[part 2 of 3: package /Svc_Dem]
AUTOSAR XML (schema 00047)
package /Svc_Dem  (continued)
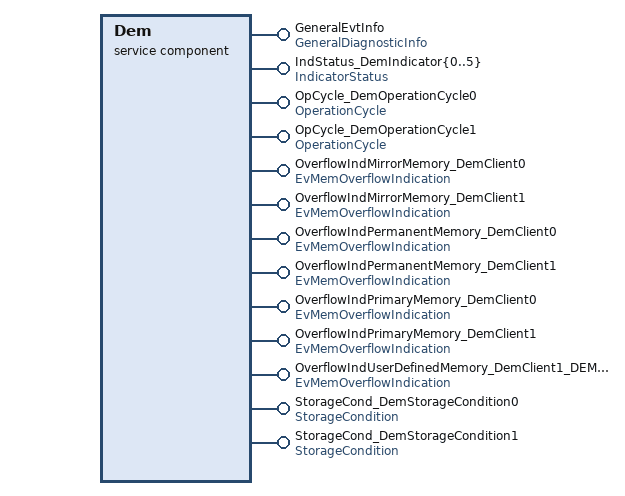
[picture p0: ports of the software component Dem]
  service sw component type Dem  (continued)
    18 x provide port:
      GeneralEvtInfo: provided-interface=GeneralDiagnosticInfo
        provided-com-specs:
          operation=GeneralDiagnosticInfo/GetDTCOfEvent, queue-length=1
          operation=GeneralDiagnosticInfo/GetDebouncingOfEvent, queue-length=1
          operation=GeneralDiagnosticInfo/GetEventUdsStatus, queue-length=1
          operation=GeneralDiagnosticInfo/GetFaultDetectionCounter, queue-length=1
          operation=GeneralDiagnosticInfo/GetMonitorStatus, queue-length=1
      IndStatus_DemIndicator{0..5}: server-com-spec{operation=GetIndicatorStatus, queue-length=1}, provided-interface=IndicatorStatus  # This port provides the Supervision interface of DemIndicator{0..5} to a SWC.
      OpCycle_DemOperationCycle0: provided-interface=OperationCycle  # This port provides the Supervision interface of DemOperationCycle0 to a SWC.
        provided-com-specs:
          operation=GetCycleQualified, queue-length=1
          operation=RestartOperationCycle, queue-length=1
          operation=SetCycleQualified, queue-length=1
      OpCycle_DemOperationCycle1: provided-interface=OperationCycle  # This port provides the Supervision interface of DemOperationCycle1 to a SWC.
        provided-com-specs:
          operation=GetCycleQualified, queue-length=1
          operation=RestartOperationCycle, queue-length=1
          operation=SetCycleQualified, queue-length=1
      OverflowIndMirrorMemory_DemClient0: provided-interface=EvMemOverflowIndication  # This port provides the Supervision interface of DemClient0 to a SWC.
        provided-com-specs:
          operation=GetEventMemoryOverflow, queue-length=1
          operation=GetNumberOfEventMemoryEntries, queue-length=1
      OverflowIndMirrorMemory_DemClient1: provided-interface=EvMemOverflowIndication  # This port provides the Supervision interface of DemClient1 to a SWC.
        provided-com-specs:
          operation=GetEventMemoryOverflow, queue-length=1
          operation=GetNumberOfEventMemoryEntries, queue-length=1
      OverflowIndPermanentMemory_DemClient0: provided-interface=EvMemOverflowIndication  # This port provides the Supervision interface of DemClient0 to a SWC.
        provided-com-specs:
          operation=GetEventMemoryOverflow, queue-length=1
          operation=GetNumberOfEventMemoryEntries, queue-length=1
      OverflowIndPermanentMemory_DemClient1: provided-interface=EvMemOverflowIndication  # This port provides the Supervision interface of DemClient1 to a SWC.
        provided-com-specs:
          operation=GetEventMemoryOverflow, queue-length=1
          operation=GetNumberOfEventMemoryEntries, queue-length=1
      OverflowIndPrimaryMemory_DemClient0: provided-interface=EvMemOverflowIndication  # This port provides the Supervision interface of DemClient0 to a SWC.
        provided-com-specs:
          operation=GetEventMemoryOverflow, queue-length=1
          operation=GetNumberOfEventMemoryEntries, queue-length=1
      OverflowIndPrimaryMemory_DemClient1: provided-interface=EvMemOverflowIndication  # This port provides the Supervision interface of DemClient1 to a SWC.
        provided-com-specs:
          operation=GetEventMemoryOverflow, queue-length=1
          operation=GetNumberOfEventMemoryEntries, queue-length=1
      OverflowIndUserDefinedMemory_DemClient1_DEMUSERDEFINEDMEMORY0: provided-interface=EvMemOverflowIndication
        provided-com-specs:
          operation=GetEventMemoryOverflow, queue-length=1
          operation=GetNumberOfEventMemoryEntries, queue-length=1
      StorageCond_DemStorageCondition0: server-com-spec{operation=SetStorageCondition, queue-length=1}, provided-interface=StorageCondition  # This port provides the Supervision interface of DemStorageCondition0 to a SWC.
      StorageCond_DemStorageCondition1: server-com-spec{operation=SetStorageCondition, queue-length=1}, provided-interface=StorageCondition  # This port provides the Supervision interface of DemStorageCondition1 to a SWC.
    behavior InternalBehavior: handle-termination-and-restart=NO-SUPPORT, included-data-type-set=data-type=[Dem_ComponentIdType, Dem_ConfigType, Dem_DTCFormatType, Dem_DTCKindType, Dem_DTCOriginType, Dem_DTCRequestType, Dem_DTCSeverityType, Dem_DTCTranslationFormatType, Dem_DTRControlType, Dem_DebounceResetStatusType, Dem_DebouncingStateType, Dem_EventIdType, Dem_EventStatusExtendedType, Dem_EventStatusType, Dem_IndicatorStatusType, Dem_InitMonitorReasonType, Dem_IumprDenomCondIdType, Dem_IumprDenomCondStatusType, Dem_MaxDataValueType, Dem_MonitorDataType, Dem_MonitorStatusType, Dem_PID21valueType, Dem_PID31valueType, Dem_RatioIdType, Dem_UdsStatusByteType]
      1431 x operation invoked event:
        OIE_ClearDTC_DemClient0_ClearDTC: start-on-event=ClearDTC, operation=ClearDTC_DemClient0.ClearDTC
        OIE_ClearDTC_DemClient0_SelectDTC: start-on-event=SelectDTC, operation=ClearDTC_DemClient0.SelectDTC
        OIE_ClearDTC_DemClient1_ClearDTC: start-on-event=ClearDTC, operation=ClearDTC_DemClient1.ClearDTC
        OIE_ClearDTC_DemClient1_SelectDTC: start-on-event=SelectDTC, operation=ClearDTC_DemClient1.SelectDTC
        OIE_ControlDTCSuppression_GetDTCSuppression: start-on-event=GetDTCSuppression, operation=ControlDTCSuppression.GetDTCSuppression
        OIE_ControlDTCSuppression_SetDTCSuppression: start-on-event=SetDTCSuppression, operation=ControlDTCSuppression.SetDTCSuppression
        OIE_ControlEventAvailable_CANCM_E_BAT_FAIL_SetEventAvailable: start-on-event=SetEventAvailable, operation=ControlEventAvailable_CANCM_E_BAT_FAIL.SetEventAvailable
        OIE_ControlEventAvailable_CANSM_E_BUS_OFF_FD_CAN1_SetEventAvailable: start-on-event=SetEventAvailable, operation=ControlEventAvailable_CANSM_E_BUS_OFF_FD_CAN1.SetEventAvailable
        OIE_ControlEventAvailable_CANSM_E_BUS_OFF_FD_CAN2_SetEventAvailable: start-on-event=SetEventAvailable, operation=ControlEventAvailable_CANSM_E_BUS_OFF_FD_CAN2.SetEventAvailable
        OIE_ControlEventAvailable_CANSM_E_BUS_OFF_HS_CAN1_SetEventAvailable: start-on-event=SetEventAvailable, operation=ControlEventAvailable_CANSM_E_BUS_OFF_HS_CAN1.SetEventAvailable
        OIE_ControlEventAvailable_CANSM_E_BUS_OFF_LS_CAN1_SetEventAvailable: start-on-event=SetEventAvailable, operation=ControlEventAvailable_CANSM_E_BUS_OFF_LS_CAN1.SetEventAvailable
        OIE_ControlEventAvailable_CANSM_E_BUS_OFF_Project_SetEventAvailable: start-on-event=SetEventAvailable, operation=ControlEventAvailable_CANSM_E_BUS_OFF_Project.SetEventAvailable
        OIE_ControlEventAvailable_CANSM_E_MODE_CHANGE_FD_CAN1_SetEventAvailable: start-on-event=SetEventAvailable, operation=ControlEventAvailable_CANSM_E_MODE_CHANGE_FD_CAN1.SetEventAvailable
        OIE_ControlEventAvailable_CANSM_E_MODE_CHANGE_FD_CAN2_SetEventAvailable: start-on-event=SetEventAvailable, operation=ControlEventAvailable_CANSM_E_MODE_CHANGE_FD_CAN2.SetEventAvailable
        OIE_ControlEventAvailable_CANSM_E_MODE_CHANGE_HS_CAN1_SetEventAvailable: start-on-event=SetEventAvailable, operation=ControlEventAvailable_CANSM_E_MODE_CHANGE_HS_CAN1.SetEventAvailable
        OIE_ControlEventAvailable_CANSM_E_MODE_CHANGE_LS_CAN1_SetEventAvailable: start-on-event=SetEventAvailable, operation=ControlEventAvailable_CANSM_E_MODE_CHANGE_LS_CAN1.SetEventAvailable
        OIE_ControlEventAvailable_CANSM_E_MODE_CHANGE_Project_SetEventAvailable: start-on-event=SetEventAvailable, operation=ControlEventAvailable_CANSM_E_MODE_CHANGE_Project.SetEventAvailable
        OIE_ControlEventAvailable_CANSM_E_MODE_REQUEST_TIMEOUT_FD_CAN1_SetEventAvailable: start-on-event=SetEventAvailable, operation=ControlEventAvailable_CANSM_E_MODE_REQUEST_TIMEOUT_FD_CAN1.SetEventAvailable
        OIE_ControlEventAvailable_CANSM_E_MODE_REQUEST_TIMEOUT_HS_CAN1_SetEventAvailable: start-on-event=SetEventAvailable, operation=ControlEventAvailable_CANSM_E_MODE_REQUEST_TIMEOUT_HS_CAN1.SetEventAvailable
        OIE_ControlEventAvailable_DEM_E_TEST_EVENT{10..19}_SetEventAvailable: start-on-event=SetEventAvailable, operation=ControlEventAvailable_DEM_E_TEST_EVENT{10..19}.SetEventAvailable
        OIE_ControlEventAvailable_DEM_E_TEST_EVENT1_SetEventAvailable: start-on-event=SetEventAvailable, operation=ControlEventAvailable_DEM_E_TEST_EVENT1.SetEventAvailable
        OIE_ControlEventAvailable_DEM_E_TEST_EVENT{20..22}_SetEventAvailable: start-on-event=SetEventAvailable, operation=ControlEventAvailable_DEM_E_TEST_EVENT{20..22}.SetEventAvailable
        OIE_ControlEventAvailable_DEM_E_TEST_EVENT{2..9}_SetEventAvailable: start-on-event=SetEventAvailable, operation=ControlEventAvailable_DEM_E_TEST_EVENT{2..9}.SetEventAvailable
        OIE_ControlEventAvailable_DEM_E_TEST_EVENT_E2EXF_MALFORMED_MESSAGE_SetEventAvailable: start-on-event=SetEventAvailable, operation=ControlEventAvailable_DEM_E_TEST_EVENT_E2EXF_MALFORMED_MESSAGE.SetEventAvailable
        OIE_ControlEventAvailable_DEM_E_TEST_EVENT_SOMEIPXF_MALFORMED_MESSAGE_SetEventAvailable: start-on-event=SetEventAvailable, operation=ControlEventAvailable_DEM_E_TEST_EVENT_SOMEIPXF_MALFORMED_MESSAGE.SetEventAvailable
        OIE_ControlEventAvailable_ECUM_E_CONFIGURATION_DATA_INCONSISTENT_SetEventAvailable: start-on-event=SetEventAvailable, operation=ControlEventAvailable_ECUM_E_CONFIGURATION_DATA_INCONSISTENT.SetEventAvailable
        OIE_ControlEventAvailable_ECUM_E_IMPROPER_CALLER_SetEventAvailable: start-on-event=SetEventAvailable, operation=ControlEventAvailable_ECUM_E_IMPROPER_CALLER.SetEventAvailable
        OIE_ControlEventAvailable_ECUM_E_RAM_CHECK_FAILED_SetEventAvailable: start-on-event=SetEventAvailable, operation=ControlEventAvailable_ECUM_E_RAM_CHECK_FAILED.SetEventAvailable
        OIE_ControlEventAvailable_EEP_E_COMPARE_FAILED_SetEventAvailable: start-on-event=SetEventAvailable, operation=ControlEventAvailable_EEP_E_COMPARE_FAILED.SetEventAvailable
        OIE_ControlEventAvailable_EEP_E_ERASE_FAILED_SetEventAvailable: start-on-event=SetEventAvailable, operation=ControlEventAvailable_EEP_E_ERASE_FAILED.SetEventAvailable
        OIE_ControlEventAvailable_EEP_E_READ_FAILED_SetEventAvailable: start-on-event=SetEventAvailable, operation=ControlEventAvailable_EEP_E_READ_FAILED.SetEventAvailable
        OIE_ControlEventAvailable_EEP_E_WRITE_FAILED_SetEventAvailable: start-on-event=SetEventAvailable, operation=ControlEventAvailable_EEP_E_WRITE_FAILED.SetEventAvailable
        OIE_ControlEventAvailable_ETHSM_E_LINK_DOWN_SetEventAvailable: start-on-event=SetEventAvailable, operation=ControlEventAvailable_ETHSM_E_LINK_DOWN.SetEventAvailable
        OIE_ControlEventAvailable_ETHTRCV_E_ACCESS_SetEventAvailable: start-on-event=SetEventAvailable, operation=ControlEventAvailable_ETHTRCV_E_ACCESS.SetEventAvailable
        OIE_ControlEventAvailable_ETH_E_ACCESS_SetEventAvailable: start-on-event=SetEventAvailable, operation=ControlEventAvailable_ETH_E_ACCESS.SetEventAvailable
        OIE_ControlEventAvailable_ETH_E_ALIGNMENT_SetEventAvailable: start-on-event=SetEventAvailable, operation=ControlEventAvailable_ETH_E_ALIGNMENT.SetEventAvailable
        OIE_ControlEventAvailable_ETH_E_CRC_SetEventAvailable: start-on-event=SetEventAvailable, operation=ControlEventAvailable_ETH_E_CRC.SetEventAvailable
        OIE_ControlEventAvailable_ETH_E_LATECOLLISON_SetEventAvailable: start-on-event=SetEventAvailable, operation=ControlEventAvailable_ETH_E_LATECOLLISON.SetEventAvailable
        OIE_ControlEventAvailable_ETH_E_MULTIPLECOLLISION_SetEventAvailable: start-on-event=SetEventAvailable, operation=ControlEventAvailable_ETH_E_MULTIPLECOLLISION.SetEventAvailable
        OIE_ControlEventAvailable_ETH_E_OVERSIZEFRAME_SetEventAvailable: start-on-event=SetEventAvailable, operation=ControlEventAvailable_ETH_E_OVERSIZEFRAME.SetEventAvailable
        OIE_ControlEventAvailable_ETH_E_RX_FRAMES_LOST_SetEventAvailable: start-on-event=SetEventAvailable, operation=ControlEventAvailable_ETH_E_RX_FRAMES_LOST.SetEventAvailable
        OIE_ControlEventAvailable_ETH_E_SINGLECOLLISION_SetEventAvailable: start-on-event=SetEventAvailable, operation=ControlEventAvailable_ETH_E_SINGLECOLLISION.SetEventAvailable
        OIE_ControlEventAvailable_ETH_E_UNDERSIZRFRAME_SetEventAvailable: start-on-event=SetEventAvailable, operation=ControlEventAvailable_ETH_E_UNDERSIZRFRAME.SetEventAvailable
        OIE_ControlEventAvailable_FEE_E_GC_ERASE_SetEventAvailable: start-on-event=SetEventAvailable, operation=ControlEventAvailable_FEE_E_GC_ERASE.SetEventAvailable
        OIE_ControlEventAvailable_FEE_E_GC_INIT_SetEventAvailable: start-on-event=SetEventAvailable, operation=ControlEventAvailable_FEE_E_GC_INIT.SetEventAvailable
        OIE_ControlEventAvailable_FEE_E_GC_READ_SetEventAvailable: start-on-event=SetEventAvailable, operation=ControlEventAvailable_FEE_E_GC_READ.SetEventAvailable
        OIE_ControlEventAvailable_FEE_E_GC_TRIG_SetEventAvailable: start-on-event=SetEventAvailable, operation=ControlEventAvailable_FEE_E_GC_TRIG.SetEventAvailable
        OIE_ControlEventAvailable_FEE_E_GC_WRITE_SetEventAvailable: start-on-event=SetEventAvailable, operation=ControlEventAvailable_FEE_E_GC_WRITE.SetEventAvailable
        OIE_ControlEventAvailable_FEE_E_INVALIDATE_SetEventAvailable: start-on-event=SetEventAvailable, operation=ControlEventAvailable_FEE_E_INVALIDATE.SetEventAvailable
        OIE_ControlEventAvailable_FEE_E_READ_SetEventAvailable: start-on-event=SetEventAvailable, operation=ControlEventAvailable_FEE_E_READ.SetEventAvailable
        OIE_ControlEventAvailable_FEE_E_UNCONFIG_BLK_EXCEEDED_SetEventAvailable: start-on-event=SetEventAvailable, operation=ControlEventAvailable_FEE_E_UNCONFIG_BLK_EXCEEDED.SetEventAvailable
        OIE_ControlEventAvailable_FEE_E_WRITE_CYCLES_EXHAUSTED_SetEventAvailable: start-on-event=SetEventAvailable, operation=ControlEventAvailable_FEE_E_WRITE_CYCLES_EXHAUSTED.SetEventAvailable
        OIE_ControlEventAvailable_FEE_E_WRITE_SetEventAvailable: start-on-event=SetEventAvailable, operation=ControlEventAvailable_FEE_E_WRITE.SetEventAvailable
        OIE_ControlEventAvailable_FLS_E_COMPARE_FAILED_SetEventAvailable: start-on-event=SetEventAvailable, operation=ControlEventAvailable_FLS_E_COMPARE_FAILED.SetEventAvailable
        OIE_ControlEventAvailable_FLS_E_ERASE_FAILED_SetEventAvailable: start-on-event=SetEventAvailable, operation=ControlEventAvailable_FLS_E_ERASE_FAILED.SetEventAvailable
        OIE_ControlEventAvailable_FLS_E_READ_FAILED_SetEventAvailable: start-on-event=SetEventAvailable, operation=ControlEventAvailable_FLS_E_READ_FAILED.SetEventAvailable
        OIE_ControlEventAvailable_FLS_E_UNEXPECTED_FLASH_ID_SetEventAvailable: start-on-event=SetEventAvailable, operation=ControlEventAvailable_FLS_E_UNEXPECTED_FLASH_ID.SetEventAvailable
        OIE_ControlEventAvailable_FLS_E_WRITE_FAILED_SetEventAvailable: start-on-event=SetEventAvailable, operation=ControlEventAvailable_FLS_E_WRITE_FAILED.SetEventAvailable
        OIE_ControlEventAvailable_IOHWAB_E_BUSY_SetEventAvailable: start-on-event=SetEventAvailable, operation=ControlEventAvailable_IOHWAB_E_BUSY.SetEventAvailable
        OIE_ControlEventAvailable_IOHWAB_E_PROC_FAIL_SetEventAvailable: start-on-event=SetEventAvailable, operation=ControlEventAvailable_IOHWAB_E_PROC_FAIL.SetEventAvailable
        OIE_ControlEventAvailable_IOHWAB_E_SETUP_FAIL_SetEventAvailable: start-on-event=SetEventAvailable, operation=ControlEventAvailable_IOHWAB_E_SETUP_FAIL.SetEventAvailable
        OIE_ControlEventAvailable_IOHWAB_E_WRONG_PARAM_SetEventAvailable: start-on-event=SetEventAvailable, operation=ControlEventAvailable_IOHWAB_E_WRONG_PARAM.SetEventAvailable
        OIE_ControlEventAvailable_IOHWAB_E_WRONG_SETTING_SetEventAvailable: start-on-event=SetEventAvailable, operation=ControlEventAvailable_IOHWAB_E_WRONG_SETTING.SetEventAvailable
        OIE_ControlEventAvailable_IOHWAB_E_WRONG_STATE_SetEventAvailable: start-on-event=SetEventAvailable, operation=ControlEventAvailable_IOHWAB_E_WRONG_STATE.SetEventAvailable
        OIE_ControlEventAvailable_MCU_E_CCU6_CLC_DISABLE_ERR_SetEventAvailable: start-on-event=SetEventAvailable, operation=ControlEventAvailable_MCU_E_CCU6_CLC_DISABLE_ERR.SetEventAvailable
        OIE_ControlEventAvailable_MCU_E_CCU6_CLC_ENABLE_ERR_SetEventAvailable: start-on-event=SetEventAvailable, operation=ControlEventAvailable_MCU_E_CCU6_CLC_ENABLE_ERR.SetEventAvailable
        OIE_ControlEventAvailable_MCU_E_CCUCON_UPDATE_ERR_SetEventAvailable: start-on-event=SetEventAvailable, operation=ControlEventAvailable_MCU_E_CCUCON_UPDATE_ERR.SetEventAvailable
        OIE_ControlEventAvailable_MCU_E_CLOCK_FAILURE_SetEventAvailable: start-on-event=SetEventAvailable, operation=ControlEventAvailable_MCU_E_CLOCK_FAILURE.SetEventAvailable
        OIE_ControlEventAvailable_MCU_E_CONVCTRL_CLC_DISABLE_ERR_SetEventAvailable: start-on-event=SetEventAvailable, operation=ControlEventAvailable_MCU_E_CONVCTRL_CLC_DISABLE_ERR.SetEventAvailable
        OIE_ControlEventAvailable_MCU_E_CONVCTRL_CLC_ENABLE_ERR_SetEventAvailable: start-on-event=SetEventAvailable, operation=ControlEventAvailable_MCU_E_CONVCTRL_CLC_ENABLE_ERR.SetEventAvailable
        OIE_ControlEventAvailable_MCU_E_GPT12_CLC_DISABLE_ERR_SetEventAvailable: start-on-event=SetEventAvailable, operation=ControlEventAvailable_MCU_E_GPT12_CLC_DISABLE_ERR.SetEventAvailable
        OIE_ControlEventAvailable_MCU_E_GPT12_CLC_ENABLE_ERR_SetEventAvailable: start-on-event=SetEventAvailable, operation=ControlEventAvailable_MCU_E_GPT12_CLC_ENABLE_ERR.SetEventAvailable
        OIE_ControlEventAvailable_MCU_E_GTM_CLC_DISABLE_ERR_SetEventAvailable: start-on-event=SetEventAvailable, operation=ControlEventAvailable_MCU_E_GTM_CLC_DISABLE_ERR.SetEventAvailable
        OIE_ControlEventAvailable_MCU_E_GTM_CLC_ENABLE_ERR_SetEventAvailable: start-on-event=SetEventAvailable, operation=ControlEventAvailable_MCU_E_GTM_CLC_ENABLE_ERR.SetEventAvailable
        OIE_ControlEventAvailable_MCU_E_OSC_FAILURE_SetEventAvailable: start-on-event=SetEventAvailable, operation=ControlEventAvailable_MCU_E_OSC_FAILURE.SetEventAvailable
        OIE_ControlEventAvailable_MCU_E_PERIPHERAL_PLL_LOCK_LOSS_SetEventAvailable: start-on-event=SetEventAvailable, operation=ControlEventAvailable_MCU_E_PERIPHERAL_PLL_LOCK_LOSS.SetEventAvailable
        OIE_ControlEventAvailable_MCU_E_PERIPHERAL_PLL_TIMEOUT_ERR_SetEventAvailable: start-on-event=SetEventAvailable, operation=ControlEventAvailable_MCU_E_PERIPHERAL_PLL_TIMEOUT_ERR.SetEventAvailable
        OIE_ControlEventAvailable_MCU_E_PMSWCR_UPDATE_ERR_SetEventAvailable: start-on-event=SetEventAvailable, operation=ControlEventAvailable_MCU_E_PMSWCR_UPDATE_ERR.SetEventAvailable
        OIE_ControlEventAvailable_MCU_E_SYSTEM_PLL_LOCK_LOSS_SetEventAvailable: start-on-event=SetEventAvailable, operation=ControlEventAvailable_MCU_E_SYSTEM_PLL_LOCK_LOSS.SetEventAvailable
        OIE_ControlEventAvailable_MCU_E_SYSTEM_PLL_TIMEOUT_ERR_SetEventAvailable: start-on-event=SetEventAvailable, operation=ControlEventAvailable_MCU_E_SYSTEM_PLL_TIMEOUT_ERR.SetEventAvailable
        OIE_ControlEventAvailable_NVM_E_INTEGRITY_FAILED_SetEventAvailable: start-on-event=SetEventAvailable, operation=ControlEventAvailable_NVM_E_INTEGRITY_FAILED.SetEventAvailable
        OIE_ControlEventAvailable_NVM_E_LOSS_OF_REDUNDANCY_SetEventAvailable: start-on-event=SetEventAvailable, operation=ControlEventAvailable_NVM_E_LOSS_OF_REDUNDANCY.SetEventAvailable
        OIE_ControlEventAvailable_NVM_E_QUEUE_OVERFLOW_SetEventAvailable: start-on-event=SetEventAvailable, operation=ControlEventAvailable_NVM_E_QUEUE_OVERFLOW.SetEventAvailable
        OIE_ControlEventAvailable_NVM_E_REQ_FAILED_SetEventAvailable: start-on-event=SetEventAvailable, operation=ControlEventAvailable_NVM_E_REQ_FAILED.SetEventAvailable
        OIE_ControlEventAvailable_NVM_E_VERIFY_FAILED_SetEventAvailable: start-on-event=SetEventAvailable, operation=ControlEventAvailable_NVM_E_VERIFY_FAILED.SetEventAvailable
        OIE_ControlEventAvailable_NVM_E_WRITE_PROTECTED_SetEventAvailable: start-on-event=SetEventAvailable, operation=ControlEventAvailable_NVM_E_WRITE_PROTECTED.SetEventAvailable
        OIE_ControlEventAvailable_NVM_E_WRONG_BLOCK_ID_SetEventAvailable: start-on-event=SetEventAvailable, operation=ControlEventAvailable_NVM_E_WRONG_BLOCK_ID.SetEventAvailable
        OIE_ControlEventAvailable_SPI_E_HARDWARE_ERROR_SetEventAvailable: start-on-event=SetEventAvailable, operation=ControlEventAvailable_SPI_E_HARDWARE_ERROR.SetEventAvailable
        OIE_ControlEventAvailable_WDGM_E_IMPROPER_CALLER_SetEventAvailable: start-on-event=SetEventAvailable, operation=ControlEventAvailable_WDGM_E_IMPROPER_CALLER.SetEventAvailable
        OIE_ControlEventAvailable_WDGM_E_MONITORING_SetEventAvailable: start-on-event=SetEventAvailable, operation=ControlEventAvailable_WDGM_E_MONITORING.SetEventAvailable
        OIE_ControlEventAvailable_WDGM_E_SET_MODE_SetEventAvailable: start-on-event=SetEventAvailable, operation=ControlEventAvailable_WDGM_E_SET_MODE.SetEventAvailable
        OIE_ControlEventAvailable_WDG_76_ACW_E_DISABLE_REJECTED_SetEventAvailable: start-on-event=SetEventAvailable, operation=ControlEventAvailable_WDG_76_ACW_E_DISABLE_REJECTED.SetEventAvailable
        OIE_ControlEventAvailable_WDG_76_ACW_E_MODE_FAILED_SetEventAvailable: start-on-event=SetEventAvailable, operation=ControlEventAvailable_WDG_76_ACW_E_MODE_FAILED.SetEventAvailable
        OIE_ControlEventAvailable_WDG_E_DISABLE_REJECTED_SetEventAvailable: start-on-event=SetEventAvailable, operation=ControlEventAvailable_WDG_E_DISABLE_REJECTED.SetEventAvailable
        OIE_ControlEventAvailable_WDG_E_MODE_FAILED_SetEventAvailable: start-on-event=SetEventAvailable, operation=ControlEventAvailable_WDG_E_MODE_FAILED.SetEventAvailable
        OIE_DiagnosticMonitor_MonitorData_CANCM_E_BAT_FAIL_SetEventStatusWithMonitorData: start-on-event=SetEventStatusWithMonitorData, operation=DiagnosticMonitor_MonitorData_CANCM_E_BAT_FAIL.SetEventStatusWithMonitorData
        OIE_DiagnosticMonitor_MonitorData_CANSM_E_BUS_OFF_FD_CAN1_SetEventStatusWithMonitorData: start-on-event=SetEventStatusWithMonitorData, operation=DiagnosticMonitor_MonitorData_CANSM_E_BUS_OFF_FD_CAN1.SetEventStatusWithMonitorData
        OIE_DiagnosticMonitor_MonitorData_CANSM_E_BUS_OFF_FD_CAN2_SetEventStatusWithMonitorData: start-on-event=SetEventStatusWithMonitorData, operation=DiagnosticMonitor_MonitorData_CANSM_E_BUS_OFF_FD_CAN2.SetEventStatusWithMonitorData
        OIE_DiagnosticMonitor_MonitorData_CANSM_E_BUS_OFF_HS_CAN1_SetEventStatusWithMonitorData: start-on-event=SetEventStatusWithMonitorData, operation=DiagnosticMonitor_MonitorData_CANSM_E_BUS_OFF_HS_CAN1.SetEventStatusWithMonitorData
        OIE_DiagnosticMonitor_MonitorData_CANSM_E_BUS_OFF_LS_CAN1_SetEventStatusWithMonitorData: start-on-event=SetEventStatusWithMonitorData, operation=DiagnosticMonitor_MonitorData_CANSM_E_BUS_OFF_LS_CAN1.SetEventStatusWithMonitorData
        OIE_DiagnosticMonitor_MonitorData_CANSM_E_BUS_OFF_Project_SetEventStatusWithMonitorData: start-on-event=SetEventStatusWithMonitorData, operation=DiagnosticMonitor_MonitorData_CANSM_E_BUS_OFF_Project.SetEventStatusWithMonitorData
        OIE_DiagnosticMonitor_MonitorData_CANSM_E_MODE_CHANGE_FD_CAN1_SetEventStatusWithMonitorData: start-on-event=SetEventStatusWithMonitorData, operation=DiagnosticMonitor_MonitorData_CANSM_E_MODE_CHANGE_FD_CAN1.SetEventStatusWithMonitorData
        OIE_DiagnosticMonitor_MonitorData_CANSM_E_MODE_CHANGE_FD_CAN2_SetEventStatusWithMonitorData: start-on-event=SetEventStatusWithMonitorData, operation=DiagnosticMonitor_MonitorData_CANSM_E_MODE_CHANGE_FD_CAN2.SetEventStatusWithMonitorData
        OIE_DiagnosticMonitor_MonitorData_CANSM_E_MODE_CHANGE_HS_CAN1_SetEventStatusWithMonitorData: start-on-event=SetEventStatusWithMonitorData, operation=DiagnosticMonitor_MonitorData_CANSM_E_MODE_CHANGE_HS_CAN1.SetEventStatusWithMonitorData
        OIE_DiagnosticMonitor_MonitorData_CANSM_E_MODE_CHANGE_LS_CAN1_SetEventStatusWithMonitorData: start-on-event=SetEventStatusWithMonitorData, operation=DiagnosticMonitor_MonitorData_CANSM_E_MODE_CHANGE_LS_CAN1.SetEventStatusWithMonitorData
        OIE_DiagnosticMonitor_MonitorData_CANSM_E_MODE_CHANGE_Project_SetEventStatusWithMonitorData: start-on-event=SetEventStatusWithMonitorData, operation=DiagnosticMonitor_MonitorData_CANSM_E_MODE_CHANGE_Project.SetEventStatusWithMonitorData
        OIE_DiagnosticMonitor_MonitorData_CANSM_E_MODE_REQUEST_TIMEOUT_FD_CAN1_SetEventStatusWithMonitorData: start-on-event=SetEventStatusWithMonitorData, operation=DiagnosticMonitor_MonitorData_CANSM_E_MODE_REQUEST_TIMEOUT_FD_CAN1.SetEventStatusWithMonitorData
        OIE_DiagnosticMonitor_MonitorData_CANSM_E_MODE_REQUEST_TIMEOUT_HS_CAN1_SetEventStatusWithMonitorData: start-on-event=SetEventStatusWithMonitorData, operation=DiagnosticMonitor_MonitorData_CANSM_E_MODE_REQUEST_TIMEOUT_HS_CAN1.SetEventStatusWithMonitorData
        OIE_DiagnosticMonitor_MonitorData_DEM_E_TEST_EVENT{10..19}_SetEventStatusWithMonitorData: start-on-event=SetEventStatusWithMonitorData, operation=DiagnosticMonitor_MonitorData_DEM_E_TEST_EVENT{10..19}.SetEventStatusWithMonitorData
        OIE_DiagnosticMonitor_MonitorData_DEM_E_TEST_EVENT1_SetEventStatusWithMonitorData: start-on-event=SetEventStatusWithMonitorData, operation=DiagnosticMonitor_MonitorData_DEM_E_TEST_EVENT1.SetEventStatusWithMonitorData
        OIE_DiagnosticMonitor_MonitorData_DEM_E_TEST_EVENT{20..22}_SetEventStatusWithMonitorData: start-on-event=SetEventStatusWithMonitorData, operation=DiagnosticMonitor_MonitorData_DEM_E_TEST_EVENT{20..22}.SetEventStatusWithMonitorData
        OIE_DiagnosticMonitor_MonitorData_DEM_E_TEST_EVENT{2..9}_SetEventStatusWithMonitorData: start-on-event=SetEventStatusWithMonitorData, operation=DiagnosticMonitor_MonitorData_DEM_E_TEST_EVENT{2..9}.SetEventStatusWithMonitorData
        OIE_DiagnosticMonitor_MonitorData_DEM_E_TEST_EVENT_E2EXF_MALFORMED_MESSAGE_SetEventStatusWithMonitorData: start-on-event=SetEventStatusWithMonitorData, operation=DiagnosticMonitor_MonitorData_DEM_E_TEST_EVENT_E2EXF_MALFORMED_MESSAGE.SetEventStatusWithMonitorData
        OIE_DiagnosticMonitor_MonitorData_DEM_E_TEST_EVENT_SOMEIPXF_MALFORMED_MESSAGE_SetEventStatusWithMonitorData: start-on-event=SetEventStatusWithMonitorData, operation=DiagnosticMonitor_MonitorData_DEM_E_TEST_EVENT_SOMEIPXF_MALFORMED_MESSAGE.SetEventStatusWithMonitorData
        OIE_DiagnosticMonitor_MonitorData_ECUM_E_CONFIGURATION_DATA_INCONSISTENT_SetEventStatusWithMonitorData: start-on-event=SetEventStatusWithMonitorData, operation=DiagnosticMonitor_MonitorData_ECUM_E_CONFIGURATION_DATA_INCONSISTENT.SetEventStatusWithMonitorData
        OIE_DiagnosticMonitor_MonitorData_ECUM_E_IMPROPER_CALLER_SetEventStatusWithMonitorData: start-on-event=SetEventStatusWithMonitorData, operation=DiagnosticMonitor_MonitorData_ECUM_E_IMPROPER_CALLER.SetEventStatusWithMonitorData
        OIE_DiagnosticMonitor_MonitorData_ECUM_E_RAM_CHECK_FAILED_SetEventStatusWithMonitorData: start-on-event=SetEventStatusWithMonitorData, operation=DiagnosticMonitor_MonitorData_ECUM_E_RAM_CHECK_FAILED.SetEventStatusWithMonitorData
        OIE_DiagnosticMonitor_MonitorData_EEP_E_COMPARE_FAILED_SetEventStatusWithMonitorData: start-on-event=SetEventStatusWithMonitorData, operation=DiagnosticMonitor_MonitorData_EEP_E_COMPARE_FAILED.SetEventStatusWithMonitorData
        OIE_DiagnosticMonitor_MonitorData_EEP_E_ERASE_FAILED_SetEventStatusWithMonitorData: start-on-event=SetEventStatusWithMonitorData, operation=DiagnosticMonitor_MonitorData_EEP_E_ERASE_FAILED.SetEventStatusWithMonitorData
        OIE_DiagnosticMonitor_MonitorData_EEP_E_READ_FAILED_SetEventStatusWithMonitorData: start-on-event=SetEventStatusWithMonitorData, operation=DiagnosticMonitor_MonitorData_EEP_E_READ_FAILED.SetEventStatusWithMonitorData
        OIE_DiagnosticMonitor_MonitorData_EEP_E_WRITE_FAILED_SetEventStatusWithMonitorData: start-on-event=SetEventStatusWithMonitorData, operation=DiagnosticMonitor_MonitorData_EEP_E_WRITE_FAILED.SetEventStatusWithMonitorData
        OIE_DiagnosticMonitor_MonitorData_ETHSM_E_LINK_DOWN_SetEventStatusWithMonitorData: start-on-event=SetEventStatusWithMonitorData, operation=DiagnosticMonitor_MonitorData_ETHSM_E_LINK_DOWN.SetEventStatusWithMonitorData
        OIE_DiagnosticMonitor_MonitorData_ETHTRCV_E_ACCESS_SetEventStatusWithMonitorData: start-on-event=SetEventStatusWithMonitorData, operation=DiagnosticMonitor_MonitorData_ETHTRCV_E_ACCESS.SetEventStatusWithMonitorData
        OIE_DiagnosticMonitor_MonitorData_ETH_E_ACCESS_SetEventStatusWithMonitorData: start-on-event=SetEventStatusWithMonitorData, operation=DiagnosticMonitor_MonitorData_ETH_E_ACCESS.SetEventStatusWithMonitorData
        OIE_DiagnosticMonitor_MonitorData_ETH_E_ALIGNMENT_SetEventStatusWithMonitorData: start-on-event=SetEventStatusWithMonitorData, operation=DiagnosticMonitor_MonitorData_ETH_E_ALIGNMENT.SetEventStatusWithMonitorData
        OIE_DiagnosticMonitor_MonitorData_ETH_E_CRC_SetEventStatusWithMonitorData: start-on-event=SetEventStatusWithMonitorData, operation=DiagnosticMonitor_MonitorData_ETH_E_CRC.SetEventStatusWithMonitorData
        OIE_DiagnosticMonitor_MonitorData_ETH_E_LATECOLLISON_SetEventStatusWithMonitorData: start-on-event=SetEventStatusWithMonitorData, operation=DiagnosticMonitor_MonitorData_ETH_E_LATECOLLISON.SetEventStatusWithMonitorData
        OIE_DiagnosticMonitor_MonitorData_ETH_E_MULTIPLECOLLISION_SetEventStatusWithMonitorData: start-on-event=SetEventStatusWithMonitorData, operation=DiagnosticMonitor_MonitorData_ETH_E_MULTIPLECOLLISION.SetEventStatusWithMonitorData
        OIE_DiagnosticMonitor_MonitorData_ETH_E_OVERSIZEFRAME_SetEventStatusWithMonitorData: start-on-event=SetEventStatusWithMonitorData, operation=DiagnosticMonitor_MonitorData_ETH_E_OVERSIZEFRAME.SetEventStatusWithMonitorData
        OIE_DiagnosticMonitor_MonitorData_ETH_E_RX_FRAMES_LOST_SetEventStatusWithMonitorData: start-on-event=SetEventStatusWithMonitorData, operation=DiagnosticMonitor_MonitorData_ETH_E_RX_FRAMES_LOST.SetEventStatusWithMonitorData
        OIE_DiagnosticMonitor_MonitorData_ETH_E_SINGLECOLLISION_SetEventStatusWithMonitorData: start-on-event=SetEventStatusWithMonitorData, operation=DiagnosticMonitor_MonitorData_ETH_E_SINGLECOLLISION.SetEventStatusWithMonitorData
        OIE_DiagnosticMonitor_MonitorData_ETH_E_UNDERSIZRFRAME_SetEventStatusWithMonitorData: start-on-event=SetEventStatusWithMonitorData, operation=DiagnosticMonitor_MonitorData_ETH_E_UNDERSIZRFRAME.SetEventStatusWithMonitorData
        OIE_DiagnosticMonitor_MonitorData_FEE_E_GC_ERASE_SetEventStatusWithMonitorData: start-on-event=SetEventStatusWithMonitorData, operation=DiagnosticMonitor_MonitorData_FEE_E_GC_ERASE.SetEventStatusWithMonitorData
        OIE_DiagnosticMonitor_MonitorData_FEE_E_GC_INIT_SetEventStatusWithMonitorData: start-on-event=SetEventStatusWithMonitorData, operation=DiagnosticMonitor_MonitorData_FEE_E_GC_INIT.SetEventStatusWithMonitorData
        OIE_DiagnosticMonitor_MonitorData_FEE_E_GC_READ_SetEventStatusWithMonitorData: start-on-event=SetEventStatusWithMonitorData, operation=DiagnosticMonitor_MonitorData_FEE_E_GC_READ.SetEventStatusWithMonitorData
        OIE_DiagnosticMonitor_MonitorData_FEE_E_GC_TRIG_SetEventStatusWithMonitorData: start-on-event=SetEventStatusWithMonitorData, operation=DiagnosticMonitor_MonitorData_FEE_E_GC_TRIG.SetEventStatusWithMonitorData
        OIE_DiagnosticMonitor_MonitorData_FEE_E_GC_WRITE_SetEventStatusWithMonitorData: start-on-event=SetEventStatusWithMonitorData, operation=DiagnosticMonitor_MonitorData_FEE_E_GC_WRITE.SetEventStatusWithMonitorData
        OIE_DiagnosticMonitor_MonitorData_FEE_E_INVALIDATE_SetEventStatusWithMonitorData: start-on-event=SetEventStatusWithMonitorData, operation=DiagnosticMonitor_MonitorData_FEE_E_INVALIDATE.SetEventStatusWithMonitorData
        OIE_DiagnosticMonitor_MonitorData_FEE_E_READ_SetEventStatusWithMonitorData: start-on-event=SetEventStatusWithMonitorData, operation=DiagnosticMonitor_MonitorData_FEE_E_READ.SetEventStatusWithMonitorData
        OIE_DiagnosticMonitor_MonitorData_FEE_E_UNCONFIG_BLK_EXCEEDED_SetEventStatusWithMonitorData: start-on-event=SetEventStatusWithMonitorData, operation=DiagnosticMonitor_MonitorData_FEE_E_UNCONFIG_BLK_EXCEEDED.SetEventStatusWithMonitorData
        OIE_DiagnosticMonitor_MonitorData_FEE_E_WRITE_CYCLES_EXHAUSTED_SetEventStatusWithMonitorData: start-on-event=SetEventStatusWithMonitorData, operation=DiagnosticMonitor_MonitorData_FEE_E_WRITE_CYCLES_EXHAUSTED.SetEventStatusWithMonitorData
        OIE_DiagnosticMonitor_MonitorData_FEE_E_WRITE_SetEventStatusWithMonitorData: start-on-event=SetEventStatusWithMonitorData, operation=DiagnosticMonitor_MonitorData_FEE_E_WRITE.SetEventStatusWithMonitorData
        OIE_DiagnosticMonitor_MonitorData_FLS_E_COMPARE_FAILED_SetEventStatusWithMonitorData: start-on-event=SetEventStatusWithMonitorData, operation=DiagnosticMonitor_MonitorData_FLS_E_COMPARE_FAILED.SetEventStatusWithMonitorData
        OIE_DiagnosticMonitor_MonitorData_FLS_E_ERASE_FAILED_SetEventStatusWithMonitorData: start-on-event=SetEventStatusWithMonitorData, operation=DiagnosticMonitor_MonitorData_FLS_E_ERASE_FAILED.SetEventStatusWithMonitorData
        OIE_DiagnosticMonitor_MonitorData_FLS_E_READ_FAILED_SetEventStatusWithMonitorData: start-on-event=SetEventStatusWithMonitorData, operation=DiagnosticMonitor_MonitorData_FLS_E_READ_FAILED.SetEventStatusWithMonitorData
        OIE_DiagnosticMonitor_MonitorData_FLS_E_UNEXPECTED_FLASH_ID_SetEventStatusWithMonitorData: start-on-event=SetEventStatusWithMonitorData, operation=DiagnosticMonitor_MonitorData_FLS_E_UNEXPECTED_FLASH_ID.SetEventStatusWithMonitorData
        OIE_DiagnosticMonitor_MonitorData_FLS_E_WRITE_FAILED_SetEventStatusWithMonitorData: start-on-event=SetEventStatusWithMonitorData, operation=DiagnosticMonitor_MonitorData_FLS_E_WRITE_FAILED.SetEventStatusWithMonitorData
        OIE_DiagnosticMonitor_MonitorData_IOHWAB_E_BUSY_SetEventStatusWithMonitorData: start-on-event=SetEventStatusWithMonitorData, operation=DiagnosticMonitor_MonitorData_IOHWAB_E_BUSY.SetEventStatusWithMonitorData
        OIE_DiagnosticMonitor_MonitorData_IOHWAB_E_PROC_FAIL_SetEventStatusWithMonitorData: start-on-event=SetEventStatusWithMonitorData, operation=DiagnosticMonitor_MonitorData_IOHWAB_E_PROC_FAIL.SetEventStatusWithMonitorData
        OIE_DiagnosticMonitor_MonitorData_IOHWAB_E_SETUP_FAIL_SetEventStatusWithMonitorData: start-on-event=SetEventStatusWithMonitorData, operation=DiagnosticMonitor_MonitorData_IOHWAB_E_SETUP_FAIL.SetEventStatusWithMonitorData
        OIE_DiagnosticMonitor_MonitorData_IOHWAB_E_WRONG_PARAM_SetEventStatusWithMonitorData: start-on-event=SetEventStatusWithMonitorData, operation=DiagnosticMonitor_MonitorData_IOHWAB_E_WRONG_PARAM.SetEventStatusWithMonitorData
        OIE_DiagnosticMonitor_MonitorData_IOHWAB_E_WRONG_SETTING_SetEventStatusWithMonitorData: start-on-event=SetEventStatusWithMonitorData, operation=DiagnosticMonitor_MonitorData_IOHWAB_E_WRONG_SETTING.SetEventStatusWithMonitorData
        OIE_DiagnosticMonitor_MonitorData_IOHWAB_E_WRONG_STATE_SetEventStatusWithMonitorData: start-on-event=SetEventStatusWithMonitorData, operation=DiagnosticMonitor_MonitorData_IOHWAB_E_WRONG_STATE.SetEventStatusWithMonitorData
        OIE_DiagnosticMonitor_MonitorData_MCU_E_CCU6_CLC_DISABLE_ERR_SetEventStatusWithMonitorData: start-on-event=SetEventStatusWithMonitorData, operation=DiagnosticMonitor_MonitorData_MCU_E_CCU6_CLC_DISABLE_ERR.SetEventStatusWithMonitorData
        OIE_DiagnosticMonitor_MonitorData_MCU_E_CCU6_CLC_ENABLE_ERR_SetEventStatusWithMonitorData: start-on-event=SetEventStatusWithMonitorData, operation=DiagnosticMonitor_MonitorData_MCU_E_CCU6_CLC_ENABLE_ERR.SetEventStatusWithMonitorData
        OIE_DiagnosticMonitor_MonitorData_MCU_E_CCUCON_UPDATE_ERR_SetEventStatusWithMonitorData: start-on-event=SetEventStatusWithMonitorData, operation=DiagnosticMonitor_MonitorData_MCU_E_CCUCON_UPDATE_ERR.SetEventStatusWithMonitorData
        OIE_DiagnosticMonitor_MonitorData_MCU_E_CLOCK_FAILURE_SetEventStatusWithMonitorData: start-on-event=SetEventStatusWithMonitorData, operation=DiagnosticMonitor_MonitorData_MCU_E_CLOCK_FAILURE.SetEventStatusWithMonitorData
        OIE_DiagnosticMonitor_MonitorData_MCU_E_CONVCTRL_CLC_DISABLE_ERR_SetEventStatusWithMonitorData: start-on-event=SetEventStatusWithMonitorData, operation=DiagnosticMonitor_MonitorData_MCU_E_CONVCTRL_CLC_DISABLE_ERR.SetEventStatusWithMonitorData
        OIE_DiagnosticMonitor_MonitorData_MCU_E_CONVCTRL_CLC_ENABLE_ERR_SetEventStatusWithMonitorData: start-on-event=SetEventStatusWithMonitorData, operation=DiagnosticMonitor_MonitorData_MCU_E_CONVCTRL_CLC_ENABLE_ERR.SetEventStatusWithMonitorData
        OIE_DiagnosticMonitor_MonitorData_MCU_E_GPT12_CLC_DISABLE_ERR_SetEventStatusWithMonitorData: start-on-event=SetEventStatusWithMonitorData, operation=DiagnosticMonitor_MonitorData_MCU_E_GPT12_CLC_DISABLE_ERR.SetEventStatusWithMonitorData
        OIE_DiagnosticMonitor_MonitorData_MCU_E_GPT12_CLC_ENABLE_ERR_SetEventStatusWithMonitorData: start-on-event=SetEventStatusWithMonitorData, operation=DiagnosticMonitor_MonitorData_MCU_E_GPT12_CLC_ENABLE_ERR.SetEventStatusWithMonitorData
        OIE_DiagnosticMonitor_MonitorData_MCU_E_GTM_CLC_DISABLE_ERR_SetEventStatusWithMonitorData: start-on-event=SetEventStatusWithMonitorData, operation=DiagnosticMonitor_MonitorData_MCU_E_GTM_CLC_DISABLE_ERR.SetEventStatusWithMonitorData
        OIE_DiagnosticMonitor_MonitorData_MCU_E_GTM_CLC_ENABLE_ERR_SetEventStatusWithMonitorData: start-on-event=SetEventStatusWithMonitorData, operation=DiagnosticMonitor_MonitorData_MCU_E_GTM_CLC_ENABLE_ERR.SetEventStatusWithMonitorData
        OIE_DiagnosticMonitor_MonitorData_MCU_E_OSC_FAILURE_SetEventStatusWithMonitorData: start-on-event=SetEventStatusWithMonitorData, operation=DiagnosticMonitor_MonitorData_MCU_E_OSC_FAILURE.SetEventStatusWithMonitorData
        OIE_DiagnosticMonitor_MonitorData_MCU_E_PERIPHERAL_PLL_LOCK_LOSS_SetEventStatusWithMonitorData: start-on-event=SetEventStatusWithMonitorData, operation=DiagnosticMonitor_MonitorData_MCU_E_PERIPHERAL_PLL_LOCK_LOSS.SetEventStatusWithMonitorData
        OIE_DiagnosticMonitor_MonitorData_MCU_E_PERIPHERAL_PLL_TIMEOUT_ERR_SetEventStatusWithMonitorData: start-on-event=SetEventStatusWithMonitorData, operation=DiagnosticMonitor_MonitorData_MCU_E_PERIPHERAL_PLL_TIMEOUT_ERR.SetEventStatusWithMonitorData
        OIE_DiagnosticMonitor_MonitorData_MCU_E_PMSWCR_UPDATE_ERR_SetEventStatusWithMonitorData: start-on-event=SetEventStatusWithMonitorData, operation=DiagnosticMonitor_MonitorData_MCU_E_PMSWCR_UPDATE_ERR.SetEventStatusWithMonitorData
        OIE_DiagnosticMonitor_MonitorData_MCU_E_SYSTEM_PLL_LOCK_LOSS_SetEventStatusWithMonitorData: start-on-event=SetEventStatusWithMonitorData, operation=DiagnosticMonitor_MonitorData_MCU_E_SYSTEM_PLL_LOCK_LOSS.SetEventStatusWithMonitorData
        OIE_DiagnosticMonitor_MonitorData_MCU_E_SYSTEM_PLL_TIMEOUT_ERR_SetEventStatusWithMonitorData: start-on-event=SetEventStatusWithMonitorData, operation=DiagnosticMonitor_MonitorData_MCU_E_SYSTEM_PLL_TIMEOUT_ERR.SetEventStatusWithMonitorData
        OIE_DiagnosticMonitor_MonitorData_NVM_E_INTEGRITY_FAILED_SetEventStatusWithMonitorData: start-on-event=SetEventStatusWithMonitorData, operation=DiagnosticMonitor_MonitorData_NVM_E_INTEGRITY_FAILED.SetEventStatusWithMonitorData
        OIE_DiagnosticMonitor_MonitorData_NVM_E_LOSS_OF_REDUNDANCY_SetEventStatusWithMonitorData: start-on-event=SetEventStatusWithMonitorData, operation=DiagnosticMonitor_MonitorData_NVM_E_LOSS_OF_REDUNDANCY.SetEventStatusWithMonitorData
        OIE_DiagnosticMonitor_MonitorData_NVM_E_QUEUE_OVERFLOW_SetEventStatusWithMonitorData: start-on-event=SetEventStatusWithMonitorData, operation=DiagnosticMonitor_MonitorData_NVM_E_QUEUE_OVERFLOW.SetEventStatusWithMonitorData
        OIE_DiagnosticMonitor_MonitorData_NVM_E_REQ_FAILED_SetEventStatusWithMonitorData: start-on-event=SetEventStatusWithMonitorData, operation=DiagnosticMonitor_MonitorData_NVM_E_REQ_FAILED.SetEventStatusWithMonitorData
        OIE_DiagnosticMonitor_MonitorData_NVM_E_VERIFY_FAILED_SetEventStatusWithMonitorData: start-on-event=SetEventStatusWithMonitorData, operation=DiagnosticMonitor_MonitorData_NVM_E_VERIFY_FAILED.SetEventStatusWithMonitorData
        OIE_DiagnosticMonitor_MonitorData_NVM_E_WRITE_PROTECTED_SetEventStatusWithMonitorData: start-on-event=SetEventStatusWithMonitorData, operation=DiagnosticMonitor_MonitorData_NVM_E_WRITE_PROTECTED.SetEventStatusWithMonitorData
        OIE_DiagnosticMonitor_MonitorData_NVM_E_WRONG_BLOCK_ID_SetEventStatusWithMonitorData: start-on-event=SetEventStatusWithMonitorData, operation=DiagnosticMonitor_MonitorData_NVM_E_WRONG_BLOCK_ID.SetEventStatusWithMonitorData
        OIE_DiagnosticMonitor_MonitorData_SPI_E_HARDWARE_ERROR_SetEventStatusWithMonitorData: start-on-event=SetEventStatusWithMonitorData, operation=DiagnosticMonitor_MonitorData_SPI_E_HARDWARE_ERROR.SetEventStatusWithMonitorData
        OIE_DiagnosticMonitor_MonitorData_WDGM_E_IMPROPER_CALLER_SetEventStatusWithMonitorData: start-on-event=SetEventStatusWithMonitorData, operation=DiagnosticMonitor_MonitorData_WDGM_E_IMPROPER_CALLER.SetEventStatusWithMonitorData
        OIE_DiagnosticMonitor_MonitorData_WDGM_E_MONITORING_SetEventStatusWithMonitorData: start-on-event=SetEventStatusWithMonitorData, operation=DiagnosticMonitor_MonitorData_WDGM_E_MONITORING.SetEventStatusWithMonitorData
        OIE_DiagnosticMonitor_MonitorData_WDGM_E_SET_MODE_SetEventStatusWithMonitorData: start-on-event=SetEventStatusWithMonitorData, operation=DiagnosticMonitor_MonitorData_WDGM_E_SET_MODE.SetEventStatusWithMonitorData
        OIE_DiagnosticMonitor_MonitorData_WDG_76_ACW_E_DISABLE_REJECTED_SetEventStatusWithMonitorData: start-on-event=SetEventStatusWithMonitorData, operation=DiagnosticMonitor_MonitorData_WDG_76_ACW_E_DISABLE_REJECTED.SetEventStatusWithMonitorData
        OIE_DiagnosticMonitor_MonitorData_WDG_76_ACW_E_MODE_FAILED_SetEventStatusWithMonitorData: start-on-event=SetEventStatusWithMonitorData, operation=DiagnosticMonitor_MonitorData_WDG_76_ACW_E_MODE_FAILED.SetEventStatusWithMonitorData
        OIE_DiagnosticMonitor_MonitorData_WDG_E_DISABLE_REJECTED_SetEventStatusWithMonitorData: start-on-event=SetEventStatusWithMonitorData, operation=DiagnosticMonitor_MonitorData_WDG_E_DISABLE_REJECTED.SetEventStatusWithMonitorData
        OIE_DiagnosticMonitor_MonitorData_WDG_E_MODE_FAILED_SetEventStatusWithMonitorData: start-on-event=SetEventStatusWithMonitorData, operation=DiagnosticMonitor_MonitorData_WDG_E_MODE_FAILED.SetEventStatusWithMonitorData
        OIE_EnableCond_DemEnableCondition0_SetEnableCondition: start-on-event=SetEnableCondition, operation=EnableCond_DemEnableCondition0.SetEnableCondition
        OIE_EventInfo_CANCM_E_BAT_FAIL_GetDTCOfEvent: start-on-event=GetDTCOfEvent, operation=EventInfo_CANCM_E_BAT_FAIL.GetDTCOfEvent
        OIE_EventInfo_CANCM_E_BAT_FAIL_GetDebouncingOfEvent: start-on-event=GetDebouncingOfEvent, operation=EventInfo_CANCM_E_BAT_FAIL.GetDebouncingOfEvent
        OIE_EventInfo_CANCM_E_BAT_FAIL_GetEventExtendedDataRecordEx: start-on-event=GetEventExtendedDataRecordEx, operation=EventInfo_CANCM_E_BAT_FAIL.GetEventExtendedDataRecordEx
        OIE_EventInfo_CANCM_E_BAT_FAIL_GetEventFreezeFrameDataEx: start-on-event=GetEventFreezeFrameDataEx, operation=EventInfo_CANCM_E_BAT_FAIL.GetEventFreezeFrameDataEx
        OIE_EventInfo_CANCM_E_BAT_FAIL_GetEventUdsStatus: start-on-event=GetEventUdsStatus, operation=EventInfo_CANCM_E_BAT_FAIL.GetEventUdsStatus
        OIE_EventInfo_CANCM_E_BAT_FAIL_GetFaultDetectionCounter: start-on-event=GetFaultDetectionCounter, operation=EventInfo_CANCM_E_BAT_FAIL.GetFaultDetectionCounter
        OIE_EventInfo_CANCM_E_BAT_FAIL_GetMonitorStatus: start-on-event=GetMonitorStatus, operation=EventInfo_CANCM_E_BAT_FAIL.GetMonitorStatus
        OIE_EventInfo_CANSM_E_BUS_OFF_FD_CAN1_GetDTCOfEvent: start-on-event=GetDTCOfEvent, operation=EventInfo_CANSM_E_BUS_OFF_FD_CAN1.GetDTCOfEvent
        OIE_EventInfo_CANSM_E_BUS_OFF_FD_CAN1_GetDebouncingOfEvent: start-on-event=GetDebouncingOfEvent, operation=EventInfo_CANSM_E_BUS_OFF_FD_CAN1.GetDebouncingOfEvent
        OIE_EventInfo_CANSM_E_BUS_OFF_FD_CAN1_GetEventExtendedDataRecordEx: start-on-event=GetEventExtendedDataRecordEx, operation=EventInfo_CANSM_E_BUS_OFF_FD_CAN1.GetEventExtendedDataRecordEx
        OIE_EventInfo_CANSM_E_BUS_OFF_FD_CAN1_GetEventFreezeFrameDataEx: start-on-event=GetEventFreezeFrameDataEx, operation=EventInfo_CANSM_E_BUS_OFF_FD_CAN1.GetEventFreezeFrameDataEx
        OIE_EventInfo_CANSM_E_BUS_OFF_FD_CAN1_GetEventUdsStatus: start-on-event=GetEventUdsStatus, operation=EventInfo_CANSM_E_BUS_OFF_FD_CAN1.GetEventUdsStatus
        OIE_EventInfo_CANSM_E_BUS_OFF_FD_CAN1_GetFaultDetectionCounter: start-on-event=GetFaultDetectionCounter, operation=EventInfo_CANSM_E_BUS_OFF_FD_CAN1.GetFaultDetectionCounter
        OIE_EventInfo_CANSM_E_BUS_OFF_FD_CAN1_GetMonitorStatus: start-on-event=GetMonitorStatus, operation=EventInfo_CANSM_E_BUS_OFF_FD_CAN1.GetMonitorStatus
        OIE_EventInfo_CANSM_E_BUS_OFF_FD_CAN2_GetDTCOfEvent: start-on-event=GetDTCOfEvent, operation=EventInfo_CANSM_E_BUS_OFF_FD_CAN2.GetDTCOfEvent
        OIE_EventInfo_CANSM_E_BUS_OFF_FD_CAN2_GetDebouncingOfEvent: start-on-event=GetDebouncingOfEvent, operation=EventInfo_CANSM_E_BUS_OFF_FD_CAN2.GetDebouncingOfEvent
        OIE_EventInfo_CANSM_E_BUS_OFF_FD_CAN2_GetEventExtendedDataRecordEx: start-on-event=GetEventExtendedDataRecordEx, operation=EventInfo_CANSM_E_BUS_OFF_FD_CAN2.GetEventExtendedDataRecordEx
        OIE_EventInfo_CANSM_E_BUS_OFF_FD_CAN2_GetEventFreezeFrameDataEx: start-on-event=GetEventFreezeFrameDataEx, operation=EventInfo_CANSM_E_BUS_OFF_FD_CAN2.GetEventFreezeFrameDataEx
        OIE_EventInfo_CANSM_E_BUS_OFF_FD_CAN2_GetEventUdsStatus: start-on-event=GetEventUdsStatus, operation=EventInfo_CANSM_E_BUS_OFF_FD_CAN2.GetEventUdsStatus
        OIE_EventInfo_CANSM_E_BUS_OFF_FD_CAN2_GetFaultDetectionCounter: start-on-event=GetFaultDetectionCounter, operation=EventInfo_CANSM_E_BUS_OFF_FD_CAN2.GetFaultDetectionCounter
        OIE_EventInfo_CANSM_E_BUS_OFF_FD_CAN2_GetMonitorStatus: start-on-event=GetMonitorStatus, operation=EventInfo_CANSM_E_BUS_OFF_FD_CAN2.GetMonitorStatus
        OIE_EventInfo_CANSM_E_BUS_OFF_HS_CAN1_GetDTCOfEvent: start-on-event=GetDTCOfEvent, operation=EventInfo_CANSM_E_BUS_OFF_HS_CAN1.GetDTCOfEvent
        OIE_EventInfo_CANSM_E_BUS_OFF_HS_CAN1_GetDebouncingOfEvent: start-on-event=GetDebouncingOfEvent, operation=EventInfo_CANSM_E_BUS_OFF_HS_CAN1.GetDebouncingOfEvent
        OIE_EventInfo_CANSM_E_BUS_OFF_HS_CAN1_GetEventExtendedDataRecordEx: start-on-event=GetEventExtendedDataRecordEx, operation=EventInfo_CANSM_E_BUS_OFF_HS_CAN1.GetEventExtendedDataRecordEx
        OIE_EventInfo_CANSM_E_BUS_OFF_HS_CAN1_GetEventFreezeFrameDataEx: start-on-event=GetEventFreezeFrameDataEx, operation=EventInfo_CANSM_E_BUS_OFF_HS_CAN1.GetEventFreezeFrameDataEx
        OIE_EventInfo_CANSM_E_BUS_OFF_HS_CAN1_GetEventUdsStatus: start-on-event=GetEventUdsStatus, operation=EventInfo_CANSM_E_BUS_OFF_HS_CAN1.GetEventUdsStatus
        OIE_EventInfo_CANSM_E_BUS_OFF_HS_CAN1_GetFaultDetectionCounter: start-on-event=GetFaultDetectionCounter, operation=EventInfo_CANSM_E_BUS_OFF_HS_CAN1.GetFaultDetectionCounter
        OIE_EventInfo_CANSM_E_BUS_OFF_HS_CAN1_GetMonitorStatus: start-on-event=GetMonitorStatus, operation=EventInfo_CANSM_E_BUS_OFF_HS_CAN1.GetMonitorStatus
        OIE_EventInfo_CANSM_E_BUS_OFF_LS_CAN1_GetDTCOfEvent: start-on-event=GetDTCOfEvent, operation=EventInfo_CANSM_E_BUS_OFF_LS_CAN1.GetDTCOfEvent
        OIE_EventInfo_CANSM_E_BUS_OFF_LS_CAN1_GetDebouncingOfEvent: start-on-event=GetDebouncingOfEvent, operation=EventInfo_CANSM_E_BUS_OFF_LS_CAN1.GetDebouncingOfEvent
        OIE_EventInfo_CANSM_E_BUS_OFF_LS_CAN1_GetEventExtendedDataRecordEx: start-on-event=GetEventExtendedDataRecordEx, operation=EventInfo_CANSM_E_BUS_OFF_LS_CAN1.GetEventExtendedDataRecordEx
        OIE_EventInfo_CANSM_E_BUS_OFF_LS_CAN1_GetEventFreezeFrameDataEx: start-on-event=GetEventFreezeFrameDataEx, operation=EventInfo_CANSM_E_BUS_OFF_LS_CAN1.GetEventFreezeFrameDataEx
        OIE_EventInfo_CANSM_E_BUS_OFF_LS_CAN1_GetEventUdsStatus: start-on-event=GetEventUdsStatus, operation=EventInfo_CANSM_E_BUS_OFF_LS_CAN1.GetEventUdsStatus
        OIE_EventInfo_CANSM_E_BUS_OFF_LS_CAN1_GetFaultDetectionCounter: start-on-event=GetFaultDetectionCounter, operation=EventInfo_CANSM_E_BUS_OFF_LS_CAN1.GetFaultDetectionCounter
        OIE_EventInfo_CANSM_E_BUS_OFF_LS_CAN1_GetMonitorStatus: start-on-event=GetMonitorStatus, operation=EventInfo_CANSM_E_BUS_OFF_LS_CAN1.GetMonitorStatus
        OIE_EventInfo_CANSM_E_BUS_OFF_Project_GetDTCOfEvent: start-on-event=GetDTCOfEvent, operation=EventInfo_CANSM_E_BUS_OFF_Project.GetDTCOfEvent
        OIE_EventInfo_CANSM_E_BUS_OFF_Project_GetDebouncingOfEvent: start-on-event=GetDebouncingOfEvent, operation=EventInfo_CANSM_E_BUS_OFF_Project.GetDebouncingOfEvent
        OIE_EventInfo_CANSM_E_BUS_OFF_Project_GetEventExtendedDataRecordEx: start-on-event=GetEventExtendedDataRecordEx, operation=EventInfo_CANSM_E_BUS_OFF_Project.GetEventExtendedDataRecordEx
        OIE_EventInfo_CANSM_E_BUS_OFF_Project_GetEventFreezeFrameDataEx: start-on-event=GetEventFreezeFrameDataEx, operation=EventInfo_CANSM_E_BUS_OFF_Project.GetEventFreezeFrameDataEx
        OIE_EventInfo_CANSM_E_BUS_OFF_Project_GetEventUdsStatus: start-on-event=GetEventUdsStatus, operation=EventInfo_CANSM_E_BUS_OFF_Project.GetEventUdsStatus
        OIE_EventInfo_CANSM_E_BUS_OFF_Project_GetFaultDetectionCounter: start-on-event=GetFaultDetectionCounter, operation=EventInfo_CANSM_E_BUS_OFF_Project.GetFaultDetectionCounter
        OIE_EventInfo_CANSM_E_BUS_OFF_Project_GetMonitorStatus: start-on-event=GetMonitorStatus, operation=EventInfo_CANSM_E_BUS_OFF_Project.GetMonitorStatus
        OIE_EventInfo_CANSM_E_MODE_CHANGE_FD_CAN1_GetDTCOfEvent: start-on-event=GetDTCOfEvent, operation=EventInfo_CANSM_E_MODE_CHANGE_FD_CAN1.GetDTCOfEvent
        OIE_EventInfo_CANSM_E_MODE_CHANGE_FD_CAN1_GetDebouncingOfEvent: start-on-event=GetDebouncingOfEvent, operation=EventInfo_CANSM_E_MODE_CHANGE_FD_CAN1.GetDebouncingOfEvent
        OIE_EventInfo_CANSM_E_MODE_CHANGE_FD_CAN1_GetEventExtendedDataRecordEx: start-on-event=GetEventExtendedDataRecordEx, operation=EventInfo_CANSM_E_MODE_CHANGE_FD_CAN1.GetEventExtendedDataRecordEx
        OIE_EventInfo_CANSM_E_MODE_CHANGE_FD_CAN1_GetEventFreezeFrameDataEx: start-on-event=GetEventFreezeFrameDataEx, operation=EventInfo_CANSM_E_MODE_CHANGE_FD_CAN1.GetEventFreezeFrameDataEx
        OIE_EventInfo_CANSM_E_MODE_CHANGE_FD_CAN1_GetEventUdsStatus: start-on-event=GetEventUdsStatus, operation=EventInfo_CANSM_E_MODE_CHANGE_FD_CAN1.GetEventUdsStatus
        OIE_EventInfo_CANSM_E_MODE_CHANGE_FD_CAN1_GetFaultDetectionCounter: start-on-event=GetFaultDetectionCounter, operation=EventInfo_CANSM_E_MODE_CHANGE_FD_CAN1.GetFaultDetectionCounter
        OIE_EventInfo_CANSM_E_MODE_CHANGE_FD_CAN1_GetMonitorStatus: start-on-event=GetMonitorStatus, operation=EventInfo_CANSM_E_MODE_CHANGE_FD_CAN1.GetMonitorStatus
        OIE_EventInfo_CANSM_E_MODE_CHANGE_FD_CAN2_GetDTCOfEvent: start-on-event=GetDTCOfEvent, operation=EventInfo_CANSM_E_MODE_CHANGE_FD_CAN2.GetDTCOfEvent
        OIE_EventInfo_CANSM_E_MODE_CHANGE_FD_CAN2_GetDebouncingOfEvent: start-on-event=GetDebouncingOfEvent, operation=EventInfo_CANSM_E_MODE_CHANGE_FD_CAN2.GetDebouncingOfEvent
        OIE_EventInfo_CANSM_E_MODE_CHANGE_FD_CAN2_GetEventExtendedDataRecordEx: start-on-event=GetEventExtendedDataRecordEx, operation=EventInfo_CANSM_E_MODE_CHANGE_FD_CAN2.GetEventExtendedDataRecordEx
        OIE_EventInfo_CANSM_E_MODE_CHANGE_FD_CAN2_GetEventFreezeFrameDataEx: start-on-event=GetEventFreezeFrameDataEx, operation=EventInfo_CANSM_E_MODE_CHANGE_FD_CAN2.GetEventFreezeFrameDataEx
        OIE_EventInfo_CANSM_E_MODE_CHANGE_FD_CAN2_GetEventUdsStatus: start-on-event=GetEventUdsStatus, operation=EventInfo_CANSM_E_MODE_CHANGE_FD_CAN2.GetEventUdsStatus
        OIE_EventInfo_CANSM_E_MODE_CHANGE_FD_CAN2_GetFaultDetectionCounter: start-on-event=GetFaultDetectionCounter, operation=EventInfo_CANSM_E_MODE_CHANGE_FD_CAN2.GetFaultDetectionCounter
        OIE_EventInfo_CANSM_E_MODE_CHANGE_FD_CAN2_GetMonitorStatus: start-on-event=GetMonitorStatus, operation=EventInfo_CANSM_E_MODE_CHANGE_FD_CAN2.GetMonitorStatus
        OIE_EventInfo_CANSM_E_MODE_CHANGE_HS_CAN1_GetDTCOfEvent: start-on-event=GetDTCOfEvent, operation=EventInfo_CANSM_E_MODE_CHANGE_HS_CAN1.GetDTCOfEvent
        OIE_EventInfo_CANSM_E_MODE_CHANGE_HS_CAN1_GetDebouncingOfEvent: start-on-event=GetDebouncingOfEvent, operation=EventInfo_CANSM_E_MODE_CHANGE_HS_CAN1.GetDebouncingOfEvent
        OIE_EventInfo_CANSM_E_MODE_CHANGE_HS_CAN1_GetEventExtendedDataRecordEx: start-on-event=GetEventExtendedDataRecordEx, operation=EventInfo_CANSM_E_MODE_CHANGE_HS_CAN1.GetEventExtendedDataRecordEx
        OIE_EventInfo_CANSM_E_MODE_CHANGE_HS_CAN1_GetEventFreezeFrameDataEx: start-on-event=GetEventFreezeFrameDataEx, operation=EventInfo_CANSM_E_MODE_CHANGE_HS_CAN1.GetEventFreezeFrameDataEx
        OIE_EventInfo_CANSM_E_MODE_CHANGE_HS_CAN1_GetEventUdsStatus: start-on-event=GetEventUdsStatus, operation=EventInfo_CANSM_E_MODE_CHANGE_HS_CAN1.GetEventUdsStatus
        OIE_EventInfo_CANSM_E_MODE_CHANGE_HS_CAN1_GetFaultDetectionCounter: start-on-event=GetFaultDetectionCounter, operation=EventInfo_CANSM_E_MODE_CHANGE_HS_CAN1.GetFaultDetectionCounter
        OIE_EventInfo_CANSM_E_MODE_CHANGE_HS_CAN1_GetMonitorStatus: start-on-event=GetMonitorStatus, operation=EventInfo_CANSM_E_MODE_CHANGE_HS_CAN1.GetMonitorStatus
        OIE_EventInfo_CANSM_E_MODE_CHANGE_LS_CAN1_GetDTCOfEvent: start-on-event=GetDTCOfEvent, operation=EventInfo_CANSM_E_MODE_CHANGE_LS_CAN1.GetDTCOfEvent
        OIE_EventInfo_CANSM_E_MODE_CHANGE_LS_CAN1_GetDebouncingOfEvent: start-on-event=GetDebouncingOfEvent, operation=EventInfo_CANSM_E_MODE_CHANGE_LS_CAN1.GetDebouncingOfEvent
        OIE_EventInfo_CANSM_E_MODE_CHANGE_LS_CAN1_GetEventExtendedDataRecordEx: start-on-event=GetEventExtendedDataRecordEx, operation=EventInfo_CANSM_E_MODE_CHANGE_LS_CAN1.GetEventExtendedDataRecordEx
        OIE_EventInfo_CANSM_E_MODE_CHANGE_LS_CAN1_GetEventFreezeFrameDataEx: start-on-event=GetEventFreezeFrameDataEx, operation=EventInfo_CANSM_E_MODE_CHANGE_LS_CAN1.GetEventFreezeFrameDataEx
        OIE_EventInfo_CANSM_E_MODE_CHANGE_LS_CAN1_GetEventUdsStatus: start-on-event=GetEventUdsStatus, operation=EventInfo_CANSM_E_MODE_CHANGE_LS_CAN1.GetEventUdsStatus
        OIE_EventInfo_CANSM_E_MODE_CHANGE_LS_CAN1_GetFaultDetectionCounter: start-on-event=GetFaultDetectionCounter, operation=EventInfo_CANSM_E_MODE_CHANGE_LS_CAN1.GetFaultDetectionCounter
        OIE_EventInfo_CANSM_E_MODE_CHANGE_LS_CAN1_GetMonitorStatus: start-on-event=GetMonitorStatus, operation=EventInfo_CANSM_E_MODE_CHANGE_LS_CAN1.GetMonitorStatus
        OIE_EventInfo_CANSM_E_MODE_CHANGE_Project_GetDTCOfEvent: start-on-event=GetDTCOfEvent, operation=EventInfo_CANSM_E_MODE_CHANGE_Project.GetDTCOfEvent
        OIE_EventInfo_CANSM_E_MODE_CHANGE_Project_GetDebouncingOfEvent: start-on-event=GetDebouncingOfEvent, operation=EventInfo_CANSM_E_MODE_CHANGE_Project.GetDebouncingOfEvent
        OIE_EventInfo_CANSM_E_MODE_CHANGE_Project_GetEventExtendedDataRecordEx: start-on-event=GetEventExtendedDataRecordEx, operation=EventInfo_CANSM_E_MODE_CHANGE_Project.GetEventExtendedDataRecordEx
        OIE_EventInfo_CANSM_E_MODE_CHANGE_Project_GetEventFreezeFrameDataEx: start-on-event=GetEventFreezeFrameDataEx, operation=EventInfo_CANSM_E_MODE_CHANGE_Project.GetEventFreezeFrameDataEx
        OIE_EventInfo_CANSM_E_MODE_CHANGE_Project_GetEventUdsStatus: start-on-event=GetEventUdsStatus, operation=EventInfo_CANSM_E_MODE_CHANGE_Project.GetEventUdsStatus
        OIE_EventInfo_CANSM_E_MODE_CHANGE_Project_GetFaultDetectionCounter: start-on-event=GetFaultDetectionCounter, operation=EventInfo_CANSM_E_MODE_CHANGE_Project.GetFaultDetectionCounter
        OIE_EventInfo_CANSM_E_MODE_CHANGE_Project_GetMonitorStatus: start-on-event=GetMonitorStatus, operation=EventInfo_CANSM_E_MODE_CHANGE_Project.GetMonitorStatus
        OIE_EventInfo_CANSM_E_MODE_REQUEST_TIMEOUT_FD_CAN1_GetDTCOfEvent: start-on-event=GetDTCOfEvent, operation=EventInfo_CANSM_E_MODE_REQUEST_TIMEOUT_FD_CAN1.GetDTCOfEvent
        OIE_EventInfo_CANSM_E_MODE_REQUEST_TIMEOUT_FD_CAN1_GetDebouncingOfEvent: start-on-event=GetDebouncingOfEvent, operation=EventInfo_CANSM_E_MODE_REQUEST_TIMEOUT_FD_CAN1.GetDebouncingOfEvent
        OIE_EventInfo_CANSM_E_MODE_REQUEST_TIMEOUT_FD_CAN1_GetEventExtendedDataRecordEx: start-on-event=GetEventExtendedDataRecordEx, operation=EventInfo_CANSM_E_MODE_REQUEST_TIMEOUT_FD_CAN1.GetEventExtendedDataRecordEx
        OIE_EventInfo_CANSM_E_MODE_REQUEST_TIMEOUT_FD_CAN1_GetEventFreezeFrameDataEx: start-on-event=GetEventFreezeFrameDataEx, operation=EventInfo_CANSM_E_MODE_REQUEST_TIMEOUT_FD_CAN1.GetEventFreezeFrameDataEx
        OIE_EventInfo_CANSM_E_MODE_REQUEST_TIMEOUT_FD_CAN1_GetEventUdsStatus: start-on-event=GetEventUdsStatus, operation=EventInfo_CANSM_E_MODE_REQUEST_TIMEOUT_FD_CAN1.GetEventUdsStatus
        OIE_EventInfo_CANSM_E_MODE_REQUEST_TIMEOUT_FD_CAN1_GetFaultDetectionCounter: start-on-event=GetFaultDetectionCounter, operation=EventInfo_CANSM_E_MODE_REQUEST_TIMEOUT_FD_CAN1.GetFaultDetectionCounter
        OIE_EventInfo_CANSM_E_MODE_REQUEST_TIMEOUT_FD_CAN1_GetMonitorStatus: start-on-event=GetMonitorStatus, operation=EventInfo_CANSM_E_MODE_REQUEST_TIMEOUT_FD_CAN1.GetMonitorStatus
        OIE_EventInfo_CANSM_E_MODE_REQUEST_TIMEOUT_HS_CAN1_GetDTCOfEvent: start-on-event=GetDTCOfEvent, operation=EventInfo_CANSM_E_MODE_REQUEST_TIMEOUT_HS_CAN1.GetDTCOfEvent
        OIE_EventInfo_CANSM_E_MODE_REQUEST_TIMEOUT_HS_CAN1_GetDebouncingOfEvent: start-on-event=GetDebouncingOfEvent, operation=EventInfo_CANSM_E_MODE_REQUEST_TIMEOUT_HS_CAN1.GetDebouncingOfEvent
        OIE_EventInfo_CANSM_E_MODE_REQUEST_TIMEOUT_HS_CAN1_GetEventExtendedDataRecordEx: start-on-event=GetEventExtendedDataRecordEx, operation=EventInfo_CANSM_E_MODE_REQUEST_TIMEOUT_HS_CAN1.GetEventExtendedDataRecordEx
        OIE_EventInfo_CANSM_E_MODE_REQUEST_TIMEOUT_HS_CAN1_GetEventFreezeFrameDataEx: start-on-event=GetEventFreezeFrameDataEx, operation=EventInfo_CANSM_E_MODE_REQUEST_TIMEOUT_HS_CAN1.GetEventFreezeFrameDataEx
        OIE_EventInfo_CANSM_E_MODE_REQUEST_TIMEOUT_HS_CAN1_GetEventUdsStatus: start-on-event=GetEventUdsStatus, operation=EventInfo_CANSM_E_MODE_REQUEST_TIMEOUT_HS_CAN1.GetEventUdsStatus
        OIE_EventInfo_CANSM_E_MODE_REQUEST_TIMEOUT_HS_CAN1_GetFaultDetectionCounter: start-on-event=GetFaultDetectionCounter, operation=EventInfo_CANSM_E_MODE_REQUEST_TIMEOUT_HS_CAN1.GetFaultDetectionCounter
        OIE_EventInfo_CANSM_E_MODE_REQUEST_TIMEOUT_HS_CAN1_GetMonitorStatus: start-on-event=GetMonitorStatus, operation=EventInfo_CANSM_E_MODE_REQUEST_TIMEOUT_HS_CAN1.GetMonitorStatus
        OIE_EventInfo_DEM_E_TEST_EVENT10_GetDTCOfEvent: start-on-event=GetDTCOfEvent, operation=EventInfo_DEM_E_TEST_EVENT10.GetDTCOfEvent
        OIE_EventInfo_DEM_E_TEST_EVENT10_GetDebouncingOfEvent: start-on-event=GetDebouncingOfEvent, operation=EventInfo_DEM_E_TEST_EVENT10.GetDebouncingOfEvent
        OIE_EventInfo_DEM_E_TEST_EVENT10_GetEventExtendedDataRecordEx: start-on-event=GetEventExtendedDataRecordEx, operation=EventInfo_DEM_E_TEST_EVENT10.GetEventExtendedDataRecordEx
        OIE_EventInfo_DEM_E_TEST_EVENT10_GetEventFreezeFrameDataEx: start-on-event=GetEventFreezeFrameDataEx, operation=EventInfo_DEM_E_TEST_EVENT10.GetEventFreezeFrameDataEx
        OIE_EventInfo_DEM_E_TEST_EVENT10_GetEventUdsStatus: start-on-event=GetEventUdsStatus, operation=EventInfo_DEM_E_TEST_EVENT10.GetEventUdsStatus
        OIE_EventInfo_DEM_E_TEST_EVENT10_GetFaultDetectionCounter: start-on-event=GetFaultDetectionCounter, operation=EventInfo_DEM_E_TEST_EVENT10.GetFaultDetectionCounter
        OIE_EventInfo_DEM_E_TEST_EVENT10_GetMonitorStatus: start-on-event=GetMonitorStatus, operation=EventInfo_DEM_E_TEST_EVENT10.GetMonitorStatus
        OIE_EventInfo_DEM_E_TEST_EVENT11_GetDTCOfEvent: start-on-event=GetDTCOfEvent, operation=EventInfo_DEM_E_TEST_EVENT11.GetDTCOfEvent
        OIE_EventInfo_DEM_E_TEST_EVENT11_GetDebouncingOfEvent: start-on-event=GetDebouncingOfEvent, operation=EventInfo_DEM_E_TEST_EVENT11.GetDebouncingOfEvent
        OIE_EventInfo_DEM_E_TEST_EVENT11_GetEventExtendedDataRecordEx: start-on-event=GetEventExtendedDataRecordEx, operation=EventInfo_DEM_E_TEST_EVENT11.GetEventExtendedDataRecordEx
        OIE_EventInfo_DEM_E_TEST_EVENT11_GetEventFreezeFrameDataEx: start-on-event=GetEventFreezeFrameDataEx, operation=EventInfo_DEM_E_TEST_EVENT11.GetEventFreezeFrameDataEx
        OIE_EventInfo_DEM_E_TEST_EVENT11_GetEventUdsStatus: start-on-event=GetEventUdsStatus, operation=EventInfo_DEM_E_TEST_EVENT11.GetEventUdsStatus
        OIE_EventInfo_DEM_E_TEST_EVENT11_GetFaultDetectionCounter: start-on-event=GetFaultDetectionCounter, operation=EventInfo_DEM_E_TEST_EVENT11.GetFaultDetectionCounter
        OIE_EventInfo_DEM_E_TEST_EVENT11_GetMonitorStatus: start-on-event=GetMonitorStatus, operation=EventInfo_DEM_E_TEST_EVENT11.GetMonitorStatus
        OIE_EventInfo_DEM_E_TEST_EVENT12_GetDTCOfEvent: start-on-event=GetDTCOfEvent, operation=EventInfo_DEM_E_TEST_EVENT12.GetDTCOfEvent
        OIE_EventInfo_DEM_E_TEST_EVENT12_GetDebouncingOfEvent: start-on-event=GetDebouncingOfEvent, operation=EventInfo_DEM_E_TEST_EVENT12.GetDebouncingOfEvent
        OIE_EventInfo_DEM_E_TEST_EVENT12_GetEventExtendedDataRecordEx: start-on-event=GetEventExtendedDataRecordEx, operation=EventInfo_DEM_E_TEST_EVENT12.GetEventExtendedDataRecordEx
        OIE_EventInfo_DEM_E_TEST_EVENT12_GetEventFreezeFrameDataEx: start-on-event=GetEventFreezeFrameDataEx, operation=EventInfo_DEM_E_TEST_EVENT12.GetEventFreezeFrameDataEx
        OIE_EventInfo_DEM_E_TEST_EVENT12_GetEventUdsStatus: start-on-event=GetEventUdsStatus, operation=EventInfo_DEM_E_TEST_EVENT12.GetEventUdsStatus
        OIE_EventInfo_DEM_E_TEST_EVENT12_GetFaultDetectionCounter: start-on-event=GetFaultDetectionCounter, operation=EventInfo_DEM_E_TEST_EVENT12.GetFaultDetectionCounter
        OIE_EventInfo_DEM_E_TEST_EVENT12_GetMonitorStatus: start-on-event=GetMonitorStatus, operation=EventInfo_DEM_E_TEST_EVENT12.GetMonitorStatus
        OIE_EventInfo_DEM_E_TEST_EVENT13_GetDTCOfEvent: start-on-event=GetDTCOfEvent, operation=EventInfo_DEM_E_TEST_EVENT13.GetDTCOfEvent
        OIE_EventInfo_DEM_E_TEST_EVENT13_GetDebouncingOfEvent: start-on-event=GetDebouncingOfEvent, operation=EventInfo_DEM_E_TEST_EVENT13.GetDebouncingOfEvent
        OIE_EventInfo_DEM_E_TEST_EVENT13_GetEventExtendedDataRecordEx: start-on-event=GetEventExtendedDataRecordEx, operation=EventInfo_DEM_E_TEST_EVENT13.GetEventExtendedDataRecordEx
        OIE_EventInfo_DEM_E_TEST_EVENT13_GetEventFreezeFrameDataEx: start-on-event=GetEventFreezeFrameDataEx, operation=EventInfo_DEM_E_TEST_EVENT13.GetEventFreezeFrameDataEx
        OIE_EventInfo_DEM_E_TEST_EVENT13_GetEventUdsStatus: start-on-event=GetEventUdsStatus, operation=EventInfo_DEM_E_TEST_EVENT13.GetEventUdsStatus
        OIE_EventInfo_DEM_E_TEST_EVENT13_GetFaultDetectionCounter: start-on-event=GetFaultDetectionCounter, operation=EventInfo_DEM_E_TEST_EVENT13.GetFaultDetectionCounter
        OIE_EventInfo_DEM_E_TEST_EVENT13_GetMonitorStatus: start-on-event=GetMonitorStatus, operation=EventInfo_DEM_E_TEST_EVENT13.GetMonitorStatus
        OIE_EventInfo_DEM_E_TEST_EVENT14_GetDTCOfEvent: start-on-event=GetDTCOfEvent, operation=EventInfo_DEM_E_TEST_EVENT14.GetDTCOfEvent
        OIE_EventInfo_DEM_E_TEST_EVENT14_GetDebouncingOfEvent: start-on-event=GetDebouncingOfEvent, operation=EventInfo_DEM_E_TEST_EVENT14.GetDebouncingOfEvent
        OIE_EventInfo_DEM_E_TEST_EVENT14_GetEventExtendedDataRecordEx: start-on-event=GetEventExtendedDataRecordEx, operation=EventInfo_DEM_E_TEST_EVENT14.GetEventExtendedDataRecordEx
        OIE_EventInfo_DEM_E_TEST_EVENT14_GetEventFreezeFrameDataEx: start-on-event=GetEventFreezeFrameDataEx, operation=EventInfo_DEM_E_TEST_EVENT14.GetEventFreezeFrameDataEx
        OIE_EventInfo_DEM_E_TEST_EVENT14_GetEventUdsStatus: start-on-event=GetEventUdsStatus, operation=EventInfo_DEM_E_TEST_EVENT14.GetEventUdsStatus
        OIE_EventInfo_DEM_E_TEST_EVENT14_GetFaultDetectionCounter: start-on-event=GetFaultDetectionCounter, operation=EventInfo_DEM_E_TEST_EVENT14.GetFaultDetectionCounter
        OIE_EventInfo_DEM_E_TEST_EVENT14_GetMonitorStatus: start-on-event=GetMonitorStatus, operation=EventInfo_DEM_E_TEST_EVENT14.GetMonitorStatus
        OIE_EventInfo_DEM_E_TEST_EVENT15_GetDTCOfEvent: start-on-event=GetDTCOfEvent, operation=EventInfo_DEM_E_TEST_EVENT15.GetDTCOfEvent
        OIE_EventInfo_DEM_E_TEST_EVENT15_GetDebouncingOfEvent: start-on-event=GetDebouncingOfEvent, operation=EventInfo_DEM_E_TEST_EVENT15.GetDebouncingOfEvent
        OIE_EventInfo_DEM_E_TEST_EVENT15_GetEventExtendedDataRecordEx: start-on-event=GetEventExtendedDataRecordEx, operation=EventInfo_DEM_E_TEST_EVENT15.GetEventExtendedDataRecordEx
        OIE_EventInfo_DEM_E_TEST_EVENT15_GetEventFreezeFrameDataEx: start-on-event=GetEventFreezeFrameDataEx, operation=EventInfo_DEM_E_TEST_EVENT15.GetEventFreezeFrameDataEx
        OIE_EventInfo_DEM_E_TEST_EVENT15_GetEventUdsStatus: start-on-event=GetEventUdsStatus, operation=EventInfo_DEM_E_TEST_EVENT15.GetEventUdsStatus
        OIE_EventInfo_DEM_E_TEST_EVENT15_GetFaultDetectionCounter: start-on-event=GetFaultDetectionCounter, operation=EventInfo_DEM_E_TEST_EVENT15.GetFaultDetectionCounter
        OIE_EventInfo_DEM_E_TEST_EVENT15_GetMonitorStatus: start-on-event=GetMonitorStatus, operation=EventInfo_DEM_E_TEST_EVENT15.GetMonitorStatus
        OIE_EventInfo_DEM_E_TEST_EVENT16_GetDTCOfEvent: start-on-event=GetDTCOfEvent, operation=EventInfo_DEM_E_TEST_EVENT16.GetDTCOfEvent
        OIE_EventInfo_DEM_E_TEST_EVENT16_GetDebouncingOfEvent: start-on-event=GetDebouncingOfEvent, operation=EventInfo_DEM_E_TEST_EVENT16.GetDebouncingOfEvent
        OIE_EventInfo_DEM_E_TEST_EVENT16_GetEventExtendedDataRecordEx: start-on-event=GetEventExtendedDataRecordEx, operation=EventInfo_DEM_E_TEST_EVENT16.GetEventExtendedDataRecordEx
        OIE_EventInfo_DEM_E_TEST_EVENT16_GetEventFreezeFrameDataEx: start-on-event=GetEventFreezeFrameDataEx, operation=EventInfo_DEM_E_TEST_EVENT16.GetEventFreezeFrameDataEx
        OIE_EventInfo_DEM_E_TEST_EVENT16_GetEventUdsStatus: start-on-event=GetEventUdsStatus, operation=EventInfo_DEM_E_TEST_EVENT16.GetEventUdsStatus
        OIE_EventInfo_DEM_E_TEST_EVENT16_GetFaultDetectionCounter: start-on-event=GetFaultDetectionCounter, operation=EventInfo_DEM_E_TEST_EVENT16.GetFaultDetectionCounter
        OIE_EventInfo_DEM_E_TEST_EVENT16_GetMonitorStatus: start-on-event=GetMonitorStatus, operation=EventInfo_DEM_E_TEST_EVENT16.GetMonitorStatus
        OIE_EventInfo_DEM_E_TEST_EVENT17_GetDTCOfEvent: start-on-event=GetDTCOfEvent, operation=EventInfo_DEM_E_TEST_EVENT17.GetDTCOfEvent
        OIE_EventInfo_DEM_E_TEST_EVENT17_GetDebouncingOfEvent: start-on-event=GetDebouncingOfEvent, operation=EventInfo_DEM_E_TEST_EVENT17.GetDebouncingOfEvent
        OIE_EventInfo_DEM_E_TEST_EVENT17_GetEventExtendedDataRecordEx: start-on-event=GetEventExtendedDataRecordEx, operation=EventInfo_DEM_E_TEST_EVENT17.GetEventExtendedDataRecordEx
        OIE_EventInfo_DEM_E_TEST_EVENT17_GetEventFreezeFrameDataEx: start-on-event=GetEventFreezeFrameDataEx, operation=EventInfo_DEM_E_TEST_EVENT17.GetEventFreezeFrameDataEx
        OIE_EventInfo_DEM_E_TEST_EVENT17_GetEventUdsStatus: start-on-event=GetEventUdsStatus, operation=EventInfo_DEM_E_TEST_EVENT17.GetEventUdsStatus
        OIE_EventInfo_DEM_E_TEST_EVENT17_GetFaultDetectionCounter: start-on-event=GetFaultDetectionCounter, operation=EventInfo_DEM_E_TEST_EVENT17.GetFaultDetectionCounter
        OIE_EventInfo_DEM_E_TEST_EVENT17_GetMonitorStatus: start-on-event=GetMonitorStatus, operation=EventInfo_DEM_E_TEST_EVENT17.GetMonitorStatus
        OIE_EventInfo_DEM_E_TEST_EVENT18_GetDTCOfEvent: start-on-event=GetDTCOfEvent, operation=EventInfo_DEM_E_TEST_EVENT18.GetDTCOfEvent
        OIE_EventInfo_DEM_E_TEST_EVENT18_GetDebouncingOfEvent: start-on-event=GetDebouncingOfEvent, operation=EventInfo_DEM_E_TEST_EVENT18.GetDebouncingOfEvent
        OIE_EventInfo_DEM_E_TEST_EVENT18_GetEventExtendedDataRecordEx: start-on-event=GetEventExtendedDataRecordEx, operation=EventInfo_DEM_E_TEST_EVENT18.GetEventExtendedDataRecordEx
        OIE_EventInfo_DEM_E_TEST_EVENT18_GetEventFreezeFrameDataEx: start-on-event=GetEventFreezeFrameDataEx, operation=EventInfo_DEM_E_TEST_EVENT18.GetEventFreezeFrameDataEx
        OIE_EventInfo_DEM_E_TEST_EVENT18_GetEventUdsStatus: start-on-event=GetEventUdsStatus, operation=EventInfo_DEM_E_TEST_EVENT18.GetEventUdsStatus
        OIE_EventInfo_DEM_E_TEST_EVENT18_GetFaultDetectionCounter: start-on-event=GetFaultDetectionCounter, operation=EventInfo_DEM_E_TEST_EVENT18.GetFaultDetectionCounter
        OIE_EventInfo_DEM_E_TEST_EVENT18_GetMonitorStatus: start-on-event=GetMonitorStatus, operation=EventInfo_DEM_E_TEST_EVENT18.GetMonitorStatus
        OIE_EventInfo_DEM_E_TEST_EVENT19_GetDTCOfEvent: start-on-event=GetDTCOfEvent, operation=EventInfo_DEM_E_TEST_EVENT19.GetDTCOfEvent
        OIE_EventInfo_DEM_E_TEST_EVENT19_GetDebouncingOfEvent: start-on-event=GetDebouncingOfEvent, operation=EventInfo_DEM_E_TEST_EVENT19.GetDebouncingOfEvent
        OIE_EventInfo_DEM_E_TEST_EVENT19_GetEventExtendedDataRecordEx: start-on-event=GetEventExtendedDataRecordEx, operation=EventInfo_DEM_E_TEST_EVENT19.GetEventExtendedDataRecordEx
        OIE_EventInfo_DEM_E_TEST_EVENT19_GetEventFreezeFrameDataEx: start-on-event=GetEventFreezeFrameDataEx, operation=EventInfo_DEM_E_TEST_EVENT19.GetEventFreezeFrameDataEx
        OIE_EventInfo_DEM_E_TEST_EVENT19_GetEventUdsStatus: start-on-event=GetEventUdsStatus, operation=EventInfo_DEM_E_TEST_EVENT19.GetEventUdsStatus
        OIE_EventInfo_DEM_E_TEST_EVENT19_GetFaultDetectionCounter: start-on-event=GetFaultDetectionCounter, operation=EventInfo_DEM_E_TEST_EVENT19.GetFaultDetectionCounter
        OIE_EventInfo_DEM_E_TEST_EVENT19_GetMonitorStatus: start-on-event=GetMonitorStatus, operation=EventInfo_DEM_E_TEST_EVENT19.GetMonitorStatus
        OIE_EventInfo_DEM_E_TEST_EVENT1_GetDTCOfEvent: start-on-event=GetDTCOfEvent, operation=EventInfo_DEM_E_TEST_EVENT1.GetDTCOfEvent
        OIE_EventInfo_DEM_E_TEST_EVENT1_GetDebouncingOfEvent: start-on-event=GetDebouncingOfEvent, operation=EventInfo_DEM_E_TEST_EVENT1.GetDebouncingOfEvent
        OIE_EventInfo_DEM_E_TEST_EVENT1_GetEventExtendedDataRecordEx: start-on-event=GetEventExtendedDataRecordEx, operation=EventInfo_DEM_E_TEST_EVENT1.GetEventExtendedDataRecordEx
        OIE_EventInfo_DEM_E_TEST_EVENT1_GetEventFreezeFrameDataEx: start-on-event=GetEventFreezeFrameDataEx, operation=EventInfo_DEM_E_TEST_EVENT1.GetEventFreezeFrameDataEx
        OIE_EventInfo_DEM_E_TEST_EVENT1_GetEventUdsStatus: start-on-event=GetEventUdsStatus, operation=EventInfo_DEM_E_TEST_EVENT1.GetEventUdsStatus
        OIE_EventInfo_DEM_E_TEST_EVENT1_GetFaultDetectionCounter: start-on-event=GetFaultDetectionCounter, operation=EventInfo_DEM_E_TEST_EVENT1.GetFaultDetectionCounter
        OIE_EventInfo_DEM_E_TEST_EVENT1_GetMonitorStatus: start-on-event=GetMonitorStatus, operation=EventInfo_DEM_E_TEST_EVENT1.GetMonitorStatus
        OIE_EventInfo_DEM_E_TEST_EVENT20_GetDTCOfEvent: start-on-event=GetDTCOfEvent, operation=EventInfo_DEM_E_TEST_EVENT20.GetDTCOfEvent
        OIE_EventInfo_DEM_E_TEST_EVENT20_GetDebouncingOfEvent: start-on-event=GetDebouncingOfEvent, operation=EventInfo_DEM_E_TEST_EVENT20.GetDebouncingOfEvent
        OIE_EventInfo_DEM_E_TEST_EVENT20_GetEventExtendedDataRecordEx: start-on-event=GetEventExtendedDataRecordEx, operation=EventInfo_DEM_E_TEST_EVENT20.GetEventExtendedDataRecordEx
        OIE_EventInfo_DEM_E_TEST_EVENT20_GetEventFreezeFrameDataEx: start-on-event=GetEventFreezeFrameDataEx, operation=EventInfo_DEM_E_TEST_EVENT20.GetEventFreezeFrameDataEx
        OIE_EventInfo_DEM_E_TEST_EVENT20_GetEventUdsStatus: start-on-event=GetEventUdsStatus, operation=EventInfo_DEM_E_TEST_EVENT20.GetEventUdsStatus
        OIE_EventInfo_DEM_E_TEST_EVENT20_GetFaultDetectionCounter: start-on-event=GetFaultDetectionCounter, operation=EventInfo_DEM_E_TEST_EVENT20.GetFaultDetectionCounter
        OIE_EventInfo_DEM_E_TEST_EVENT20_GetMonitorStatus: start-on-event=GetMonitorStatus, operation=EventInfo_DEM_E_TEST_EVENT20.GetMonitorStatus
        OIE_EventInfo_DEM_E_TEST_EVENT21_GetDTCOfEvent: start-on-event=GetDTCOfEvent, operation=EventInfo_DEM_E_TEST_EVENT21.GetDTCOfEvent
        OIE_EventInfo_DEM_E_TEST_EVENT21_GetDebouncingOfEvent: start-on-event=GetDebouncingOfEvent, operation=EventInfo_DEM_E_TEST_EVENT21.GetDebouncingOfEvent
        OIE_EventInfo_DEM_E_TEST_EVENT21_GetEventExtendedDataRecordEx: start-on-event=GetEventExtendedDataRecordEx, operation=EventInfo_DEM_E_TEST_EVENT21.GetEventExtendedDataRecordEx
        OIE_EventInfo_DEM_E_TEST_EVENT21_GetEventFreezeFrameDataEx: start-on-event=GetEventFreezeFrameDataEx, operation=EventInfo_DEM_E_TEST_EVENT21.GetEventFreezeFrameDataEx
        OIE_EventInfo_DEM_E_TEST_EVENT21_GetEventUdsStatus: start-on-event=GetEventUdsStatus, operation=EventInfo_DEM_E_TEST_EVENT21.GetEventUdsStatus
        OIE_EventInfo_DEM_E_TEST_EVENT21_GetFaultDetectionCounter: start-on-event=GetFaultDetectionCounter, operation=EventInfo_DEM_E_TEST_EVENT21.GetFaultDetectionCounter
        OIE_EventInfo_DEM_E_TEST_EVENT21_GetMonitorStatus: start-on-event=GetMonitorStatus, operation=EventInfo_DEM_E_TEST_EVENT21.GetMonitorStatus
        OIE_EventInfo_DEM_E_TEST_EVENT22_GetDTCOfEvent: start-on-event=GetDTCOfEvent, operation=EventInfo_DEM_E_TEST_EVENT22.GetDTCOfEvent
        OIE_EventInfo_DEM_E_TEST_EVENT22_GetDebouncingOfEvent: start-on-event=GetDebouncingOfEvent, operation=EventInfo_DEM_E_TEST_EVENT22.GetDebouncingOfEvent
        OIE_EventInfo_DEM_E_TEST_EVENT22_GetEventExtendedDataRecordEx: start-on-event=GetEventExtendedDataRecordEx, operation=EventInfo_DEM_E_TEST_EVENT22.GetEventExtendedDataRecordEx
        OIE_EventInfo_DEM_E_TEST_EVENT22_GetEventFreezeFrameDataEx: start-on-event=GetEventFreezeFrameDataEx, operation=EventInfo_DEM_E_TEST_EVENT22.GetEventFreezeFrameDataEx
        OIE_EventInfo_DEM_E_TEST_EVENT22_GetEventUdsStatus: start-on-event=GetEventUdsStatus, operation=EventInfo_DEM_E_TEST_EVENT22.GetEventUdsStatus
        OIE_EventInfo_DEM_E_TEST_EVENT22_GetFaultDetectionCounter: start-on-event=GetFaultDetectionCounter, operation=EventInfo_DEM_E_TEST_EVENT22.GetFaultDetectionCounter
        OIE_EventInfo_DEM_E_TEST_EVENT22_GetMonitorStatus: start-on-event=GetMonitorStatus, operation=EventInfo_DEM_E_TEST_EVENT22.GetMonitorStatus
        OIE_EventInfo_DEM_E_TEST_EVENT2_GetDTCOfEvent: start-on-event=GetDTCOfEvent, operation=EventInfo_DEM_E_TEST_EVENT2.GetDTCOfEvent
        OIE_EventInfo_DEM_E_TEST_EVENT2_GetDebouncingOfEvent: start-on-event=GetDebouncingOfEvent, operation=EventInfo_DEM_E_TEST_EVENT2.GetDebouncingOfEvent
        OIE_EventInfo_DEM_E_TEST_EVENT2_GetEventExtendedDataRecordEx: start-on-event=GetEventExtendedDataRecordEx, operation=EventInfo_DEM_E_TEST_EVENT2.GetEventExtendedDataRecordEx
        OIE_EventInfo_DEM_E_TEST_EVENT2_GetEventFreezeFrameDataEx: start-on-event=GetEventFreezeFrameDataEx, operation=EventInfo_DEM_E_TEST_EVENT2.GetEventFreezeFrameDataEx
        OIE_EventInfo_DEM_E_TEST_EVENT2_GetEventUdsStatus: start-on-event=GetEventUdsStatus, operation=EventInfo_DEM_E_TEST_EVENT2.GetEventUdsStatus
        OIE_EventInfo_DEM_E_TEST_EVENT2_GetFaultDetectionCounter: start-on-event=GetFaultDetectionCounter, operation=EventInfo_DEM_E_TEST_EVENT2.GetFaultDetectionCounter
        OIE_EventInfo_DEM_E_TEST_EVENT2_GetMonitorStatus: start-on-event=GetMonitorStatus, operation=EventInfo_DEM_E_TEST_EVENT2.GetMonitorStatus
        OIE_EventInfo_DEM_E_TEST_EVENT3_GetDTCOfEvent: start-on-event=GetDTCOfEvent, operation=EventInfo_DEM_E_TEST_EVENT3.GetDTCOfEvent
        OIE_EventInfo_DEM_E_TEST_EVENT3_GetDebouncingOfEvent: start-on-event=GetDebouncingOfEvent, operation=EventInfo_DEM_E_TEST_EVENT3.GetDebouncingOfEvent
        OIE_EventInfo_DEM_E_TEST_EVENT3_GetEventExtendedDataRecordEx: start-on-event=GetEventExtendedDataRecordEx, operation=EventInfo_DEM_E_TEST_EVENT3.GetEventExtendedDataRecordEx
        OIE_EventInfo_DEM_E_TEST_EVENT3_GetEventFreezeFrameDataEx: start-on-event=GetEventFreezeFrameDataEx, operation=EventInfo_DEM_E_TEST_EVENT3.GetEventFreezeFrameDataEx
        OIE_EventInfo_DEM_E_TEST_EVENT3_GetEventUdsStatus: start-on-event=GetEventUdsStatus, operation=EventInfo_DEM_E_TEST_EVENT3.GetEventUdsStatus
        OIE_EventInfo_DEM_E_TEST_EVENT3_GetFaultDetectionCounter: start-on-event=GetFaultDetectionCounter, operation=EventInfo_DEM_E_TEST_EVENT3.GetFaultDetectionCounter
        OIE_EventInfo_DEM_E_TEST_EVENT3_GetMonitorStatus: start-on-event=GetMonitorStatus, operation=EventInfo_DEM_E_TEST_EVENT3.GetMonitorStatus
        OIE_EventInfo_DEM_E_TEST_EVENT4_GetDTCOfEvent: start-on-event=GetDTCOfEvent, operation=EventInfo_DEM_E_TEST_EVENT4.GetDTCOfEvent
        OIE_EventInfo_DEM_E_TEST_EVENT4_GetDebouncingOfEvent: start-on-event=GetDebouncingOfEvent, operation=EventInfo_DEM_E_TEST_EVENT4.GetDebouncingOfEvent
        OIE_EventInfo_DEM_E_TEST_EVENT4_GetEventExtendedDataRecordEx: start-on-event=GetEventExtendedDataRecordEx, operation=EventInfo_DEM_E_TEST_EVENT4.GetEventExtendedDataRecordEx
        OIE_EventInfo_DEM_E_TEST_EVENT4_GetEventFreezeFrameDataEx: start-on-event=GetEventFreezeFrameDataEx, operation=EventInfo_DEM_E_TEST_EVENT4.GetEventFreezeFrameDataEx
        OIE_EventInfo_DEM_E_TEST_EVENT4_GetEventUdsStatus: start-on-event=GetEventUdsStatus, operation=EventInfo_DEM_E_TEST_EVENT4.GetEventUdsStatus
        OIE_EventInfo_DEM_E_TEST_EVENT4_GetFaultDetectionCounter: start-on-event=GetFaultDetectionCounter, operation=EventInfo_DEM_E_TEST_EVENT4.GetFaultDetectionCounter
        OIE_EventInfo_DEM_E_TEST_EVENT4_GetMonitorStatus: start-on-event=GetMonitorStatus, operation=EventInfo_DEM_E_TEST_EVENT4.GetMonitorStatus
        OIE_EventInfo_DEM_E_TEST_EVENT5_GetDTCOfEvent: start-on-event=GetDTCOfEvent, operation=EventInfo_DEM_E_TEST_EVENT5.GetDTCOfEvent
        OIE_EventInfo_DEM_E_TEST_EVENT5_GetDebouncingOfEvent: start-on-event=GetDebouncingOfEvent, operation=EventInfo_DEM_E_TEST_EVENT5.GetDebouncingOfEvent
        OIE_EventInfo_DEM_E_TEST_EVENT5_GetEventExtendedDataRecordEx: start-on-event=GetEventExtendedDataRecordEx, operation=EventInfo_DEM_E_TEST_EVENT5.GetEventExtendedDataRecordEx
        OIE_EventInfo_DEM_E_TEST_EVENT5_GetEventFreezeFrameDataEx: start-on-event=GetEventFreezeFrameDataEx, operation=EventInfo_DEM_E_TEST_EVENT5.GetEventFreezeFrameDataEx
        OIE_EventInfo_DEM_E_TEST_EVENT5_GetEventUdsStatus: start-on-event=GetEventUdsStatus, operation=EventInfo_DEM_E_TEST_EVENT5.GetEventUdsStatus
        OIE_EventInfo_DEM_E_TEST_EVENT5_GetFaultDetectionCounter: start-on-event=GetFaultDetectionCounter, operation=EventInfo_DEM_E_TEST_EVENT5.GetFaultDetectionCounter
        OIE_EventInfo_DEM_E_TEST_EVENT5_GetMonitorStatus: start-on-event=GetMonitorStatus, operation=EventInfo_DEM_E_TEST_EVENT5.GetMonitorStatus
        OIE_EventInfo_DEM_E_TEST_EVENT6_GetDTCOfEvent: start-on-event=GetDTCOfEvent, operation=EventInfo_DEM_E_TEST_EVENT6.GetDTCOfEvent
        OIE_EventInfo_DEM_E_TEST_EVENT6_GetDebouncingOfEvent: start-on-event=GetDebouncingOfEvent, operation=EventInfo_DEM_E_TEST_EVENT6.GetDebouncingOfEvent
        OIE_EventInfo_DEM_E_TEST_EVENT6_GetEventExtendedDataRecordEx: start-on-event=GetEventExtendedDataRecordEx, operation=EventInfo_DEM_E_TEST_EVENT6.GetEventExtendedDataRecordEx
        OIE_EventInfo_DEM_E_TEST_EVENT6_GetEventFreezeFrameDataEx: start-on-event=GetEventFreezeFrameDataEx, operation=EventInfo_DEM_E_TEST_EVENT6.GetEventFreezeFrameDataEx
        OIE_EventInfo_DEM_E_TEST_EVENT6_GetEventUdsStatus: start-on-event=GetEventUdsStatus, operation=EventInfo_DEM_E_TEST_EVENT6.GetEventUdsStatus
        OIE_EventInfo_DEM_E_TEST_EVENT6_GetFaultDetectionCounter: start-on-event=GetFaultDetectionCounter, operation=EventInfo_DEM_E_TEST_EVENT6.GetFaultDetectionCounter
        OIE_EventInfo_DEM_E_TEST_EVENT6_GetMonitorStatus: start-on-event=GetMonitorStatus, operation=EventInfo_DEM_E_TEST_EVENT6.GetMonitorStatus
        OIE_EventInfo_DEM_E_TEST_EVENT7_GetDTCOfEvent: start-on-event=GetDTCOfEvent, operation=EventInfo_DEM_E_TEST_EVENT7.GetDTCOfEvent
        OIE_EventInfo_DEM_E_TEST_EVENT7_GetDebouncingOfEvent: start-on-event=GetDebouncingOfEvent, operation=EventInfo_DEM_E_TEST_EVENT7.GetDebouncingOfEvent
        OIE_EventInfo_DEM_E_TEST_EVENT7_GetEventExtendedDataRecordEx: start-on-event=GetEventExtendedDataRecordEx, operation=EventInfo_DEM_E_TEST_EVENT7.GetEventExtendedDataRecordEx
        OIE_EventInfo_DEM_E_TEST_EVENT7_GetEventFreezeFrameDataEx: start-on-event=GetEventFreezeFrameDataEx, operation=EventInfo_DEM_E_TEST_EVENT7.GetEventFreezeFrameDataEx
        OIE_EventInfo_DEM_E_TEST_EVENT7_GetEventUdsStatus: start-on-event=GetEventUdsStatus, operation=EventInfo_DEM_E_TEST_EVENT7.GetEventUdsStatus
        OIE_EventInfo_DEM_E_TEST_EVENT7_GetFaultDetectionCounter: start-on-event=GetFaultDetectionCounter, operation=EventInfo_DEM_E_TEST_EVENT7.GetFaultDetectionCounter
        OIE_EventInfo_DEM_E_TEST_EVENT7_GetMonitorStatus: start-on-event=GetMonitorStatus, operation=EventInfo_DEM_E_TEST_EVENT7.GetMonitorStatus
        OIE_EventInfo_DEM_E_TEST_EVENT8_GetDTCOfEvent: start-on-event=GetDTCOfEvent, operation=EventInfo_DEM_E_TEST_EVENT8.GetDTCOfEvent
        OIE_EventInfo_DEM_E_TEST_EVENT8_GetDebouncingOfEvent: start-on-event=GetDebouncingOfEvent, operation=EventInfo_DEM_E_TEST_EVENT8.GetDebouncingOfEvent
        OIE_EventInfo_DEM_E_TEST_EVENT8_GetEventExtendedDataRecordEx: start-on-event=GetEventExtendedDataRecordEx, operation=EventInfo_DEM_E_TEST_EVENT8.GetEventExtendedDataRecordEx
        OIE_EventInfo_DEM_E_TEST_EVENT8_GetEventFreezeFrameDataEx: start-on-event=GetEventFreezeFrameDataEx, operation=EventInfo_DEM_E_TEST_EVENT8.GetEventFreezeFrameDataEx
        OIE_EventInfo_DEM_E_TEST_EVENT8_GetEventUdsStatus: start-on-event=GetEventUdsStatus, operation=EventInfo_DEM_E_TEST_EVENT8.GetEventUdsStatus
        OIE_EventInfo_DEM_E_TEST_EVENT8_GetFaultDetectionCounter: start-on-event=GetFaultDetectionCounter, operation=EventInfo_DEM_E_TEST_EVENT8.GetFaultDetectionCounter
        OIE_EventInfo_DEM_E_TEST_EVENT8_GetMonitorStatus: start-on-event=GetMonitorStatus, operation=EventInfo_DEM_E_TEST_EVENT8.GetMonitorStatus
        OIE_EventInfo_DEM_E_TEST_EVENT9_GetDTCOfEvent: start-on-event=GetDTCOfEvent, operation=EventInfo_DEM_E_TEST_EVENT9.GetDTCOfEvent
        OIE_EventInfo_DEM_E_TEST_EVENT9_GetDebouncingOfEvent: start-on-event=GetDebouncingOfEvent, operation=EventInfo_DEM_E_TEST_EVENT9.GetDebouncingOfEvent
        OIE_EventInfo_DEM_E_TEST_EVENT9_GetEventExtendedDataRecordEx: start-on-event=GetEventExtendedDataRecordEx, operation=EventInfo_DEM_E_TEST_EVENT9.GetEventExtendedDataRecordEx
        OIE_EventInfo_DEM_E_TEST_EVENT9_GetEventFreezeFrameDataEx: start-on-event=GetEventFreezeFrameDataEx, operation=EventInfo_DEM_E_TEST_EVENT9.GetEventFreezeFrameDataEx
        OIE_EventInfo_DEM_E_TEST_EVENT9_GetEventUdsStatus: start-on-event=GetEventUdsStatus, operation=EventInfo_DEM_E_TEST_EVENT9.GetEventUdsStatus
        OIE_EventInfo_DEM_E_TEST_EVENT9_GetFaultDetectionCounter: start-on-event=GetFaultDetectionCounter, operation=EventInfo_DEM_E_TEST_EVENT9.GetFaultDetectionCounter
        OIE_EventInfo_DEM_E_TEST_EVENT9_GetMonitorStatus: start-on-event=GetMonitorStatus, operation=EventInfo_DEM_E_TEST_EVENT9.GetMonitorStatus
        OIE_EventInfo_DEM_E_TEST_EVENT_E2EXF_MALFORMED_MESSAGE_GetDTCOfEvent: start-on-event=GetDTCOfEvent, operation=EventInfo_DEM_E_TEST_EVENT_E2EXF_MALFORMED_MESSAGE.GetDTCOfEvent
        OIE_EventInfo_DEM_E_TEST_EVENT_E2EXF_MALFORMED_MESSAGE_GetDebouncingOfEvent: start-on-event=GetDebouncingOfEvent, operation=EventInfo_DEM_E_TEST_EVENT_E2EXF_MALFORMED_MESSAGE.GetDebouncingOfEvent
        OIE_EventInfo_DEM_E_TEST_EVENT_E2EXF_MALFORMED_MESSAGE_GetEventExtendedDataRecordEx: start-on-event=GetEventExtendedDataRecordEx, operation=EventInfo_DEM_E_TEST_EVENT_E2EXF_MALFORMED_MESSAGE.GetEventExtendedDataRecordEx
        OIE_EventInfo_DEM_E_TEST_EVENT_E2EXF_MALFORMED_MESSAGE_GetEventFreezeFrameDataEx: start-on-event=GetEventFreezeFrameDataEx, operation=EventInfo_DEM_E_TEST_EVENT_E2EXF_MALFORMED_MESSAGE.GetEventFreezeFrameDataEx
        OIE_EventInfo_DEM_E_TEST_EVENT_E2EXF_MALFORMED_MESSAGE_GetEventUdsStatus: start-on-event=GetEventUdsStatus, operation=EventInfo_DEM_E_TEST_EVENT_E2EXF_MALFORMED_MESSAGE.GetEventUdsStatus
        OIE_EventInfo_DEM_E_TEST_EVENT_E2EXF_MALFORMED_MESSAGE_GetFaultDetectionCounter: start-on-event=GetFaultDetectionCounter, operation=EventInfo_DEM_E_TEST_EVENT_E2EXF_MALFORMED_MESSAGE.GetFaultDetectionCounter
        OIE_EventInfo_DEM_E_TEST_EVENT_E2EXF_MALFORMED_MESSAGE_GetMonitorStatus: start-on-event=GetMonitorStatus, operation=EventInfo_DEM_E_TEST_EVENT_E2EXF_MALFORMED_MESSAGE.GetMonitorStatus
        OIE_EventInfo_DEM_E_TEST_EVENT_SOMEIPXF_MALFORMED_MESSAGE_GetDTCOfEvent: start-on-event=GetDTCOfEvent, operation=EventInfo_DEM_E_TEST_EVENT_SOMEIPXF_MALFORMED_MESSAGE.GetDTCOfEvent
        OIE_EventInfo_DEM_E_TEST_EVENT_SOMEIPXF_MALFORMED_MESSAGE_GetDebouncingOfEvent: start-on-event=GetDebouncingOfEvent, operation=EventInfo_DEM_E_TEST_EVENT_SOMEIPXF_MALFORMED_MESSAGE.GetDebouncingOfEvent
        OIE_EventInfo_DEM_E_TEST_EVENT_SOMEIPXF_MALFORMED_MESSAGE_GetEventExtendedDataRecordEx: start-on-event=GetEventExtendedDataRecordEx, operation=EventInfo_DEM_E_TEST_EVENT_SOMEIPXF_MALFORMED_MESSAGE.GetEventExtendedDataRecordEx
        OIE_EventInfo_DEM_E_TEST_EVENT_SOMEIPXF_MALFORMED_MESSAGE_GetEventFreezeFrameDataEx: start-on-event=GetEventFreezeFrameDataEx, operation=EventInfo_DEM_E_TEST_EVENT_SOMEIPXF_MALFORMED_MESSAGE.GetEventFreezeFrameDataEx
        OIE_EventInfo_DEM_E_TEST_EVENT_SOMEIPXF_MALFORMED_MESSAGE_GetEventUdsStatus: start-on-event=GetEventUdsStatus, operation=EventInfo_DEM_E_TEST_EVENT_SOMEIPXF_MALFORMED_MESSAGE.GetEventUdsStatus
        OIE_EventInfo_DEM_E_TEST_EVENT_SOMEIPXF_MALFORMED_MESSAGE_GetFaultDetectionCounter: start-on-event=GetFaultDetectionCounter, operation=EventInfo_DEM_E_TEST_EVENT_SOMEIPXF_MALFORMED_MESSAGE.GetFaultDetectionCounter
        OIE_EventInfo_DEM_E_TEST_EVENT_SOMEIPXF_MALFORMED_MESSAGE_GetMonitorStatus: start-on-event=GetMonitorStatus, operation=EventInfo_DEM_E_TEST_EVENT_SOMEIPXF_MALFORMED_MESSAGE.GetMonitorStatus
        OIE_EventInfo_ECUM_E_CONFIGURATION_DATA_INCONSISTENT_GetDTCOfEvent: start-on-event=GetDTCOfEvent, operation=EventInfo_ECUM_E_CONFIGURATION_DATA_INCONSISTENT.GetDTCOfEvent
        OIE_EventInfo_ECUM_E_CONFIGURATION_DATA_INCONSISTENT_GetDebouncingOfEvent: start-on-event=GetDebouncingOfEvent, operation=EventInfo_ECUM_E_CONFIGURATION_DATA_INCONSISTENT.GetDebouncingOfEvent
        OIE_EventInfo_ECUM_E_CONFIGURATION_DATA_INCONSISTENT_GetEventExtendedDataRecordEx: start-on-event=GetEventExtendedDataRecordEx, operation=EventInfo_ECUM_E_CONFIGURATION_DATA_INCONSISTENT.GetEventExtendedDataRecordEx
        OIE_EventInfo_ECUM_E_CONFIGURATION_DATA_INCONSISTENT_GetEventFreezeFrameDataEx: start-on-event=GetEventFreezeFrameDataEx, operation=EventInfo_ECUM_E_CONFIGURATION_DATA_INCONSISTENT.GetEventFreezeFrameDataEx
        OIE_EventInfo_ECUM_E_CONFIGURATION_DATA_INCONSISTENT_GetEventUdsStatus: start-on-event=GetEventUdsStatus, operation=EventInfo_ECUM_E_CONFIGURATION_DATA_INCONSISTENT.GetEventUdsStatus
        OIE_EventInfo_ECUM_E_CONFIGURATION_DATA_INCONSISTENT_GetFaultDetectionCounter: start-on-event=GetFaultDetectionCounter, operation=EventInfo_ECUM_E_CONFIGURATION_DATA_INCONSISTENT.GetFaultDetectionCounter
        OIE_EventInfo_ECUM_E_CONFIGURATION_DATA_INCONSISTENT_GetMonitorStatus: start-on-event=GetMonitorStatus, operation=EventInfo_ECUM_E_CONFIGURATION_DATA_INCONSISTENT.GetMonitorStatus
        OIE_EventInfo_ECUM_E_IMPROPER_CALLER_GetDTCOfEvent: start-on-event=GetDTCOfEvent, operation=EventInfo_ECUM_E_IMPROPER_CALLER.GetDTCOfEvent
        OIE_EventInfo_ECUM_E_IMPROPER_CALLER_GetDebouncingOfEvent: start-on-event=GetDebouncingOfEvent, operation=EventInfo_ECUM_E_IMPROPER_CALLER.GetDebouncingOfEvent
        OIE_EventInfo_ECUM_E_IMPROPER_CALLER_GetEventExtendedDataRecordEx: start-on-event=GetEventExtendedDataRecordEx, operation=EventInfo_ECUM_E_IMPROPER_CALLER.GetEventExtendedDataRecordEx
        OIE_EventInfo_ECUM_E_IMPROPER_CALLER_GetEventFreezeFrameDataEx: start-on-event=GetEventFreezeFrameDataEx, operation=EventInfo_ECUM_E_IMPROPER_CALLER.GetEventFreezeFrameDataEx
        OIE_EventInfo_ECUM_E_IMPROPER_CALLER_GetEventUdsStatus: start-on-event=GetEventUdsStatus, operation=EventInfo_ECUM_E_IMPROPER_CALLER.GetEventUdsStatus
        OIE_EventInfo_ECUM_E_IMPROPER_CALLER_GetFaultDetectionCounter: start-on-event=GetFaultDetectionCounter, operation=EventInfo_ECUM_E_IMPROPER_CALLER.GetFaultDetectionCounter
        OIE_EventInfo_ECUM_E_IMPROPER_CALLER_GetMonitorStatus: start-on-event=GetMonitorStatus, operation=EventInfo_ECUM_E_IMPROPER_CALLER.GetMonitorStatus
        OIE_EventInfo_ECUM_E_RAM_CHECK_FAILED_GetDTCOfEvent: start-on-event=GetDTCOfEvent, operation=EventInfo_ECUM_E_RAM_CHECK_FAILED.GetDTCOfEvent
        OIE_EventInfo_ECUM_E_RAM_CHECK_FAILED_GetDebouncingOfEvent: start-on-event=GetDebouncingOfEvent, operation=EventInfo_ECUM_E_RAM_CHECK_FAILED.GetDebouncingOfEvent
        OIE_EventInfo_ECUM_E_RAM_CHECK_FAILED_GetEventExtendedDataRecordEx: start-on-event=GetEventExtendedDataRecordEx, operation=EventInfo_ECUM_E_RAM_CHECK_FAILED.GetEventExtendedDataRecordEx
        OIE_EventInfo_ECUM_E_RAM_CHECK_FAILED_GetEventFreezeFrameDataEx: start-on-event=GetEventFreezeFrameDataEx, operation=EventInfo_ECUM_E_RAM_CHECK_FAILED.GetEventFreezeFrameDataEx
        OIE_EventInfo_ECUM_E_RAM_CHECK_FAILED_GetEventUdsStatus: start-on-event=GetEventUdsStatus, operation=EventInfo_ECUM_E_RAM_CHECK_FAILED.GetEventUdsStatus
        OIE_EventInfo_ECUM_E_RAM_CHECK_FAILED_GetFaultDetectionCounter: start-on-event=GetFaultDetectionCounter, operation=EventInfo_ECUM_E_RAM_CHECK_FAILED.GetFaultDetectionCounter
        OIE_EventInfo_ECUM_E_RAM_CHECK_FAILED_GetMonitorStatus: start-on-event=GetMonitorStatus, operation=EventInfo_ECUM_E_RAM_CHECK_FAILED.GetMonitorStatus
        OIE_EventInfo_EEP_E_COMPARE_FAILED_GetDTCOfEvent: start-on-event=GetDTCOfEvent, operation=EventInfo_EEP_E_COMPARE_FAILED.GetDTCOfEvent
        OIE_EventInfo_EEP_E_COMPARE_FAILED_GetDebouncingOfEvent: start-on-event=GetDebouncingOfEvent, operation=EventInfo_EEP_E_COMPARE_FAILED.GetDebouncingOfEvent
        OIE_EventInfo_EEP_E_COMPARE_FAILED_GetEventExtendedDataRecordEx: start-on-event=GetEventExtendedDataRecordEx, operation=EventInfo_EEP_E_COMPARE_FAILED.GetEventExtendedDataRecordEx
        OIE_EventInfo_EEP_E_COMPARE_FAILED_GetEventFreezeFrameDataEx: start-on-event=GetEventFreezeFrameDataEx, operation=EventInfo_EEP_E_COMPARE_FAILED.GetEventFreezeFrameDataEx
        OIE_EventInfo_EEP_E_COMPARE_FAILED_GetEventUdsStatus: start-on-event=GetEventUdsStatus, operation=EventInfo_EEP_E_COMPARE_FAILED.GetEventUdsStatus
        OIE_EventInfo_EEP_E_COMPARE_FAILED_GetFaultDetectionCounter: start-on-event=GetFaultDetectionCounter, operation=EventInfo_EEP_E_COMPARE_FAILED.GetFaultDetectionCounter
        OIE_EventInfo_EEP_E_COMPARE_FAILED_GetMonitorStatus: start-on-event=GetMonitorStatus, operation=EventInfo_EEP_E_COMPARE_FAILED.GetMonitorStatus
        OIE_EventInfo_EEP_E_ERASE_FAILED_GetDTCOfEvent: start-on-event=GetDTCOfEvent, operation=EventInfo_EEP_E_ERASE_FAILED.GetDTCOfEvent
        OIE_EventInfo_EEP_E_ERASE_FAILED_GetDebouncingOfEvent: start-on-event=GetDebouncingOfEvent, operation=EventInfo_EEP_E_ERASE_FAILED.GetDebouncingOfEvent
        OIE_EventInfo_EEP_E_ERASE_FAILED_GetEventExtendedDataRecordEx: start-on-event=GetEventExtendedDataRecordEx, operation=EventInfo_EEP_E_ERASE_FAILED.GetEventExtendedDataRecordEx
        OIE_EventInfo_EEP_E_ERASE_FAILED_GetEventFreezeFrameDataEx: start-on-event=GetEventFreezeFrameDataEx, operation=EventInfo_EEP_E_ERASE_FAILED.GetEventFreezeFrameDataEx
        OIE_EventInfo_EEP_E_ERASE_FAILED_GetEventUdsStatus: start-on-event=GetEventUdsStatus, operation=EventInfo_EEP_E_ERASE_FAILED.GetEventUdsStatus
        OIE_EventInfo_EEP_E_ERASE_FAILED_GetFaultDetectionCounter: start-on-event=GetFaultDetectionCounter, operation=EventInfo_EEP_E_ERASE_FAILED.GetFaultDetectionCounter
        OIE_EventInfo_EEP_E_ERASE_FAILED_GetMonitorStatus: start-on-event=GetMonitorStatus, operation=EventInfo_EEP_E_ERASE_FAILED.GetMonitorStatus
        OIE_EventInfo_EEP_E_READ_FAILED_GetDTCOfEvent: start-on-event=GetDTCOfEvent, operation=EventInfo_EEP_E_READ_FAILED.GetDTCOfEvent
        OIE_EventInfo_EEP_E_READ_FAILED_GetDebouncingOfEvent: start-on-event=GetDebouncingOfEvent, operation=EventInfo_EEP_E_READ_FAILED.GetDebouncingOfEvent
        OIE_EventInfo_EEP_E_READ_FAILED_GetEventExtendedDataRecordEx: start-on-event=GetEventExtendedDataRecordEx, operation=EventInfo_EEP_E_READ_FAILED.GetEventExtendedDataRecordEx
        OIE_EventInfo_EEP_E_READ_FAILED_GetEventFreezeFrameDataEx: start-on-event=GetEventFreezeFrameDataEx, operation=EventInfo_EEP_E_READ_FAILED.GetEventFreezeFrameDataEx
        OIE_EventInfo_EEP_E_READ_FAILED_GetEventUdsStatus: start-on-event=GetEventUdsStatus, operation=EventInfo_EEP_E_READ_FAILED.GetEventUdsStatus
        OIE_EventInfo_EEP_E_READ_FAILED_GetFaultDetectionCounter: start-on-event=GetFaultDetectionCounter, operation=EventInfo_EEP_E_READ_FAILED.GetFaultDetectionCounter
        OIE_EventInfo_EEP_E_READ_FAILED_GetMonitorStatus: start-on-event=GetMonitorStatus, operation=EventInfo_EEP_E_READ_FAILED.GetMonitorStatus
        OIE_EventInfo_EEP_E_WRITE_FAILED_GetDTCOfEvent: start-on-event=GetDTCOfEvent, operation=EventInfo_EEP_E_WRITE_FAILED.GetDTCOfEvent
        OIE_EventInfo_EEP_E_WRITE_FAILED_GetDebouncingOfEvent: start-on-event=GetDebouncingOfEvent, operation=EventInfo_EEP_E_WRITE_FAILED.GetDebouncingOfEvent
        OIE_EventInfo_EEP_E_WRITE_FAILED_GetEventExtendedDataRecordEx: start-on-event=GetEventExtendedDataRecordEx, operation=EventInfo_EEP_E_WRITE_FAILED.GetEventExtendedDataRecordEx
        OIE_EventInfo_EEP_E_WRITE_FAILED_GetEventFreezeFrameDataEx: start-on-event=GetEventFreezeFrameDataEx, operation=EventInfo_EEP_E_WRITE_FAILED.GetEventFreezeFrameDataEx
        OIE_EventInfo_EEP_E_WRITE_FAILED_GetEventUdsStatus: start-on-event=GetEventUdsStatus, operation=EventInfo_EEP_E_WRITE_FAILED.GetEventUdsStatus
        OIE_EventInfo_EEP_E_WRITE_FAILED_GetFaultDetectionCounter: start-on-event=GetFaultDetectionCounter, operation=EventInfo_EEP_E_WRITE_FAILED.GetFaultDetectionCounter
        OIE_EventInfo_EEP_E_WRITE_FAILED_GetMonitorStatus: start-on-event=GetMonitorStatus, operation=EventInfo_EEP_E_WRITE_FAILED.GetMonitorStatus
        OIE_EventInfo_ETHSM_E_LINK_DOWN_GetDTCOfEvent: start-on-event=GetDTCOfEvent, operation=EventInfo_ETHSM_E_LINK_DOWN.GetDTCOfEvent
        OIE_EventInfo_ETHSM_E_LINK_DOWN_GetDebouncingOfEvent: start-on-event=GetDebouncingOfEvent, operation=EventInfo_ETHSM_E_LINK_DOWN.GetDebouncingOfEvent
        OIE_EventInfo_ETHSM_E_LINK_DOWN_GetEventExtendedDataRecordEx: start-on-event=GetEventExtendedDataRecordEx, operation=EventInfo_ETHSM_E_LINK_DOWN.GetEventExtendedDataRecordEx
        OIE_EventInfo_ETHSM_E_LINK_DOWN_GetEventFreezeFrameDataEx: start-on-event=GetEventFreezeFrameDataEx, operation=EventInfo_ETHSM_E_LINK_DOWN.GetEventFreezeFrameDataEx
        OIE_EventInfo_ETHSM_E_LINK_DOWN_GetEventUdsStatus: start-on-event=GetEventUdsStatus, operation=EventInfo_ETHSM_E_LINK_DOWN.GetEventUdsStatus
        OIE_EventInfo_ETHSM_E_LINK_DOWN_GetFaultDetectionCounter: start-on-event=GetFaultDetectionCounter, operation=EventInfo_ETHSM_E_LINK_DOWN.GetFaultDetectionCounter
        OIE_EventInfo_ETHSM_E_LINK_DOWN_GetMonitorStatus: start-on-event=GetMonitorStatus, operation=EventInfo_ETHSM_E_LINK_DOWN.GetMonitorStatus
        OIE_EventInfo_ETHTRCV_E_ACCESS_GetDTCOfEvent: start-on-event=GetDTCOfEvent, operation=EventInfo_ETHTRCV_E_ACCESS.GetDTCOfEvent
        OIE_EventInfo_ETHTRCV_E_ACCESS_GetDebouncingOfEvent: start-on-event=GetDebouncingOfEvent, operation=EventInfo_ETHTRCV_E_ACCESS.GetDebouncingOfEvent
        OIE_EventInfo_ETHTRCV_E_ACCESS_GetEventExtendedDataRecordEx: start-on-event=GetEventExtendedDataRecordEx, operation=EventInfo_ETHTRCV_E_ACCESS.GetEventExtendedDataRecordEx
        OIE_EventInfo_ETHTRCV_E_ACCESS_GetEventFreezeFrameDataEx: start-on-event=GetEventFreezeFrameDataEx, operation=EventInfo_ETHTRCV_E_ACCESS.GetEventFreezeFrameDataEx
        OIE_EventInfo_ETHTRCV_E_ACCESS_GetEventUdsStatus: start-on-event=GetEventUdsStatus, operation=EventInfo_ETHTRCV_E_ACCESS.GetEventUdsStatus
        OIE_EventInfo_ETHTRCV_E_ACCESS_GetFaultDetectionCounter: start-on-event=GetFaultDetectionCounter, operation=EventInfo_ETHTRCV_E_ACCESS.GetFaultDetectionCounter
        OIE_EventInfo_ETHTRCV_E_ACCESS_GetMonitorStatus: start-on-event=GetMonitorStatus, operation=EventInfo_ETHTRCV_E_ACCESS.GetMonitorStatus
        OIE_EventInfo_ETH_E_ACCESS_GetDTCOfEvent: start-on-event=GetDTCOfEvent, operation=EventInfo_ETH_E_ACCESS.GetDTCOfEvent
        OIE_EventInfo_ETH_E_ACCESS_GetDebouncingOfEvent: start-on-event=GetDebouncingOfEvent, operation=EventInfo_ETH_E_ACCESS.GetDebouncingOfEvent
        OIE_EventInfo_ETH_E_ACCESS_GetEventExtendedDataRecordEx: start-on-event=GetEventExtendedDataRecordEx, operation=EventInfo_ETH_E_ACCESS.GetEventExtendedDataRecordEx
        OIE_EventInfo_ETH_E_ACCESS_GetEventFreezeFrameDataEx: start-on-event=GetEventFreezeFrameDataEx, operation=EventInfo_ETH_E_ACCESS.GetEventFreezeFrameDataEx
        OIE_EventInfo_ETH_E_ACCESS_GetEventUdsStatus: start-on-event=GetEventUdsStatus, operation=EventInfo_ETH_E_ACCESS.GetEventUdsStatus
        OIE_EventInfo_ETH_E_ACCESS_GetFaultDetectionCounter: start-on-event=GetFaultDetectionCounter, operation=EventInfo_ETH_E_ACCESS.GetFaultDetectionCounter
        OIE_EventInfo_ETH_E_ACCESS_GetMonitorStatus: start-on-event=GetMonitorStatus, operation=EventInfo_ETH_E_ACCESS.GetMonitorStatus
        OIE_EventInfo_ETH_E_ALIGNMENT_GetDTCOfEvent: start-on-event=GetDTCOfEvent, operation=EventInfo_ETH_E_ALIGNMENT.GetDTCOfEvent
        OIE_EventInfo_ETH_E_ALIGNMENT_GetDebouncingOfEvent: start-on-event=GetDebouncingOfEvent, operation=EventInfo_ETH_E_ALIGNMENT.GetDebouncingOfEvent
        OIE_EventInfo_ETH_E_ALIGNMENT_GetEventExtendedDataRecordEx: start-on-event=GetEventExtendedDataRecordEx, operation=EventInfo_ETH_E_ALIGNMENT.GetEventExtendedDataRecordEx
        OIE_EventInfo_ETH_E_ALIGNMENT_GetEventFreezeFrameDataEx: start-on-event=GetEventFreezeFrameDataEx, operation=EventInfo_ETH_E_ALIGNMENT.GetEventFreezeFrameDataEx
        OIE_EventInfo_ETH_E_ALIGNMENT_GetEventUdsStatus: start-on-event=GetEventUdsStatus, operation=EventInfo_ETH_E_ALIGNMENT.GetEventUdsStatus
        OIE_EventInfo_ETH_E_ALIGNMENT_GetFaultDetectionCounter: start-on-event=GetFaultDetectionCounter, operation=EventInfo_ETH_E_ALIGNMENT.GetFaultDetectionCounter
        OIE_EventInfo_ETH_E_ALIGNMENT_GetMonitorStatus: start-on-event=GetMonitorStatus, operation=EventInfo_ETH_E_ALIGNMENT.GetMonitorStatus
        OIE_EventInfo_ETH_E_CRC_GetDTCOfEvent: start-on-event=GetDTCOfEvent, operation=EventInfo_ETH_E_CRC.GetDTCOfEvent
        OIE_EventInfo_ETH_E_CRC_GetDebouncingOfEvent: start-on-event=GetDebouncingOfEvent, operation=EventInfo_ETH_E_CRC.GetDebouncingOfEvent
        OIE_EventInfo_ETH_E_CRC_GetEventExtendedDataRecordEx: start-on-event=GetEventExtendedDataRecordEx, operation=EventInfo_ETH_E_CRC.GetEventExtendedDataRecordEx
        OIE_EventInfo_ETH_E_CRC_GetEventFreezeFrameDataEx: start-on-event=GetEventFreezeFrameDataEx, operation=EventInfo_ETH_E_CRC.GetEventFreezeFrameDataEx
        OIE_EventInfo_ETH_E_CRC_GetEventUdsStatus: start-on-event=GetEventUdsStatus, operation=EventInfo_ETH_E_CRC.GetEventUdsStatus
        OIE_EventInfo_ETH_E_CRC_GetFaultDetectionCounter: start-on-event=GetFaultDetectionCounter, operation=EventInfo_ETH_E_CRC.GetFaultDetectionCounter
        OIE_EventInfo_ETH_E_CRC_GetMonitorStatus: start-on-event=GetMonitorStatus, operation=EventInfo_ETH_E_CRC.GetMonitorStatus
        OIE_EventInfo_ETH_E_LATECOLLISON_GetDTCOfEvent: start-on-event=GetDTCOfEvent, operation=EventInfo_ETH_E_LATECOLLISON.GetDTCOfEvent
        OIE_EventInfo_ETH_E_LATECOLLISON_GetDebouncingOfEvent: start-on-event=GetDebouncingOfEvent, operation=EventInfo_ETH_E_LATECOLLISON.GetDebouncingOfEvent
        OIE_EventInfo_ETH_E_LATECOLLISON_GetEventExtendedDataRecordEx: start-on-event=GetEventExtendedDataRecordEx, operation=EventInfo_ETH_E_LATECOLLISON.GetEventExtendedDataRecordEx
        OIE_EventInfo_ETH_E_LATECOLLISON_GetEventFreezeFrameDataEx: start-on-event=GetEventFreezeFrameDataEx, operation=EventInfo_ETH_E_LATECOLLISON.GetEventFreezeFrameDataEx
        OIE_EventInfo_ETH_E_LATECOLLISON_GetEventUdsStatus: start-on-event=GetEventUdsStatus, operation=EventInfo_ETH_E_LATECOLLISON.GetEventUdsStatus
        OIE_EventInfo_ETH_E_LATECOLLISON_GetFaultDetectionCounter: start-on-event=GetFaultDetectionCounter, operation=EventInfo_ETH_E_LATECOLLISON.GetFaultDetectionCounter
        OIE_EventInfo_ETH_E_LATECOLLISON_GetMonitorStatus: start-on-event=GetMonitorStatus, operation=EventInfo_ETH_E_LATECOLLISON.GetMonitorStatus
        OIE_EventInfo_ETH_E_MULTIPLECOLLISION_GetDTCOfEvent: start-on-event=GetDTCOfEvent, operation=EventInfo_ETH_E_MULTIPLECOLLISION.GetDTCOfEvent
        OIE_EventInfo_ETH_E_MULTIPLECOLLISION_GetDebouncingOfEvent: start-on-event=GetDebouncingOfEvent, operation=EventInfo_ETH_E_MULTIPLECOLLISION.GetDebouncingOfEvent
        OIE_EventInfo_ETH_E_MULTIPLECOLLISION_GetEventExtendedDataRecordEx: start-on-event=GetEventExtendedDataRecordEx, operation=EventInfo_ETH_E_MULTIPLECOLLISION.GetEventExtendedDataRecordEx
        OIE_EventInfo_ETH_E_MULTIPLECOLLISION_GetEventFreezeFrameDataEx: start-on-event=GetEventFreezeFrameDataEx, operation=EventInfo_ETH_E_MULTIPLECOLLISION.GetEventFreezeFrameDataEx
        OIE_EventInfo_ETH_E_MULTIPLECOLLISION_GetEventUdsStatus: start-on-event=GetEventUdsStatus, operation=EventInfo_ETH_E_MULTIPLECOLLISION.GetEventUdsStatus
        OIE_EventInfo_ETH_E_MULTIPLECOLLISION_GetFaultDetectionCounter: start-on-event=GetFaultDetectionCounter, operation=EventInfo_ETH_E_MULTIPLECOLLISION.GetFaultDetectionCounter
        OIE_EventInfo_ETH_E_MULTIPLECOLLISION_GetMonitorStatus: start-on-event=GetMonitorStatus, operation=EventInfo_ETH_E_MULTIPLECOLLISION.GetMonitorStatus
        OIE_EventInfo_ETH_E_OVERSIZEFRAME_GetDTCOfEvent: start-on-event=GetDTCOfEvent, operation=EventInfo_ETH_E_OVERSIZEFRAME.GetDTCOfEvent
        OIE_EventInfo_ETH_E_OVERSIZEFRAME_GetDebouncingOfEvent: start-on-event=GetDebouncingOfEvent, operation=EventInfo_ETH_E_OVERSIZEFRAME.GetDebouncingOfEvent
        OIE_EventInfo_ETH_E_OVERSIZEFRAME_GetEventExtendedDataRecordEx: start-on-event=GetEventExtendedDataRecordEx, operation=EventInfo_ETH_E_OVERSIZEFRAME.GetEventExtendedDataRecordEx
        OIE_EventInfo_ETH_E_OVERSIZEFRAME_GetEventFreezeFrameDataEx: start-on-event=GetEventFreezeFrameDataEx, operation=EventInfo_ETH_E_OVERSIZEFRAME.GetEventFreezeFrameDataEx
        OIE_EventInfo_ETH_E_OVERSIZEFRAME_GetEventUdsStatus: start-on-event=GetEventUdsStatus, operation=EventInfo_ETH_E_OVERSIZEFRAME.GetEventUdsStatus
        OIE_EventInfo_ETH_E_OVERSIZEFRAME_GetFaultDetectionCounter: start-on-event=GetFaultDetectionCounter, operation=EventInfo_ETH_E_OVERSIZEFRAME.GetFaultDetectionCounter
        OIE_EventInfo_ETH_E_OVERSIZEFRAME_GetMonitorStatus: start-on-event=GetMonitorStatus, operation=EventInfo_ETH_E_OVERSIZEFRAME.GetMonitorStatus
        OIE_EventInfo_ETH_E_RX_FRAMES_LOST_GetDTCOfEvent: start-on-event=GetDTCOfEvent, operation=EventInfo_ETH_E_RX_FRAMES_LOST.GetDTCOfEvent
        OIE_EventInfo_ETH_E_RX_FRAMES_LOST_GetDebouncingOfEvent: start-on-event=GetDebouncingOfEvent, operation=EventInfo_ETH_E_RX_FRAMES_LOST.GetDebouncingOfEvent
        OIE_EventInfo_ETH_E_RX_FRAMES_LOST_GetEventExtendedDataRecordEx: start-on-event=GetEventExtendedDataRecordEx, operation=EventInfo_ETH_E_RX_FRAMES_LOST.GetEventExtendedDataRecordEx
        OIE_EventInfo_ETH_E_RX_FRAMES_LOST_GetEventFreezeFrameDataEx: start-on-event=GetEventFreezeFrameDataEx, operation=EventInfo_ETH_E_RX_FRAMES_LOST.GetEventFreezeFrameDataEx
        OIE_EventInfo_ETH_E_RX_FRAMES_LOST_GetEventUdsStatus: start-on-event=GetEventUdsStatus, operation=EventInfo_ETH_E_RX_FRAMES_LOST.GetEventUdsStatus
        OIE_EventInfo_ETH_E_RX_FRAMES_LOST_GetFaultDetectionCounter: start-on-event=GetFaultDetectionCounter, operation=EventInfo_ETH_E_RX_FRAMES_LOST.GetFaultDetectionCounter
        OIE_EventInfo_ETH_E_RX_FRAMES_LOST_GetMonitorStatus: start-on-event=GetMonitorStatus, operation=EventInfo_ETH_E_RX_FRAMES_LOST.GetMonitorStatus
        OIE_EventInfo_ETH_E_SINGLECOLLISION_GetDTCOfEvent: start-on-event=GetDTCOfEvent, operation=EventInfo_ETH_E_SINGLECOLLISION.GetDTCOfEvent
        OIE_EventInfo_ETH_E_SINGLECOLLISION_GetDebouncingOfEvent: start-on-event=GetDebouncingOfEvent, operation=EventInfo_ETH_E_SINGLECOLLISION.GetDebouncingOfEvent
        OIE_EventInfo_ETH_E_SINGLECOLLISION_GetEventExtendedDataRecordEx: start-on-event=GetEventExtendedDataRecordEx, operation=EventInfo_ETH_E_SINGLECOLLISION.GetEventExtendedDataRecordEx
        OIE_EventInfo_ETH_E_SINGLECOLLISION_GetEventFreezeFrameDataEx: start-on-event=GetEventFreezeFrameDataEx, operation=EventInfo_ETH_E_SINGLECOLLISION.GetEventFreezeFrameDataEx
        OIE_EventInfo_ETH_E_SINGLECOLLISION_GetEventUdsStatus: start-on-event=GetEventUdsStatus, operation=EventInfo_ETH_E_SINGLECOLLISION.GetEventUdsStatus
        OIE_EventInfo_ETH_E_SINGLECOLLISION_GetFaultDetectionCounter: start-on-event=GetFaultDetectionCounter, operation=EventInfo_ETH_E_SINGLECOLLISION.GetFaultDetectionCounter
        OIE_EventInfo_ETH_E_SINGLECOLLISION_GetMonitorStatus: start-on-event=GetMonitorStatus, operation=EventInfo_ETH_E_SINGLECOLLISION.GetMonitorStatus
        OIE_EventInfo_ETH_E_UNDERSIZRFRAME_GetDTCOfEvent: start-on-event=GetDTCOfEvent, operation=EventInfo_ETH_E_UNDERSIZRFRAME.GetDTCOfEvent
        OIE_EventInfo_ETH_E_UNDERSIZRFRAME_GetDebouncingOfEvent: start-on-event=GetDebouncingOfEvent, operation=EventInfo_ETH_E_UNDERSIZRFRAME.GetDebouncingOfEvent
        OIE_EventInfo_ETH_E_UNDERSIZRFRAME_GetEventExtendedDataRecordEx: start-on-event=GetEventExtendedDataRecordEx, operation=EventInfo_ETH_E_UNDERSIZRFRAME.GetEventExtendedDataRecordEx
        OIE_EventInfo_ETH_E_UNDERSIZRFRAME_GetEventFreezeFrameDataEx: start-on-event=GetEventFreezeFrameDataEx, operation=EventInfo_ETH_E_UNDERSIZRFRAME.GetEventFreezeFrameDataEx
        OIE_EventInfo_ETH_E_UNDERSIZRFRAME_GetEventUdsStatus: start-on-event=GetEventUdsStatus, operation=EventInfo_ETH_E_UNDERSIZRFRAME.GetEventUdsStatus
        OIE_EventInfo_ETH_E_UNDERSIZRFRAME_GetFaultDetectionCounter: start-on-event=GetFaultDetectionCounter, operation=EventInfo_ETH_E_UNDERSIZRFRAME.GetFaultDetectionCounter
        OIE_EventInfo_ETH_E_UNDERSIZRFRAME_GetMonitorStatus: start-on-event=GetMonitorStatus, operation=EventInfo_ETH_E_UNDERSIZRFRAME.GetMonitorStatus
        OIE_EventInfo_FEE_E_GC_ERASE_GetDTCOfEvent: start-on-event=GetDTCOfEvent, operation=EventInfo_FEE_E_GC_ERASE.GetDTCOfEvent
        OIE_EventInfo_FEE_E_GC_ERASE_GetDebouncingOfEvent: start-on-event=GetDebouncingOfEvent, operation=EventInfo_FEE_E_GC_ERASE.GetDebouncingOfEvent
        OIE_EventInfo_FEE_E_GC_ERASE_GetEventExtendedDataRecordEx: start-on-event=GetEventExtendedDataRecordEx, operation=EventInfo_FEE_E_GC_ERASE.GetEventExtendedDataRecordEx
        OIE_EventInfo_FEE_E_GC_ERASE_GetEventFreezeFrameDataEx: start-on-event=GetEventFreezeFrameDataEx, operation=EventInfo_FEE_E_GC_ERASE.GetEventFreezeFrameDataEx
        OIE_EventInfo_FEE_E_GC_ERASE_GetEventUdsStatus: start-on-event=GetEventUdsStatus, operation=EventInfo_FEE_E_GC_ERASE.GetEventUdsStatus
        OIE_EventInfo_FEE_E_GC_ERASE_GetFaultDetectionCounter: start-on-event=GetFaultDetectionCounter, operation=EventInfo_FEE_E_GC_ERASE.GetFaultDetectionCounter
        OIE_EventInfo_FEE_E_GC_ERASE_GetMonitorStatus: start-on-event=GetMonitorStatus, operation=EventInfo_FEE_E_GC_ERASE.GetMonitorStatus
        OIE_EventInfo_FEE_E_GC_INIT_GetDTCOfEvent: start-on-event=GetDTCOfEvent, operation=EventInfo_FEE_E_GC_INIT.GetDTCOfEvent
        OIE_EventInfo_FEE_E_GC_INIT_GetDebouncingOfEvent: start-on-event=GetDebouncingOfEvent, operation=EventInfo_FEE_E_GC_INIT.GetDebouncingOfEvent
        OIE_EventInfo_FEE_E_GC_INIT_GetEventExtendedDataRecordEx: start-on-event=GetEventExtendedDataRecordEx, operation=EventInfo_FEE_E_GC_INIT.GetEventExtendedDataRecordEx
        OIE_EventInfo_FEE_E_GC_INIT_GetEventFreezeFrameDataEx: start-on-event=GetEventFreezeFrameDataEx, operation=EventInfo_FEE_E_GC_INIT.GetEventFreezeFrameDataEx
        OIE_EventInfo_FEE_E_GC_INIT_GetEventUdsStatus: start-on-event=GetEventUdsStatus, operation=EventInfo_FEE_E_GC_INIT.GetEventUdsStatus
        OIE_EventInfo_FEE_E_GC_INIT_GetFaultDetectionCounter: start-on-event=GetFaultDetectionCounter, operation=EventInfo_FEE_E_GC_INIT.GetFaultDetectionCounter
        OIE_EventInfo_FEE_E_GC_INIT_GetMonitorStatus: start-on-event=GetMonitorStatus, operation=EventInfo_FEE_E_GC_INIT.GetMonitorStatus
        OIE_EventInfo_FEE_E_GC_READ_GetDTCOfEvent: start-on-event=GetDTCOfEvent, operation=EventInfo_FEE_E_GC_READ.GetDTCOfEvent
        OIE_EventInfo_FEE_E_GC_READ_GetDebouncingOfEvent: start-on-event=GetDebouncingOfEvent, operation=EventInfo_FEE_E_GC_READ.GetDebouncingOfEvent
        OIE_EventInfo_FEE_E_GC_READ_GetEventExtendedDataRecordEx: start-on-event=GetEventExtendedDataRecordEx, operation=EventInfo_FEE_E_GC_READ.GetEventExtendedDataRecordEx
        OIE_EventInfo_FEE_E_GC_READ_GetEventFreezeFrameDataEx: start-on-event=GetEventFreezeFrameDataEx, operation=EventInfo_FEE_E_GC_READ.GetEventFreezeFrameDataEx
        OIE_EventInfo_FEE_E_GC_READ_GetEventUdsStatus: start-on-event=GetEventUdsStatus, operation=EventInfo_FEE_E_GC_READ.GetEventUdsStatus
        OIE_EventInfo_FEE_E_GC_READ_GetFaultDetectionCounter: start-on-event=GetFaultDetectionCounter, operation=EventInfo_FEE_E_GC_READ.GetFaultDetectionCounter
        OIE_EventInfo_FEE_E_GC_READ_GetMonitorStatus: start-on-event=GetMonitorStatus, operation=EventInfo_FEE_E_GC_READ.GetMonitorStatus
        OIE_EventInfo_FEE_E_GC_TRIG_GetDTCOfEvent: start-on-event=GetDTCOfEvent, operation=EventInfo_FEE_E_GC_TRIG.GetDTCOfEvent
        OIE_EventInfo_FEE_E_GC_TRIG_GetDebouncingOfEvent: start-on-event=GetDebouncingOfEvent, operation=EventInfo_FEE_E_GC_TRIG.GetDebouncingOfEvent
        OIE_EventInfo_FEE_E_GC_TRIG_GetEventExtendedDataRecordEx: start-on-event=GetEventExtendedDataRecordEx, operation=EventInfo_FEE_E_GC_TRIG.GetEventExtendedDataRecordEx
        OIE_EventInfo_FEE_E_GC_TRIG_GetEventFreezeFrameDataEx: start-on-event=GetEventFreezeFrameDataEx, operation=EventInfo_FEE_E_GC_TRIG.GetEventFreezeFrameDataEx
        OIE_EventInfo_FEE_E_GC_TRIG_GetEventUdsStatus: start-on-event=GetEventUdsStatus, operation=EventInfo_FEE_E_GC_TRIG.GetEventUdsStatus
        OIE_EventInfo_FEE_E_GC_TRIG_GetFaultDetectionCounter: start-on-event=GetFaultDetectionCounter, operation=EventInfo_FEE_E_GC_TRIG.GetFaultDetectionCounter
        OIE_EventInfo_FEE_E_GC_TRIG_GetMonitorStatus: start-on-event=GetMonitorStatus, operation=EventInfo_FEE_E_GC_TRIG.GetMonitorStatus
        OIE_EventInfo_FEE_E_GC_WRITE_GetDTCOfEvent: start-on-event=GetDTCOfEvent, operation=EventInfo_FEE_E_GC_WRITE.GetDTCOfEvent
        OIE_EventInfo_FEE_E_GC_WRITE_GetDebouncingOfEvent: start-on-event=GetDebouncingOfEvent, operation=EventInfo_FEE_E_GC_WRITE.GetDebouncingOfEvent
        OIE_EventInfo_FEE_E_GC_WRITE_GetEventExtendedDataRecordEx: start-on-event=GetEventExtendedDataRecordEx, operation=EventInfo_FEE_E_GC_WRITE.GetEventExtendedDataRecordEx
        OIE_EventInfo_FEE_E_GC_WRITE_GetEventFreezeFrameDataEx: start-on-event=GetEventFreezeFrameDataEx, operation=EventInfo_FEE_E_GC_WRITE.GetEventFreezeFrameDataEx
        OIE_EventInfo_FEE_E_GC_WRITE_GetEventUdsStatus: start-on-event=GetEventUdsStatus, operation=EventInfo_FEE_E_GC_WRITE.GetEventUdsStatus
        OIE_EventInfo_FEE_E_GC_WRITE_GetFaultDetectionCounter: start-on-event=GetFaultDetectionCounter, operation=EventInfo_FEE_E_GC_WRITE.GetFaultDetectionCounter
        OIE_EventInfo_FEE_E_GC_WRITE_GetMonitorStatus: start-on-event=GetMonitorStatus, operation=EventInfo_FEE_E_GC_WRITE.GetMonitorStatus
        OIE_EventInfo_FEE_E_INVALIDATE_GetDTCOfEvent: start-on-event=GetDTCOfEvent, operation=EventInfo_FEE_E_INVALIDATE.GetDTCOfEvent
        OIE_EventInfo_FEE_E_INVALIDATE_GetDebouncingOfEvent: start-on-event=GetDebouncingOfEvent, operation=EventInfo_FEE_E_INVALIDATE.GetDebouncingOfEvent
        OIE_EventInfo_FEE_E_INVALIDATE_GetEventExtendedDataRecordEx: start-on-event=GetEventExtendedDataRecordEx, operation=EventInfo_FEE_E_INVALIDATE.GetEventExtendedDataRecordEx
        OIE_EventInfo_FEE_E_INVALIDATE_GetEventFreezeFrameDataEx: start-on-event=GetEventFreezeFrameDataEx, operation=EventInfo_FEE_E_INVALIDATE.GetEventFreezeFrameDataEx
        OIE_EventInfo_FEE_E_INVALIDATE_GetEventUdsStatus: start-on-event=GetEventUdsStatus, operation=EventInfo_FEE_E_INVALIDATE.GetEventUdsStatus
        OIE_EventInfo_FEE_E_INVALIDATE_GetFaultDetectionCounter: start-on-event=GetFaultDetectionCounter, operation=EventInfo_FEE_E_INVALIDATE.GetFaultDetectionCounter
        OIE_EventInfo_FEE_E_INVALIDATE_GetMonitorStatus: start-on-event=GetMonitorStatus, operation=EventInfo_FEE_E_INVALIDATE.GetMonitorStatus
        OIE_EventInfo_FEE_E_READ_GetDTCOfEvent: start-on-event=GetDTCOfEvent, operation=EventInfo_FEE_E_READ.GetDTCOfEvent
        OIE_EventInfo_FEE_E_READ_GetDebouncingOfEvent: start-on-event=GetDebouncingOfEvent, operation=EventInfo_FEE_E_READ.GetDebouncingOfEvent
        OIE_EventInfo_FEE_E_READ_GetEventExtendedDataRecordEx: start-on-event=GetEventExtendedDataRecordEx, operation=EventInfo_FEE_E_READ.GetEventExtendedDataRecordEx
        OIE_EventInfo_FEE_E_READ_GetEventFreezeFrameDataEx: start-on-event=GetEventFreezeFrameDataEx, operation=EventInfo_FEE_E_READ.GetEventFreezeFrameDataEx
        OIE_EventInfo_FEE_E_READ_GetEventUdsStatus: start-on-event=GetEventUdsStatus, operation=EventInfo_FEE_E_READ.GetEventUdsStatus
        OIE_EventInfo_FEE_E_READ_GetFaultDetectionCounter: start-on-event=GetFaultDetectionCounter, operation=EventInfo_FEE_E_READ.GetFaultDetectionCounter
        OIE_EventInfo_FEE_E_READ_GetMonitorStatus: start-on-event=GetMonitorStatus, operation=EventInfo_FEE_E_READ.GetMonitorStatus
        OIE_EventInfo_FEE_E_UNCONFIG_BLK_EXCEEDED_GetDTCOfEvent: start-on-event=GetDTCOfEvent, operation=EventInfo_FEE_E_UNCONFIG_BLK_EXCEEDED.GetDTCOfEvent
        OIE_EventInfo_FEE_E_UNCONFIG_BLK_EXCEEDED_GetDebouncingOfEvent: start-on-event=GetDebouncingOfEvent, operation=EventInfo_FEE_E_UNCONFIG_BLK_EXCEEDED.GetDebouncingOfEvent
        OIE_EventInfo_FEE_E_UNCONFIG_BLK_EXCEEDED_GetEventExtendedDataRecordEx: start-on-event=GetEventExtendedDataRecordEx, operation=EventInfo_FEE_E_UNCONFIG_BLK_EXCEEDED.GetEventExtendedDataRecordEx
        OIE_EventInfo_FEE_E_UNCONFIG_BLK_EXCEEDED_GetEventFreezeFrameDataEx: start-on-event=GetEventFreezeFrameDataEx, operation=EventInfo_FEE_E_UNCONFIG_BLK_EXCEEDED.GetEventFreezeFrameDataEx
        OIE_EventInfo_FEE_E_UNCONFIG_BLK_EXCEEDED_GetEventUdsStatus: start-on-event=GetEventUdsStatus, operation=EventInfo_FEE_E_UNCONFIG_BLK_EXCEEDED.GetEventUdsStatus
        OIE_EventInfo_FEE_E_UNCONFIG_BLK_EXCEEDED_GetFaultDetectionCounter: start-on-event=GetFaultDetectionCounter, operation=EventInfo_FEE_E_UNCONFIG_BLK_EXCEEDED.GetFaultDetectionCounter
        OIE_EventInfo_FEE_E_UNCONFIG_BLK_EXCEEDED_GetMonitorStatus: start-on-event=GetMonitorStatus, operation=EventInfo_FEE_E_UNCONFIG_BLK_EXCEEDED.GetMonitorStatus
        OIE_EventInfo_FEE_E_WRITE_CYCLES_EXHAUSTED_GetDTCOfEvent: start-on-event=GetDTCOfEvent, operation=EventInfo_FEE_E_WRITE_CYCLES_EXHAUSTED.GetDTCOfEvent
        OIE_EventInfo_FEE_E_WRITE_CYCLES_EXHAUSTED_GetDebouncingOfEvent: start-on-event=GetDebouncingOfEvent, operation=EventInfo_FEE_E_WRITE_CYCLES_EXHAUSTED.GetDebouncingOfEvent
        OIE_EventInfo_FEE_E_WRITE_CYCLES_EXHAUSTED_GetEventExtendedDataRecordEx: start-on-event=GetEventExtendedDataRecordEx, operation=EventInfo_FEE_E_WRITE_CYCLES_EXHAUSTED.GetEventExtendedDataRecordEx
        OIE_EventInfo_FEE_E_WRITE_CYCLES_EXHAUSTED_GetEventFreezeFrameDataEx: start-on-event=GetEventFreezeFrameDataEx, operation=EventInfo_FEE_E_WRITE_CYCLES_EXHAUSTED.GetEventFreezeFrameDataEx
        OIE_EventInfo_FEE_E_WRITE_CYCLES_EXHAUSTED_GetEventUdsStatus: start-on-event=GetEventUdsStatus, operation=EventInfo_FEE_E_WRITE_CYCLES_EXHAUSTED.GetEventUdsStatus
        OIE_EventInfo_FEE_E_WRITE_CYCLES_EXHAUSTED_GetFaultDetectionCounter: start-on-event=GetFaultDetectionCounter, operation=EventInfo_FEE_E_WRITE_CYCLES_EXHAUSTED.GetFaultDetectionCounter
        OIE_EventInfo_FEE_E_WRITE_CYCLES_EXHAUSTED_GetMonitorStatus: start-on-event=GetMonitorStatus, operation=EventInfo_FEE_E_WRITE_CYCLES_EXHAUSTED.GetMonitorStatus
        OIE_EventInfo_FEE_E_WRITE_GetDTCOfEvent: start-on-event=GetDTCOfEvent, operation=EventInfo_FEE_E_WRITE.GetDTCOfEvent
        OIE_EventInfo_FEE_E_WRITE_GetDebouncingOfEvent: start-on-event=GetDebouncingOfEvent, operation=EventInfo_FEE_E_WRITE.GetDebouncingOfEvent
        OIE_EventInfo_FEE_E_WRITE_GetEventExtendedDataRecordEx: start-on-event=GetEventExtendedDataRecordEx, operation=EventInfo_FEE_E_WRITE.GetEventExtendedDataRecordEx
        OIE_EventInfo_FEE_E_WRITE_GetEventFreezeFrameDataEx: start-on-event=GetEventFreezeFrameDataEx, operation=EventInfo_FEE_E_WRITE.GetEventFreezeFrameDataEx
        OIE_EventInfo_FEE_E_WRITE_GetEventUdsStatus: start-on-event=GetEventUdsStatus, operation=EventInfo_FEE_E_WRITE.GetEventUdsStatus
        OIE_EventInfo_FEE_E_WRITE_GetFaultDetectionCounter: start-on-event=GetFaultDetectionCounter, operation=EventInfo_FEE_E_WRITE.GetFaultDetectionCounter
        OIE_EventInfo_FEE_E_WRITE_GetMonitorStatus: start-on-event=GetMonitorStatus, operation=EventInfo_FEE_E_WRITE.GetMonitorStatus
        OIE_EventInfo_FLS_E_COMPARE_FAILED_GetDTCOfEvent: start-on-event=GetDTCOfEvent, operation=EventInfo_FLS_E_COMPARE_FAILED.GetDTCOfEvent
        OIE_EventInfo_FLS_E_COMPARE_FAILED_GetDebouncingOfEvent: start-on-event=GetDebouncingOfEvent, operation=EventInfo_FLS_E_COMPARE_FAILED.GetDebouncingOfEvent
        OIE_EventInfo_FLS_E_COMPARE_FAILED_GetEventExtendedDataRecordEx: start-on-event=GetEventExtendedDataRecordEx, operation=EventInfo_FLS_E_COMPARE_FAILED.GetEventExtendedDataRecordEx
        OIE_EventInfo_FLS_E_COMPARE_FAILED_GetEventFreezeFrameDataEx: start-on-event=GetEventFreezeFrameDataEx, operation=EventInfo_FLS_E_COMPARE_FAILED.GetEventFreezeFrameDataEx
        OIE_EventInfo_FLS_E_COMPARE_FAILED_GetEventUdsStatus: start-on-event=GetEventUdsStatus, operation=EventInfo_FLS_E_COMPARE_FAILED.GetEventUdsStatus
        OIE_EventInfo_FLS_E_COMPARE_FAILED_GetFaultDetectionCounter: start-on-event=GetFaultDetectionCounter, operation=EventInfo_FLS_E_COMPARE_FAILED.GetFaultDetectionCounter
        OIE_EventInfo_FLS_E_COMPARE_FAILED_GetMonitorStatus: start-on-event=GetMonitorStatus, operation=EventInfo_FLS_E_COMPARE_FAILED.GetMonitorStatus
        OIE_EventInfo_FLS_E_ERASE_FAILED_GetDTCOfEvent: start-on-event=GetDTCOfEvent, operation=EventInfo_FLS_E_ERASE_FAILED.GetDTCOfEvent
        OIE_EventInfo_FLS_E_ERASE_FAILED_GetDebouncingOfEvent: start-on-event=GetDebouncingOfEvent, operation=EventInfo_FLS_E_ERASE_FAILED.GetDebouncingOfEvent
        OIE_EventInfo_FLS_E_ERASE_FAILED_GetEventExtendedDataRecordEx: start-on-event=GetEventExtendedDataRecordEx, operation=EventInfo_FLS_E_ERASE_FAILED.GetEventExtendedDataRecordEx
        OIE_EventInfo_FLS_E_ERASE_FAILED_GetEventFreezeFrameDataEx: start-on-event=GetEventFreezeFrameDataEx, operation=EventInfo_FLS_E_ERASE_FAILED.GetEventFreezeFrameDataEx
        OIE_EventInfo_FLS_E_ERASE_FAILED_GetEventUdsStatus: start-on-event=GetEventUdsStatus, operation=EventInfo_FLS_E_ERASE_FAILED.GetEventUdsStatus
        OIE_EventInfo_FLS_E_ERASE_FAILED_GetFaultDetectionCounter: start-on-event=GetFaultDetectionCounter, operation=EventInfo_FLS_E_ERASE_FAILED.GetFaultDetectionCounter
        OIE_EventInfo_FLS_E_ERASE_FAILED_GetMonitorStatus: start-on-event=GetMonitorStatus, operation=EventInfo_FLS_E_ERASE_FAILED.GetMonitorStatus
        OIE_EventInfo_FLS_E_READ_FAILED_GetDTCOfEvent: start-on-event=GetDTCOfEvent, operation=EventInfo_FLS_E_READ_FAILED.GetDTCOfEvent
        OIE_EventInfo_FLS_E_READ_FAILED_GetDebouncingOfEvent: start-on-event=GetDebouncingOfEvent, operation=EventInfo_FLS_E_READ_FAILED.GetDebouncingOfEvent
        OIE_EventInfo_FLS_E_READ_FAILED_GetEventExtendedDataRecordEx: start-on-event=GetEventExtendedDataRecordEx, operation=EventInfo_FLS_E_READ_FAILED.GetEventExtendedDataRecordEx
        OIE_EventInfo_FLS_E_READ_FAILED_GetEventFreezeFrameDataEx: start-on-event=GetEventFreezeFrameDataEx, operation=EventInfo_FLS_E_READ_FAILED.GetEventFreezeFrameDataEx
        OIE_EventInfo_FLS_E_READ_FAILED_GetEventUdsStatus: start-on-event=GetEventUdsStatus, operation=EventInfo_FLS_E_READ_FAILED.GetEventUdsStatus
        OIE_EventInfo_FLS_E_READ_FAILED_GetFaultDetectionCounter: start-on-event=GetFaultDetectionCounter, operation=EventInfo_FLS_E_READ_FAILED.GetFaultDetectionCounter
        OIE_EventInfo_FLS_E_READ_FAILED_GetMonitorStatus: start-on-event=GetMonitorStatus, operation=EventInfo_FLS_E_READ_FAILED.GetMonitorStatus
        OIE_EventInfo_FLS_E_UNEXPECTED_FLASH_ID_GetDTCOfEvent: start-on-event=GetDTCOfEvent, operation=EventInfo_FLS_E_UNEXPECTED_FLASH_ID.GetDTCOfEvent
        OIE_EventInfo_FLS_E_UNEXPECTED_FLASH_ID_GetDebouncingOfEvent: start-on-event=GetDebouncingOfEvent, operation=EventInfo_FLS_E_UNEXPECTED_FLASH_ID.GetDebouncingOfEvent
        OIE_EventInfo_FLS_E_UNEXPECTED_FLASH_ID_GetEventExtendedDataRecordEx: start-on-event=GetEventExtendedDataRecordEx, operation=EventInfo_FLS_E_UNEXPECTED_FLASH_ID.GetEventExtendedDataRecordEx
        OIE_EventInfo_FLS_E_UNEXPECTED_FLASH_ID_GetEventFreezeFrameDataEx: start-on-event=GetEventFreezeFrameDataEx, operation=EventInfo_FLS_E_UNEXPECTED_FLASH_ID.GetEventFreezeFrameDataEx
        OIE_EventInfo_FLS_E_UNEXPECTED_FLASH_ID_GetEventUdsStatus: start-on-event=GetEventUdsStatus, operation=EventInfo_FLS_E_UNEXPECTED_FLASH_ID.GetEventUdsStatus
        OIE_EventInfo_FLS_E_UNEXPECTED_FLASH_ID_GetFaultDetectionCounter: start-on-event=GetFaultDetectionCounter, operation=EventInfo_FLS_E_UNEXPECTED_FLASH_ID.GetFaultDetectionCounter
        OIE_EventInfo_FLS_E_UNEXPECTED_FLASH_ID_GetMonitorStatus: start-on-event=GetMonitorStatus, operation=EventInfo_FLS_E_UNEXPECTED_FLASH_ID.GetMonitorStatus
        OIE_EventInfo_FLS_E_WRITE_FAILED_GetDTCOfEvent: start-on-event=GetDTCOfEvent, operation=EventInfo_FLS_E_WRITE_FAILED.GetDTCOfEvent
        OIE_EventInfo_FLS_E_WRITE_FAILED_GetDebouncingOfEvent: start-on-event=GetDebouncingOfEvent, operation=EventInfo_FLS_E_WRITE_FAILED.GetDebouncingOfEvent
        OIE_EventInfo_FLS_E_WRITE_FAILED_GetEventExtendedDataRecordEx: start-on-event=GetEventExtendedDataRecordEx, operation=EventInfo_FLS_E_WRITE_FAILED.GetEventExtendedDataRecordEx
        OIE_EventInfo_FLS_E_WRITE_FAILED_GetEventFreezeFrameDataEx: start-on-event=GetEventFreezeFrameDataEx, operation=EventInfo_FLS_E_WRITE_FAILED.GetEventFreezeFrameDataEx
        OIE_EventInfo_FLS_E_WRITE_FAILED_GetEventUdsStatus: start-on-event=GetEventUdsStatus, operation=EventInfo_FLS_E_WRITE_FAILED.GetEventUdsStatus
        OIE_EventInfo_FLS_E_WRITE_FAILED_GetFaultDetectionCounter: start-on-event=GetFaultDetectionCounter, operation=EventInfo_FLS_E_WRITE_FAILED.GetFaultDetectionCounter
        OIE_EventInfo_FLS_E_WRITE_FAILED_GetMonitorStatus: start-on-event=GetMonitorStatus, operation=EventInfo_FLS_E_WRITE_FAILED.GetMonitorStatus
        OIE_EventInfo_IOHWAB_E_BUSY_GetDTCOfEvent: start-on-event=GetDTCOfEvent, operation=EventInfo_IOHWAB_E_BUSY.GetDTCOfEvent
        OIE_EventInfo_IOHWAB_E_BUSY_GetDebouncingOfEvent: start-on-event=GetDebouncingOfEvent, operation=EventInfo_IOHWAB_E_BUSY.GetDebouncingOfEvent
        OIE_EventInfo_IOHWAB_E_BUSY_GetEventExtendedDataRecordEx: start-on-event=GetEventExtendedDataRecordEx, operation=EventInfo_IOHWAB_E_BUSY.GetEventExtendedDataRecordEx
        OIE_EventInfo_IOHWAB_E_BUSY_GetEventFreezeFrameDataEx: start-on-event=GetEventFreezeFrameDataEx, operation=EventInfo_IOHWAB_E_BUSY.GetEventFreezeFrameDataEx
        OIE_EventInfo_IOHWAB_E_BUSY_GetEventUdsStatus: start-on-event=GetEventUdsStatus, operation=EventInfo_IOHWAB_E_BUSY.GetEventUdsStatus
        OIE_EventInfo_IOHWAB_E_BUSY_GetFaultDetectionCounter: start-on-event=GetFaultDetectionCounter, operation=EventInfo_IOHWAB_E_BUSY.GetFaultDetectionCounter
        OIE_EventInfo_IOHWAB_E_BUSY_GetMonitorStatus: start-on-event=GetMonitorStatus, operation=EventInfo_IOHWAB_E_BUSY.GetMonitorStatus
        OIE_EventInfo_IOHWAB_E_PROC_FAIL_GetDTCOfEvent: start-on-event=GetDTCOfEvent, operation=EventInfo_IOHWAB_E_PROC_FAIL.GetDTCOfEvent
        OIE_EventInfo_IOHWAB_E_PROC_FAIL_GetDebouncingOfEvent: start-on-event=GetDebouncingOfEvent, operation=EventInfo_IOHWAB_E_PROC_FAIL.GetDebouncingOfEvent
        OIE_EventInfo_IOHWAB_E_PROC_FAIL_GetEventExtendedDataRecordEx: start-on-event=GetEventExtendedDataRecordEx, operation=EventInfo_IOHWAB_E_PROC_FAIL.GetEventExtendedDataRecordEx
        OIE_EventInfo_IOHWAB_E_PROC_FAIL_GetEventFreezeFrameDataEx: start-on-event=GetEventFreezeFrameDataEx, operation=EventInfo_IOHWAB_E_PROC_FAIL.GetEventFreezeFrameDataEx
        OIE_EventInfo_IOHWAB_E_PROC_FAIL_GetEventUdsStatus: start-on-event=GetEventUdsStatus, operation=EventInfo_IOHWAB_E_PROC_FAIL.GetEventUdsStatus
        OIE_EventInfo_IOHWAB_E_PROC_FAIL_GetFaultDetectionCounter: start-on-event=GetFaultDetectionCounter, operation=EventInfo_IOHWAB_E_PROC_FAIL.GetFaultDetectionCounter
        OIE_EventInfo_IOHWAB_E_PROC_FAIL_GetMonitorStatus: start-on-event=GetMonitorStatus, operation=EventInfo_IOHWAB_E_PROC_FAIL.GetMonitorStatus
        OIE_EventInfo_IOHWAB_E_SETUP_FAIL_GetDTCOfEvent: start-on-event=GetDTCOfEvent, operation=EventInfo_IOHWAB_E_SETUP_FAIL.GetDTCOfEvent
        OIE_EventInfo_IOHWAB_E_SETUP_FAIL_GetDebouncingOfEvent: start-on-event=GetDebouncingOfEvent, operation=EventInfo_IOHWAB_E_SETUP_FAIL.GetDebouncingOfEvent
        OIE_EventInfo_IOHWAB_E_SETUP_FAIL_GetEventExtendedDataRecordEx: start-on-event=GetEventExtendedDataRecordEx, operation=EventInfo_IOHWAB_E_SETUP_FAIL.GetEventExtendedDataRecordEx
        OIE_EventInfo_IOHWAB_E_SETUP_FAIL_GetEventFreezeFrameDataEx: start-on-event=GetEventFreezeFrameDataEx, operation=EventInfo_IOHWAB_E_SETUP_FAIL.GetEventFreezeFrameDataEx
        OIE_EventInfo_IOHWAB_E_SETUP_FAIL_GetEventUdsStatus: start-on-event=GetEventUdsStatus, operation=EventInfo_IOHWAB_E_SETUP_FAIL.GetEventUdsStatus
        OIE_EventInfo_IOHWAB_E_SETUP_FAIL_GetFaultDetectionCounter: start-on-event=GetFaultDetectionCounter, operation=EventInfo_IOHWAB_E_SETUP_FAIL.GetFaultDetectionCounter
        OIE_EventInfo_IOHWAB_E_SETUP_FAIL_GetMonitorStatus: start-on-event=GetMonitorStatus, operation=EventInfo_IOHWAB_E_SETUP_FAIL.GetMonitorStatus
        OIE_EventInfo_IOHWAB_E_WRONG_PARAM_GetDTCOfEvent: start-on-event=GetDTCOfEvent, operation=EventInfo_IOHWAB_E_WRONG_PARAM.GetDTCOfEvent
        OIE_EventInfo_IOHWAB_E_WRONG_PARAM_GetDebouncingOfEvent: start-on-event=GetDebouncingOfEvent, operation=EventInfo_IOHWAB_E_WRONG_PARAM.GetDebouncingOfEvent
        OIE_EventInfo_IOHWAB_E_WRONG_PARAM_GetEventExtendedDataRecordEx: start-on-event=GetEventExtendedDataRecordEx, operation=EventInfo_IOHWAB_E_WRONG_PARAM.GetEventExtendedDataRecordEx
        OIE_EventInfo_IOHWAB_E_WRONG_PARAM_GetEventFreezeFrameDataEx: start-on-event=GetEventFreezeFrameDataEx, operation=EventInfo_IOHWAB_E_WRONG_PARAM.GetEventFreezeFrameDataEx
        OIE_EventInfo_IOHWAB_E_WRONG_PARAM_GetEventUdsStatus: start-on-event=GetEventUdsStatus, operation=EventInfo_IOHWAB_E_WRONG_PARAM.GetEventUdsStatus
        OIE_EventInfo_IOHWAB_E_WRONG_PARAM_GetFaultDetectionCounter: start-on-event=GetFaultDetectionCounter, operation=EventInfo_IOHWAB_E_WRONG_PARAM.GetFaultDetectionCounter
        OIE_EventInfo_IOHWAB_E_WRONG_PARAM_GetMonitorStatus: start-on-event=GetMonitorStatus, operation=EventInfo_IOHWAB_E_WRONG_PARAM.GetMonitorStatus
        OIE_EventInfo_IOHWAB_E_WRONG_SETTING_GetDTCOfEvent: start-on-event=GetDTCOfEvent, operation=EventInfo_IOHWAB_E_WRONG_SETTING.GetDTCOfEvent
        OIE_EventInfo_IOHWAB_E_WRONG_SETTING_GetDebouncingOfEvent: start-on-event=GetDebouncingOfEvent, operation=EventInfo_IOHWAB_E_WRONG_SETTING.GetDebouncingOfEvent
        OIE_EventInfo_IOHWAB_E_WRONG_SETTING_GetEventExtendedDataRecordEx: start-on-event=GetEventExtendedDataRecordEx, operation=EventInfo_IOHWAB_E_WRONG_SETTING.GetEventExtendedDataRecordEx
        OIE_EventInfo_IOHWAB_E_WRONG_SETTING_GetEventFreezeFrameDataEx: start-on-event=GetEventFreezeFrameDataEx, operation=EventInfo_IOHWAB_E_WRONG_SETTING.GetEventFreezeFrameDataEx
        OIE_EventInfo_IOHWAB_E_WRONG_SETTING_GetEventUdsStatus: start-on-event=GetEventUdsStatus, operation=EventInfo_IOHWAB_E_WRONG_SETTING.GetEventUdsStatus
        OIE_EventInfo_IOHWAB_E_WRONG_SETTING_GetFaultDetectionCounter: start-on-event=GetFaultDetectionCounter, operation=EventInfo_IOHWAB_E_WRONG_SETTING.GetFaultDetectionCounter
        OIE_EventInfo_IOHWAB_E_WRONG_SETTING_GetMonitorStatus: start-on-event=GetMonitorStatus, operation=EventInfo_IOHWAB_E_WRONG_SETTING.GetMonitorStatus
        OIE_EventInfo_IOHWAB_E_WRONG_STATE_GetDTCOfEvent: start-on-event=GetDTCOfEvent, operation=EventInfo_IOHWAB_E_WRONG_STATE.GetDTCOfEvent
        OIE_EventInfo_IOHWAB_E_WRONG_STATE_GetDebouncingOfEvent: start-on-event=GetDebouncingOfEvent, operation=EventInfo_IOHWAB_E_WRONG_STATE.GetDebouncingOfEvent
        OIE_EventInfo_IOHWAB_E_WRONG_STATE_GetEventExtendedDataRecordEx: start-on-event=GetEventExtendedDataRecordEx, operation=EventInfo_IOHWAB_E_WRONG_STATE.GetEventExtendedDataRecordEx
        OIE_EventInfo_IOHWAB_E_WRONG_STATE_GetEventFreezeFrameDataEx: start-on-event=GetEventFreezeFrameDataEx, operation=EventInfo_IOHWAB_E_WRONG_STATE.GetEventFreezeFrameDataEx
        OIE_EventInfo_IOHWAB_E_WRONG_STATE_GetEventUdsStatus: start-on-event=GetEventUdsStatus, operation=EventInfo_IOHWAB_E_WRONG_STATE.GetEventUdsStatus
        OIE_EventInfo_IOHWAB_E_WRONG_STATE_GetFaultDetectionCounter: start-on-event=GetFaultDetectionCounter, operation=EventInfo_IOHWAB_E_WRONG_STATE.GetFaultDetectionCounter
        OIE_EventInfo_IOHWAB_E_WRONG_STATE_GetMonitorStatus: start-on-event=GetMonitorStatus, operation=EventInfo_IOHWAB_E_WRONG_STATE.GetMonitorStatus
        OIE_EventInfo_MCU_E_CCU6_CLC_DISABLE_ERR_GetDTCOfEvent: start-on-event=GetDTCOfEvent, operation=EventInfo_MCU_E_CCU6_CLC_DISABLE_ERR.GetDTCOfEvent
        OIE_EventInfo_MCU_E_CCU6_CLC_DISABLE_ERR_GetDebouncingOfEvent: start-on-event=GetDebouncingOfEvent, operation=EventInfo_MCU_E_CCU6_CLC_DISABLE_ERR.GetDebouncingOfEvent
        OIE_EventInfo_MCU_E_CCU6_CLC_DISABLE_ERR_GetEventExtendedDataRecordEx: start-on-event=GetEventExtendedDataRecordEx, operation=EventInfo_MCU_E_CCU6_CLC_DISABLE_ERR.GetEventExtendedDataRecordEx
        OIE_EventInfo_MCU_E_CCU6_CLC_DISABLE_ERR_GetEventFreezeFrameDataEx: start-on-event=GetEventFreezeFrameDataEx, operation=EventInfo_MCU_E_CCU6_CLC_DISABLE_ERR.GetEventFreezeFrameDataEx
        OIE_EventInfo_MCU_E_CCU6_CLC_DISABLE_ERR_GetEventUdsStatus: start-on-event=GetEventUdsStatus, operation=EventInfo_MCU_E_CCU6_CLC_DISABLE_ERR.GetEventUdsStatus
        OIE_EventInfo_MCU_E_CCU6_CLC_DISABLE_ERR_GetFaultDetectionCounter: start-on-event=GetFaultDetectionCounter, operation=EventInfo_MCU_E_CCU6_CLC_DISABLE_ERR.GetFaultDetectionCounter
        OIE_EventInfo_MCU_E_CCU6_CLC_DISABLE_ERR_GetMonitorStatus: start-on-event=GetMonitorStatus, operation=EventInfo_MCU_E_CCU6_CLC_DISABLE_ERR.GetMonitorStatus
        OIE_EventInfo_MCU_E_CCU6_CLC_ENABLE_ERR_GetDTCOfEvent: start-on-event=GetDTCOfEvent, operation=EventInfo_MCU_E_CCU6_CLC_ENABLE_ERR.GetDTCOfEvent
        OIE_EventInfo_MCU_E_CCU6_CLC_ENABLE_ERR_GetDebouncingOfEvent: start-on-event=GetDebouncingOfEvent, operation=EventInfo_MCU_E_CCU6_CLC_ENABLE_ERR.GetDebouncingOfEvent
        OIE_EventInfo_MCU_E_CCU6_CLC_ENABLE_ERR_GetEventExtendedDataRecordEx: start-on-event=GetEventExtendedDataRecordEx, operation=EventInfo_MCU_E_CCU6_CLC_ENABLE_ERR.GetEventExtendedDataRecordEx
        OIE_EventInfo_MCU_E_CCU6_CLC_ENABLE_ERR_GetEventFreezeFrameDataEx: start-on-event=GetEventFreezeFrameDataEx, operation=EventInfo_MCU_E_CCU6_CLC_ENABLE_ERR.GetEventFreezeFrameDataEx
        OIE_EventInfo_MCU_E_CCU6_CLC_ENABLE_ERR_GetEventUdsStatus: start-on-event=GetEventUdsStatus, operation=EventInfo_MCU_E_CCU6_CLC_ENABLE_ERR.GetEventUdsStatus
        OIE_EventInfo_MCU_E_CCU6_CLC_ENABLE_ERR_GetFaultDetectionCounter: start-on-event=GetFaultDetectionCounter, operation=EventInfo_MCU_E_CCU6_CLC_ENABLE_ERR.GetFaultDetectionCounter
        OIE_EventInfo_MCU_E_CCU6_CLC_ENABLE_ERR_GetMonitorStatus: start-on-event=GetMonitorStatus, operation=EventInfo_MCU_E_CCU6_CLC_ENABLE_ERR.GetMonitorStatus
        OIE_EventInfo_MCU_E_CCUCON_UPDATE_ERR_GetDTCOfEvent: start-on-event=GetDTCOfEvent, operation=EventInfo_MCU_E_CCUCON_UPDATE_ERR.GetDTCOfEvent
        OIE_EventInfo_MCU_E_CCUCON_UPDATE_ERR_GetDebouncingOfEvent: start-on-event=GetDebouncingOfEvent, operation=EventInfo_MCU_E_CCUCON_UPDATE_ERR.GetDebouncingOfEvent
        OIE_EventInfo_MCU_E_CCUCON_UPDATE_ERR_GetEventExtendedDataRecordEx: start-on-event=GetEventExtendedDataRecordEx, operation=EventInfo_MCU_E_CCUCON_UPDATE_ERR.GetEventExtendedDataRecordEx
        OIE_EventInfo_MCU_E_CCUCON_UPDATE_ERR_GetEventFreezeFrameDataEx: start-on-event=GetEventFreezeFrameDataEx, operation=EventInfo_MCU_E_CCUCON_UPDATE_ERR.GetEventFreezeFrameDataEx
        OIE_EventInfo_MCU_E_CCUCON_UPDATE_ERR_GetEventUdsStatus: start-on-event=GetEventUdsStatus, operation=EventInfo_MCU_E_CCUCON_UPDATE_ERR.GetEventUdsStatus
        OIE_EventInfo_MCU_E_CCUCON_UPDATE_ERR_GetFaultDetectionCounter: start-on-event=GetFaultDetectionCounter, operation=EventInfo_MCU_E_CCUCON_UPDATE_ERR.GetFaultDetectionCounter
        OIE_EventInfo_MCU_E_CCUCON_UPDATE_ERR_GetMonitorStatus: start-on-event=GetMonitorStatus, operation=EventInfo_MCU_E_CCUCON_UPDATE_ERR.GetMonitorStatus
        OIE_EventInfo_MCU_E_CLOCK_FAILURE_GetDTCOfEvent: start-on-event=GetDTCOfEvent, operation=EventInfo_MCU_E_CLOCK_FAILURE.GetDTCOfEvent
        OIE_EventInfo_MCU_E_CLOCK_FAILURE_GetDebouncingOfEvent: start-on-event=GetDebouncingOfEvent, operation=EventInfo_MCU_E_CLOCK_FAILURE.GetDebouncingOfEvent
        OIE_EventInfo_MCU_E_CLOCK_FAILURE_GetEventExtendedDataRecordEx: start-on-event=GetEventExtendedDataRecordEx, operation=EventInfo_MCU_E_CLOCK_FAILURE.GetEventExtendedDataRecordEx
        OIE_EventInfo_MCU_E_CLOCK_FAILURE_GetEventFreezeFrameDataEx: start-on-event=GetEventFreezeFrameDataEx, operation=EventInfo_MCU_E_CLOCK_FAILURE.GetEventFreezeFrameDataEx
        OIE_EventInfo_MCU_E_CLOCK_FAILURE_GetEventUdsStatus: start-on-event=GetEventUdsStatus, operation=EventInfo_MCU_E_CLOCK_FAILURE.GetEventUdsStatus
        OIE_EventInfo_MCU_E_CLOCK_FAILURE_GetFaultDetectionCounter: start-on-event=GetFaultDetectionCounter, operation=EventInfo_MCU_E_CLOCK_FAILURE.GetFaultDetectionCounter
        OIE_EventInfo_MCU_E_CLOCK_FAILURE_GetMonitorStatus: start-on-event=GetMonitorStatus, operation=EventInfo_MCU_E_CLOCK_FAILURE.GetMonitorStatus
        OIE_EventInfo_MCU_E_CONVCTRL_CLC_DISABLE_ERR_GetDTCOfEvent: start-on-event=GetDTCOfEvent, operation=EventInfo_MCU_E_CONVCTRL_CLC_DISABLE_ERR.GetDTCOfEvent
        OIE_EventInfo_MCU_E_CONVCTRL_CLC_DISABLE_ERR_GetDebouncingOfEvent: start-on-event=GetDebouncingOfEvent, operation=EventInfo_MCU_E_CONVCTRL_CLC_DISABLE_ERR.GetDebouncingOfEvent
        OIE_EventInfo_MCU_E_CONVCTRL_CLC_DISABLE_ERR_GetEventExtendedDataRecordEx: start-on-event=GetEventExtendedDataRecordEx, operation=EventInfo_MCU_E_CONVCTRL_CLC_DISABLE_ERR.GetEventExtendedDataRecordEx
        OIE_EventInfo_MCU_E_CONVCTRL_CLC_DISABLE_ERR_GetEventFreezeFrameDataEx: start-on-event=GetEventFreezeFrameDataEx, operation=EventInfo_MCU_E_CONVCTRL_CLC_DISABLE_ERR.GetEventFreezeFrameDataEx
        OIE_EventInfo_MCU_E_CONVCTRL_CLC_DISABLE_ERR_GetEventUdsStatus: start-on-event=GetEventUdsStatus, operation=EventInfo_MCU_E_CONVCTRL_CLC_DISABLE_ERR.GetEventUdsStatus
        OIE_EventInfo_MCU_E_CONVCTRL_CLC_DISABLE_ERR_GetFaultDetectionCounter: start-on-event=GetFaultDetectionCounter, operation=EventInfo_MCU_E_CONVCTRL_CLC_DISABLE_ERR.GetFaultDetectionCounter
        OIE_EventInfo_MCU_E_CONVCTRL_CLC_DISABLE_ERR_GetMonitorStatus: start-on-event=GetMonitorStatus, operation=EventInfo_MCU_E_CONVCTRL_CLC_DISABLE_ERR.GetMonitorStatus
        OIE_EventInfo_MCU_E_CONVCTRL_CLC_ENABLE_ERR_GetDTCOfEvent: start-on-event=GetDTCOfEvent, operation=EventInfo_MCU_E_CONVCTRL_CLC_ENABLE_ERR.GetDTCOfEvent
        OIE_EventInfo_MCU_E_CONVCTRL_CLC_ENABLE_ERR_GetDebouncingOfEvent: start-on-event=GetDebouncingOfEvent, operation=EventInfo_MCU_E_CONVCTRL_CLC_ENABLE_ERR.GetDebouncingOfEvent
        OIE_EventInfo_MCU_E_CONVCTRL_CLC_ENABLE_ERR_GetEventExtendedDataRecordEx: start-on-event=GetEventExtendedDataRecordEx, operation=EventInfo_MCU_E_CONVCTRL_CLC_ENABLE_ERR.GetEventExtendedDataRecordEx
        OIE_EventInfo_MCU_E_CONVCTRL_CLC_ENABLE_ERR_GetEventFreezeFrameDataEx: start-on-event=GetEventFreezeFrameDataEx, operation=EventInfo_MCU_E_CONVCTRL_CLC_ENABLE_ERR.GetEventFreezeFrameDataEx
        OIE_EventInfo_MCU_E_CONVCTRL_CLC_ENABLE_ERR_GetEventUdsStatus: start-on-event=GetEventUdsStatus, operation=EventInfo_MCU_E_CONVCTRL_CLC_ENABLE_ERR.GetEventUdsStatus
        OIE_EventInfo_MCU_E_CONVCTRL_CLC_ENABLE_ERR_GetFaultDetectionCounter: start-on-event=GetFaultDetectionCounter, operation=EventInfo_MCU_E_CONVCTRL_CLC_ENABLE_ERR.GetFaultDetectionCounter
        OIE_EventInfo_MCU_E_CONVCTRL_CLC_ENABLE_ERR_GetMonitorStatus: start-on-event=GetMonitorStatus, operation=EventInfo_MCU_E_CONVCTRL_CLC_ENABLE_ERR.GetMonitorStatus
        OIE_EventInfo_MCU_E_GPT12_CLC_DISABLE_ERR_GetDTCOfEvent: start-on-event=GetDTCOfEvent, operation=EventInfo_MCU_E_GPT12_CLC_DISABLE_ERR.GetDTCOfEvent
        OIE_EventInfo_MCU_E_GPT12_CLC_DISABLE_ERR_GetDebouncingOfEvent: start-on-event=GetDebouncingOfEvent, operation=EventInfo_MCU_E_GPT12_CLC_DISABLE_ERR.GetDebouncingOfEvent
        OIE_EventInfo_MCU_E_GPT12_CLC_DISABLE_ERR_GetEventExtendedDataRecordEx: start-on-event=GetEventExtendedDataRecordEx, operation=EventInfo_MCU_E_GPT12_CLC_DISABLE_ERR.GetEventExtendedDataRecordEx
        OIE_EventInfo_MCU_E_GPT12_CLC_DISABLE_ERR_GetEventFreezeFrameDataEx: start-on-event=GetEventFreezeFrameDataEx, operation=EventInfo_MCU_E_GPT12_CLC_DISABLE_ERR.GetEventFreezeFrameDataEx
        OIE_EventInfo_MCU_E_GPT12_CLC_DISABLE_ERR_GetEventUdsStatus: start-on-event=GetEventUdsStatus, operation=EventInfo_MCU_E_GPT12_CLC_DISABLE_ERR.GetEventUdsStatus
        OIE_EventInfo_MCU_E_GPT12_CLC_DISABLE_ERR_GetFaultDetectionCounter: start-on-event=GetFaultDetectionCounter, operation=EventInfo_MCU_E_GPT12_CLC_DISABLE_ERR.GetFaultDetectionCounter
        OIE_EventInfo_MCU_E_GPT12_CLC_DISABLE_ERR_GetMonitorStatus: start-on-event=GetMonitorStatus, operation=EventInfo_MCU_E_GPT12_CLC_DISABLE_ERR.GetMonitorStatus
        OIE_EventInfo_MCU_E_GPT12_CLC_ENABLE_ERR_GetDTCOfEvent: start-on-event=GetDTCOfEvent, operation=EventInfo_MCU_E_GPT12_CLC_ENABLE_ERR.GetDTCOfEvent
        OIE_EventInfo_MCU_E_GPT12_CLC_ENABLE_ERR_GetDebouncingOfEvent: start-on-event=GetDebouncingOfEvent, operation=EventInfo_MCU_E_GPT12_CLC_ENABLE_ERR.GetDebouncingOfEvent
        OIE_EventInfo_MCU_E_GPT12_CLC_ENABLE_ERR_GetEventExtendedDataRecordEx: start-on-event=GetEventExtendedDataRecordEx, operation=EventInfo_MCU_E_GPT12_CLC_ENABLE_ERR.GetEventExtendedDataRecordEx
        OIE_EventInfo_MCU_E_GPT12_CLC_ENABLE_ERR_GetEventFreezeFrameDataEx: start-on-event=GetEventFreezeFrameDataEx, operation=EventInfo_MCU_E_GPT12_CLC_ENABLE_ERR.GetEventFreezeFrameDataEx
        OIE_EventInfo_MCU_E_GPT12_CLC_ENABLE_ERR_GetEventUdsStatus: start-on-event=GetEventUdsStatus, operation=EventInfo_MCU_E_GPT12_CLC_ENABLE_ERR.GetEventUdsStatus
        OIE_EventInfo_MCU_E_GPT12_CLC_ENABLE_ERR_GetFaultDetectionCounter: start-on-event=GetFaultDetectionCounter, operation=EventInfo_MCU_E_GPT12_CLC_ENABLE_ERR.GetFaultDetectionCounter
        OIE_EventInfo_MCU_E_GPT12_CLC_ENABLE_ERR_GetMonitorStatus: start-on-event=GetMonitorStatus, operation=EventInfo_MCU_E_GPT12_CLC_ENABLE_ERR.GetMonitorStatus
        OIE_EventInfo_MCU_E_GTM_CLC_DISABLE_ERR_GetDTCOfEvent: start-on-event=GetDTCOfEvent, operation=EventInfo_MCU_E_GTM_CLC_DISABLE_ERR.GetDTCOfEvent
        OIE_EventInfo_MCU_E_GTM_CLC_DISABLE_ERR_GetDebouncingOfEvent: start-on-event=GetDebouncingOfEvent, operation=EventInfo_MCU_E_GTM_CLC_DISABLE_ERR.GetDebouncingOfEvent
        OIE_EventInfo_MCU_E_GTM_CLC_DISABLE_ERR_GetEventExtendedDataRecordEx: start-on-event=GetEventExtendedDataRecordEx, operation=EventInfo_MCU_E_GTM_CLC_DISABLE_ERR.GetEventExtendedDataRecordEx
        OIE_EventInfo_MCU_E_GTM_CLC_DISABLE_ERR_GetEventFreezeFrameDataEx: start-on-event=GetEventFreezeFrameDataEx, operation=EventInfo_MCU_E_GTM_CLC_DISABLE_ERR.GetEventFreezeFrameDataEx
        OIE_EventInfo_MCU_E_GTM_CLC_DISABLE_ERR_GetEventUdsStatus: start-on-event=GetEventUdsStatus, operation=EventInfo_MCU_E_GTM_CLC_DISABLE_ERR.GetEventUdsStatus
        OIE_EventInfo_MCU_E_GTM_CLC_DISABLE_ERR_GetFaultDetectionCounter: start-on-event=GetFaultDetectionCounter, operation=EventInfo_MCU_E_GTM_CLC_DISABLE_ERR.GetFaultDetectionCounter
        OIE_EventInfo_MCU_E_GTM_CLC_DISABLE_ERR_GetMonitorStatus: start-on-event=GetMonitorStatus, operation=EventInfo_MCU_E_GTM_CLC_DISABLE_ERR.GetMonitorStatus
        OIE_EventInfo_MCU_E_GTM_CLC_ENABLE_ERR_GetDTCOfEvent: start-on-event=GetDTCOfEvent, operation=EventInfo_MCU_E_GTM_CLC_ENABLE_ERR.GetDTCOfEvent
        OIE_EventInfo_MCU_E_GTM_CLC_ENABLE_ERR_GetDebouncingOfEvent: start-on-event=GetDebouncingOfEvent, operation=EventInfo_MCU_E_GTM_CLC_ENABLE_ERR.GetDebouncingOfEvent
        OIE_EventInfo_MCU_E_GTM_CLC_ENABLE_ERR_GetEventExtendedDataRecordEx: start-on-event=GetEventExtendedDataRecordEx, operation=EventInfo_MCU_E_GTM_CLC_ENABLE_ERR.GetEventExtendedDataRecordEx
        OIE_EventInfo_MCU_E_GTM_CLC_ENABLE_ERR_GetEventFreezeFrameDataEx: start-on-event=GetEventFreezeFrameDataEx, operation=EventInfo_MCU_E_GTM_CLC_ENABLE_ERR.GetEventFreezeFrameDataEx
        OIE_EventInfo_MCU_E_GTM_CLC_ENABLE_ERR_GetEventUdsStatus: start-on-event=GetEventUdsStatus, operation=EventInfo_MCU_E_GTM_CLC_ENABLE_ERR.GetEventUdsStatus
        OIE_EventInfo_MCU_E_GTM_CLC_ENABLE_ERR_GetFaultDetectionCounter: start-on-event=GetFaultDetectionCounter, operation=EventInfo_MCU_E_GTM_CLC_ENABLE_ERR.GetFaultDetectionCounter
        OIE_EventInfo_MCU_E_GTM_CLC_ENABLE_ERR_GetMonitorStatus: start-on-event=GetMonitorStatus, operation=EventInfo_MCU_E_GTM_CLC_ENABLE_ERR.GetMonitorStatus
        OIE_EventInfo_MCU_E_OSC_FAILURE_GetDTCOfEvent: start-on-event=GetDTCOfEvent, operation=EventInfo_MCU_E_OSC_FAILURE.GetDTCOfEvent
        OIE_EventInfo_MCU_E_OSC_FAILURE_GetDebouncingOfEvent: start-on-event=GetDebouncingOfEvent, operation=EventInfo_MCU_E_OSC_FAILURE.GetDebouncingOfEvent
        OIE_EventInfo_MCU_E_OSC_FAILURE_GetEventExtendedDataRecordEx: start-on-event=GetEventExtendedDataRecordEx, operation=EventInfo_MCU_E_OSC_FAILURE.GetEventExtendedDataRecordEx
        OIE_EventInfo_MCU_E_OSC_FAILURE_GetEventFreezeFrameDataEx: start-on-event=GetEventFreezeFrameDataEx, operation=EventInfo_MCU_E_OSC_FAILURE.GetEventFreezeFrameDataEx
        OIE_EventInfo_MCU_E_OSC_FAILURE_GetEventUdsStatus: start-on-event=GetEventUdsStatus, operation=EventInfo_MCU_E_OSC_FAILURE.GetEventUdsStatus
        OIE_EventInfo_MCU_E_OSC_FAILURE_GetFaultDetectionCounter: start-on-event=GetFaultDetectionCounter, operation=EventInfo_MCU_E_OSC_FAILURE.GetFaultDetectionCounter
        OIE_EventInfo_MCU_E_OSC_FAILURE_GetMonitorStatus: start-on-event=GetMonitorStatus, operation=EventInfo_MCU_E_OSC_FAILURE.GetMonitorStatus
        OIE_EventInfo_MCU_E_PERIPHERAL_PLL_LOCK_LOSS_GetDTCOfEvent: start-on-event=GetDTCOfEvent, operation=EventInfo_MCU_E_PERIPHERAL_PLL_LOCK_LOSS.GetDTCOfEvent
        OIE_EventInfo_MCU_E_PERIPHERAL_PLL_LOCK_LOSS_GetDebouncingOfEvent: start-on-event=GetDebouncingOfEvent, operation=EventInfo_MCU_E_PERIPHERAL_PLL_LOCK_LOSS.GetDebouncingOfEvent
        OIE_EventInfo_MCU_E_PERIPHERAL_PLL_LOCK_LOSS_GetEventExtendedDataRecordEx: start-on-event=GetEventExtendedDataRecordEx, operation=EventInfo_MCU_E_PERIPHERAL_PLL_LOCK_LOSS.GetEventExtendedDataRecordEx
        OIE_EventInfo_MCU_E_PERIPHERAL_PLL_LOCK_LOSS_GetEventFreezeFrameDataEx: start-on-event=GetEventFreezeFrameDataEx, operation=EventInfo_MCU_E_PERIPHERAL_PLL_LOCK_LOSS.GetEventFreezeFrameDataEx
        OIE_EventInfo_MCU_E_PERIPHERAL_PLL_LOCK_LOSS_GetEventUdsStatus: start-on-event=GetEventUdsStatus, operation=EventInfo_MCU_E_PERIPHERAL_PLL_LOCK_LOSS.GetEventUdsStatus
        OIE_EventInfo_MCU_E_PERIPHERAL_PLL_LOCK_LOSS_GetFaultDetectionCounter: start-on-event=GetFaultDetectionCounter, operation=EventInfo_MCU_E_PERIPHERAL_PLL_LOCK_LOSS.GetFaultDetectionCounter
        OIE_EventInfo_MCU_E_PERIPHERAL_PLL_LOCK_LOSS_GetMonitorStatus: start-on-event=GetMonitorStatus, operation=EventInfo_MCU_E_PERIPHERAL_PLL_LOCK_LOSS.GetMonitorStatus
        OIE_EventInfo_MCU_E_PERIPHERAL_PLL_TIMEOUT_ERR_GetDTCOfEvent: start-on-event=GetDTCOfEvent, operation=EventInfo_MCU_E_PERIPHERAL_PLL_TIMEOUT_ERR.GetDTCOfEvent
        OIE_EventInfo_MCU_E_PERIPHERAL_PLL_TIMEOUT_ERR_GetDebouncingOfEvent: start-on-event=GetDebouncingOfEvent, operation=EventInfo_MCU_E_PERIPHERAL_PLL_TIMEOUT_ERR.GetDebouncingOfEvent
        OIE_EventInfo_MCU_E_PERIPHERAL_PLL_TIMEOUT_ERR_GetEventExtendedDataRecordEx: start-on-event=GetEventExtendedDataRecordEx, operation=EventInfo_MCU_E_PERIPHERAL_PLL_TIMEOUT_ERR.GetEventExtendedDataRecordEx
        OIE_EventInfo_MCU_E_PERIPHERAL_PLL_TIMEOUT_ERR_GetEventFreezeFrameDataEx: start-on-event=GetEventFreezeFrameDataEx, operation=EventInfo_MCU_E_PERIPHERAL_PLL_TIMEOUT_ERR.GetEventFreezeFrameDataEx
        OIE_EventInfo_MCU_E_PERIPHERAL_PLL_TIMEOUT_ERR_GetEventUdsStatus: start-on-event=GetEventUdsStatus, operation=EventInfo_MCU_E_PERIPHERAL_PLL_TIMEOUT_ERR.GetEventUdsStatus
        OIE_EventInfo_MCU_E_PERIPHERAL_PLL_TIMEOUT_ERR_GetFaultDetectionCounter: start-on-event=GetFaultDetectionCounter, operation=EventInfo_MCU_E_PERIPHERAL_PLL_TIMEOUT_ERR.GetFaultDetectionCounter
        OIE_EventInfo_MCU_E_PERIPHERAL_PLL_TIMEOUT_ERR_GetMonitorStatus: start-on-event=GetMonitorStatus, operation=EventInfo_MCU_E_PERIPHERAL_PLL_TIMEOUT_ERR.GetMonitorStatus
        OIE_EventInfo_MCU_E_PMSWCR_UPDATE_ERR_GetDTCOfEvent: start-on-event=GetDTCOfEvent, operation=EventInfo_MCU_E_PMSWCR_UPDATE_ERR.GetDTCOfEvent
        OIE_EventInfo_MCU_E_PMSWCR_UPDATE_ERR_GetDebouncingOfEvent: start-on-event=GetDebouncingOfEvent, operation=EventInfo_MCU_E_PMSWCR_UPDATE_ERR.GetDebouncingOfEvent
        OIE_EventInfo_MCU_E_PMSWCR_UPDATE_ERR_GetEventExtendedDataRecordEx: start-on-event=GetEventExtendedDataRecordEx, operation=EventInfo_MCU_E_PMSWCR_UPDATE_ERR.GetEventExtendedDataRecordEx
        OIE_EventInfo_MCU_E_PMSWCR_UPDATE_ERR_GetEventFreezeFrameDataEx: start-on-event=GetEventFreezeFrameDataEx, operation=EventInfo_MCU_E_PMSWCR_UPDATE_ERR.GetEventFreezeFrameDataEx
        OIE_EventInfo_MCU_E_PMSWCR_UPDATE_ERR_GetEventUdsStatus: start-on-event=GetEventUdsStatus, operation=EventInfo_MCU_E_PMSWCR_UPDATE_ERR.GetEventUdsStatus
        OIE_EventInfo_MCU_E_PMSWCR_UPDATE_ERR_GetFaultDetectionCounter: start-on-event=GetFaultDetectionCounter, operation=EventInfo_MCU_E_PMSWCR_UPDATE_ERR.GetFaultDetectionCounter
        OIE_EventInfo_MCU_E_PMSWCR_UPDATE_ERR_GetMonitorStatus: start-on-event=GetMonitorStatus, operation=EventInfo_MCU_E_PMSWCR_UPDATE_ERR.GetMonitorStatus
        OIE_EventInfo_MCU_E_SYSTEM_PLL_LOCK_LOSS_GetDTCOfEvent: start-on-event=GetDTCOfEvent, operation=EventInfo_MCU_E_SYSTEM_PLL_LOCK_LOSS.GetDTCOfEvent
        OIE_EventInfo_MCU_E_SYSTEM_PLL_LOCK_LOSS_GetDebouncingOfEvent: start-on-event=GetDebouncingOfEvent, operation=EventInfo_MCU_E_SYSTEM_PLL_LOCK_LOSS.GetDebouncingOfEvent
        OIE_EventInfo_MCU_E_SYSTEM_PLL_LOCK_LOSS_GetEventExtendedDataRecordEx: start-on-event=GetEventExtendedDataRecordEx, operation=EventInfo_MCU_E_SYSTEM_PLL_LOCK_LOSS.GetEventExtendedDataRecordEx
        OIE_EventInfo_MCU_E_SYSTEM_PLL_LOCK_LOSS_GetEventFreezeFrameDataEx: start-on-event=GetEventFreezeFrameDataEx, operation=EventInfo_MCU_E_SYSTEM_PLL_LOCK_LOSS.GetEventFreezeFrameDataEx
        OIE_EventInfo_MCU_E_SYSTEM_PLL_LOCK_LOSS_GetEventUdsStatus: start-on-event=GetEventUdsStatus, operation=EventInfo_MCU_E_SYSTEM_PLL_LOCK_LOSS.GetEventUdsStatus
        OIE_EventInfo_MCU_E_SYSTEM_PLL_LOCK_LOSS_GetFaultDetectionCounter: start-on-event=GetFaultDetectionCounter, operation=EventInfo_MCU_E_SYSTEM_PLL_LOCK_LOSS.GetFaultDetectionCounter
        OIE_EventInfo_MCU_E_SYSTEM_PLL_LOCK_LOSS_GetMonitorStatus: start-on-event=GetMonitorStatus, operation=EventInfo_MCU_E_SYSTEM_PLL_LOCK_LOSS.GetMonitorStatus
        OIE_EventInfo_MCU_E_SYSTEM_PLL_TIMEOUT_ERR_GetDTCOfEvent: start-on-event=GetDTCOfEvent, operation=EventInfo_MCU_E_SYSTEM_PLL_TIMEOUT_ERR.GetDTCOfEvent
        OIE_EventInfo_MCU_E_SYSTEM_PLL_TIMEOUT_ERR_GetDebouncingOfEvent: start-on-event=GetDebouncingOfEvent, operation=EventInfo_MCU_E_SYSTEM_PLL_TIMEOUT_ERR.GetDebouncingOfEvent
        OIE_EventInfo_MCU_E_SYSTEM_PLL_TIMEOUT_ERR_GetEventExtendedDataRecordEx: start-on-event=GetEventExtendedDataRecordEx, operation=EventInfo_MCU_E_SYSTEM_PLL_TIMEOUT_ERR.GetEventExtendedDataRecordEx
        OIE_EventInfo_MCU_E_SYSTEM_PLL_TIMEOUT_ERR_GetEventFreezeFrameDataEx: start-on-event=GetEventFreezeFrameDataEx, operation=EventInfo_MCU_E_SYSTEM_PLL_TIMEOUT_ERR.GetEventFreezeFrameDataEx
        OIE_EventInfo_MCU_E_SYSTEM_PLL_TIMEOUT_ERR_GetEventUdsStatus: start-on-event=GetEventUdsStatus, operation=EventInfo_MCU_E_SYSTEM_PLL_TIMEOUT_ERR.GetEventUdsStatus
        OIE_EventInfo_MCU_E_SYSTEM_PLL_TIMEOUT_ERR_GetFaultDetectionCounter: start-on-event=GetFaultDetectionCounter, operation=EventInfo_MCU_E_SYSTEM_PLL_TIMEOUT_ERR.GetFaultDetectionCounter
        OIE_EventInfo_MCU_E_SYSTEM_PLL_TIMEOUT_ERR_GetMonitorStatus: start-on-event=GetMonitorStatus, operation=EventInfo_MCU_E_SYSTEM_PLL_TIMEOUT_ERR.GetMonitorStatus
        OIE_EventInfo_NVM_E_INTEGRITY_FAILED_GetDTCOfEvent: start-on-event=GetDTCOfEvent, operation=EventInfo_NVM_E_INTEGRITY_FAILED.GetDTCOfEvent
        OIE_EventInfo_NVM_E_INTEGRITY_FAILED_GetDebouncingOfEvent: start-on-event=GetDebouncingOfEvent, operation=EventInfo_NVM_E_INTEGRITY_FAILED.GetDebouncingOfEvent
        OIE_EventInfo_NVM_E_INTEGRITY_FAILED_GetEventExtendedDataRecordEx: start-on-event=GetEventExtendedDataRecordEx, operation=EventInfo_NVM_E_INTEGRITY_FAILED.GetEventExtendedDataRecordEx
        OIE_EventInfo_NVM_E_INTEGRITY_FAILED_GetEventFreezeFrameDataEx: start-on-event=GetEventFreezeFrameDataEx, operation=EventInfo_NVM_E_INTEGRITY_FAILED.GetEventFreezeFrameDataEx
        OIE_EventInfo_NVM_E_INTEGRITY_FAILED_GetEventUdsStatus: start-on-event=GetEventUdsStatus, operation=EventInfo_NVM_E_INTEGRITY_FAILED.GetEventUdsStatus
        OIE_EventInfo_NVM_E_INTEGRITY_FAILED_GetFaultDetectionCounter: start-on-event=GetFaultDetectionCounter, operation=EventInfo_NVM_E_INTEGRITY_FAILED.GetFaultDetectionCounter
        OIE_EventInfo_NVM_E_INTEGRITY_FAILED_GetMonitorStatus: start-on-event=GetMonitorStatus, operation=EventInfo_NVM_E_INTEGRITY_FAILED.GetMonitorStatus
        OIE_EventInfo_NVM_E_LOSS_OF_REDUNDANCY_GetDTCOfEvent: start-on-event=GetDTCOfEvent, operation=EventInfo_NVM_E_LOSS_OF_REDUNDANCY.GetDTCOfEvent
        OIE_EventInfo_NVM_E_LOSS_OF_REDUNDANCY_GetDebouncingOfEvent: start-on-event=GetDebouncingOfEvent, operation=EventInfo_NVM_E_LOSS_OF_REDUNDANCY.GetDebouncingOfEvent
        OIE_EventInfo_NVM_E_LOSS_OF_REDUNDANCY_GetEventExtendedDataRecordEx: start-on-event=GetEventExtendedDataRecordEx, operation=EventInfo_NVM_E_LOSS_OF_REDUNDANCY.GetEventExtendedDataRecordEx
        OIE_EventInfo_NVM_E_LOSS_OF_REDUNDANCY_GetEventFreezeFrameDataEx: start-on-event=GetEventFreezeFrameDataEx, operation=EventInfo_NVM_E_LOSS_OF_REDUNDANCY.GetEventFreezeFrameDataEx
        OIE_EventInfo_NVM_E_LOSS_OF_REDUNDANCY_GetEventUdsStatus: start-on-event=GetEventUdsStatus, operation=EventInfo_NVM_E_LOSS_OF_REDUNDANCY.GetEventUdsStatus
        OIE_EventInfo_NVM_E_LOSS_OF_REDUNDANCY_GetFaultDetectionCounter: start-on-event=GetFaultDetectionCounter, operation=EventInfo_NVM_E_LOSS_OF_REDUNDANCY.GetFaultDetectionCounter
        OIE_EventInfo_NVM_E_LOSS_OF_REDUNDANCY_GetMonitorStatus: start-on-event=GetMonitorStatus, operation=EventInfo_NVM_E_LOSS_OF_REDUNDANCY.GetMonitorStatus
        OIE_EventInfo_NVM_E_QUEUE_OVERFLOW_GetDTCOfEvent: start-on-event=GetDTCOfEvent, operation=EventInfo_NVM_E_QUEUE_OVERFLOW.GetDTCOfEvent
        OIE_EventInfo_NVM_E_QUEUE_OVERFLOW_GetDebouncingOfEvent: start-on-event=GetDebouncingOfEvent, operation=EventInfo_NVM_E_QUEUE_OVERFLOW.GetDebouncingOfEvent
        OIE_EventInfo_NVM_E_QUEUE_OVERFLOW_GetEventExtendedDataRecordEx: start-on-event=GetEventExtendedDataRecordEx, operation=EventInfo_NVM_E_QUEUE_OVERFLOW.GetEventExtendedDataRecordEx
        OIE_EventInfo_NVM_E_QUEUE_OVERFLOW_GetEventFreezeFrameDataEx: start-on-event=GetEventFreezeFrameDataEx, operation=EventInfo_NVM_E_QUEUE_OVERFLOW.GetEventFreezeFrameDataEx
        OIE_EventInfo_NVM_E_QUEUE_OVERFLOW_GetEventUdsStatus: start-on-event=GetEventUdsStatus, operation=EventInfo_NVM_E_QUEUE_OVERFLOW.GetEventUdsStatus
        OIE_EventInfo_NVM_E_QUEUE_OVERFLOW_GetFaultDetectionCounter: start-on-event=GetFaultDetectionCounter, operation=EventInfo_NVM_E_QUEUE_OVERFLOW.GetFaultDetectionCounter
        OIE_EventInfo_NVM_E_QUEUE_OVERFLOW_GetMonitorStatus: start-on-event=GetMonitorStatus, operation=EventInfo_NVM_E_QUEUE_OVERFLOW.GetMonitorStatus
        OIE_EventInfo_NVM_E_REQ_FAILED_GetDTCOfEvent: start-on-event=GetDTCOfEvent, operation=EventInfo_NVM_E_REQ_FAILED.GetDTCOfEvent
        OIE_EventInfo_NVM_E_REQ_FAILED_GetDebouncingOfEvent: start-on-event=GetDebouncingOfEvent, operation=EventInfo_NVM_E_REQ_FAILED.GetDebouncingOfEvent
        OIE_EventInfo_NVM_E_REQ_FAILED_GetEventExtendedDataRecordEx: start-on-event=GetEventExtendedDataRecordEx, operation=EventInfo_NVM_E_REQ_FAILED.GetEventExtendedDataRecordEx
        OIE_EventInfo_NVM_E_REQ_FAILED_GetEventFreezeFrameDataEx: start-on-event=GetEventFreezeFrameDataEx, operation=EventInfo_NVM_E_REQ_FAILED.GetEventFreezeFrameDataEx
        OIE_EventInfo_NVM_E_REQ_FAILED_GetEventUdsStatus: start-on-event=GetEventUdsStatus, operation=EventInfo_NVM_E_REQ_FAILED.GetEventUdsStatus
        OIE_EventInfo_NVM_E_REQ_FAILED_GetFaultDetectionCounter: start-on-event=GetFaultDetectionCounter, operation=EventInfo_NVM_E_REQ_FAILED.GetFaultDetectionCounter
        OIE_EventInfo_NVM_E_REQ_FAILED_GetMonitorStatus: start-on-event=GetMonitorStatus, operation=EventInfo_NVM_E_REQ_FAILED.GetMonitorStatus
        OIE_EventInfo_NVM_E_VERIFY_FAILED_GetDTCOfEvent: start-on-event=GetDTCOfEvent, operation=EventInfo_NVM_E_VERIFY_FAILED.GetDTCOfEvent
        OIE_EventInfo_NVM_E_VERIFY_FAILED_GetDebouncingOfEvent: start-on-event=GetDebouncingOfEvent, operation=EventInfo_NVM_E_VERIFY_FAILED.GetDebouncingOfEvent
        OIE_EventInfo_NVM_E_VERIFY_FAILED_GetEventExtendedDataRecordEx: start-on-event=GetEventExtendedDataRecordEx, operation=EventInfo_NVM_E_VERIFY_FAILED.GetEventExtendedDataRecordEx
        OIE_EventInfo_NVM_E_VERIFY_FAILED_GetEventFreezeFrameDataEx: start-on-event=GetEventFreezeFrameDataEx, operation=EventInfo_NVM_E_VERIFY_FAILED.GetEventFreezeFrameDataEx
        OIE_EventInfo_NVM_E_VERIFY_FAILED_GetEventUdsStatus: start-on-event=GetEventUdsStatus, operation=EventInfo_NVM_E_VERIFY_FAILED.GetEventUdsStatus
        OIE_EventInfo_NVM_E_VERIFY_FAILED_GetFaultDetectionCounter: start-on-event=GetFaultDetectionCounter, operation=EventInfo_NVM_E_VERIFY_FAILED.GetFaultDetectionCounter
        OIE_EventInfo_NVM_E_VERIFY_FAILED_GetMonitorStatus: start-on-event=GetMonitorStatus, operation=EventInfo_NVM_E_VERIFY_FAILED.GetMonitorStatus
        OIE_EventInfo_NVM_E_WRITE_PROTECTED_GetDTCOfEvent: start-on-event=GetDTCOfEvent, operation=EventInfo_NVM_E_WRITE_PROTECTED.GetDTCOfEvent
        OIE_EventInfo_NVM_E_WRITE_PROTECTED_GetDebouncingOfEvent: start-on-event=GetDebouncingOfEvent, operation=EventInfo_NVM_E_WRITE_PROTECTED.GetDebouncingOfEvent
        OIE_EventInfo_NVM_E_WRITE_PROTECTED_GetEventExtendedDataRecordEx: start-on-event=GetEventExtendedDataRecordEx, operation=EventInfo_NVM_E_WRITE_PROTECTED.GetEventExtendedDataRecordEx
        OIE_EventInfo_NVM_E_WRITE_PROTECTED_GetEventFreezeFrameDataEx: start-on-event=GetEventFreezeFrameDataEx, operation=EventInfo_NVM_E_WRITE_PROTECTED.GetEventFreezeFrameDataEx
        OIE_EventInfo_NVM_E_WRITE_PROTECTED_GetEventUdsStatus: start-on-event=GetEventUdsStatus, operation=EventInfo_NVM_E_WRITE_PROTECTED.GetEventUdsStatus
        OIE_EventInfo_NVM_E_WRITE_PROTECTED_GetFaultDetectionCounter: start-on-event=GetFaultDetectionCounter, operation=EventInfo_NVM_E_WRITE_PROTECTED.GetFaultDetectionCounter
        OIE_EventInfo_NVM_E_WRITE_PROTECTED_GetMonitorStatus: start-on-event=GetMonitorStatus, operation=EventInfo_NVM_E_WRITE_PROTECTED.GetMonitorStatus
        OIE_EventInfo_NVM_E_WRONG_BLOCK_ID_GetDTCOfEvent: start-on-event=GetDTCOfEvent, operation=EventInfo_NVM_E_WRONG_BLOCK_ID.GetDTCOfEvent
        OIE_EventInfo_NVM_E_WRONG_BLOCK_ID_GetDebouncingOfEvent: start-on-event=GetDebouncingOfEvent, operation=EventInfo_NVM_E_WRONG_BLOCK_ID.GetDebouncingOfEvent
        OIE_EventInfo_NVM_E_WRONG_BLOCK_ID_GetEventExtendedDataRecordEx: start-on-event=GetEventExtendedDataRecordEx, operation=EventInfo_NVM_E_WRONG_BLOCK_ID.GetEventExtendedDataRecordEx
        OIE_EventInfo_NVM_E_WRONG_BLOCK_ID_GetEventFreezeFrameDataEx: start-on-event=GetEventFreezeFrameDataEx, operation=EventInfo_NVM_E_WRONG_BLOCK_ID.GetEventFreezeFrameDataEx
        OIE_EventInfo_NVM_E_WRONG_BLOCK_ID_GetEventUdsStatus: start-on-event=GetEventUdsStatus, operation=EventInfo_NVM_E_WRONG_BLOCK_ID.GetEventUdsStatus
        OIE_EventInfo_NVM_E_WRONG_BLOCK_ID_GetFaultDetectionCounter: start-on-event=GetFaultDetectionCounter, operation=EventInfo_NVM_E_WRONG_BLOCK_ID.GetFaultDetectionCounter
        OIE_EventInfo_NVM_E_WRONG_BLOCK_ID_GetMonitorStatus: start-on-event=GetMonitorStatus, operation=EventInfo_NVM_E_WRONG_BLOCK_ID.GetMonitorStatus
        OIE_EventInfo_SPI_E_HARDWARE_ERROR_GetDTCOfEvent: start-on-event=GetDTCOfEvent, operation=EventInfo_SPI_E_HARDWARE_ERROR.GetDTCOfEvent
        OIE_EventInfo_SPI_E_HARDWARE_ERROR_GetDebouncingOfEvent: start-on-event=GetDebouncingOfEvent, operation=EventInfo_SPI_E_HARDWARE_ERROR.GetDebouncingOfEvent
        OIE_EventInfo_SPI_E_HARDWARE_ERROR_GetEventExtendedDataRecordEx: start-on-event=GetEventExtendedDataRecordEx, operation=EventInfo_SPI_E_HARDWARE_ERROR.GetEventExtendedDataRecordEx
        OIE_EventInfo_SPI_E_HARDWARE_ERROR_GetEventFreezeFrameDataEx: start-on-event=GetEventFreezeFrameDataEx, operation=EventInfo_SPI_E_HARDWARE_ERROR.GetEventFreezeFrameDataEx
        OIE_EventInfo_SPI_E_HARDWARE_ERROR_GetEventUdsStatus: start-on-event=GetEventUdsStatus, operation=EventInfo_SPI_E_HARDWARE_ERROR.GetEventUdsStatus
        OIE_EventInfo_SPI_E_HARDWARE_ERROR_GetFaultDetectionCounter: start-on-event=GetFaultDetectionCounter, operation=EventInfo_SPI_E_HARDWARE_ERROR.GetFaultDetectionCounter
        OIE_EventInfo_SPI_E_HARDWARE_ERROR_GetMonitorStatus: start-on-event=GetMonitorStatus, operation=EventInfo_SPI_E_HARDWARE_ERROR.GetMonitorStatus
        OIE_EventInfo_WDGM_E_IMPROPER_CALLER_GetDTCOfEvent: start-on-event=GetDTCOfEvent, operation=EventInfo_WDGM_E_IMPROPER_CALLER.GetDTCOfEvent
        OIE_EventInfo_WDGM_E_IMPROPER_CALLER_GetDebouncingOfEvent: start-on-event=GetDebouncingOfEvent, operation=EventInfo_WDGM_E_IMPROPER_CALLER.GetDebouncingOfEvent
        OIE_EventInfo_WDGM_E_IMPROPER_CALLER_GetEventExtendedDataRecordEx: start-on-event=GetEventExtendedDataRecordEx, operation=EventInfo_WDGM_E_IMPROPER_CALLER.GetEventExtendedDataRecordEx
        OIE_EventInfo_WDGM_E_IMPROPER_CALLER_GetEventFreezeFrameDataEx: start-on-event=GetEventFreezeFrameDataEx, operation=EventInfo_WDGM_E_IMPROPER_CALLER.GetEventFreezeFrameDataEx
        OIE_EventInfo_WDGM_E_IMPROPER_CALLER_GetEventUdsStatus: start-on-event=GetEventUdsStatus, operation=EventInfo_WDGM_E_IMPROPER_CALLER.GetEventUdsStatus
        OIE_EventInfo_WDGM_E_IMPROPER_CALLER_GetFaultDetectionCounter: start-on-event=GetFaultDetectionCounter, operation=EventInfo_WDGM_E_IMPROPER_CALLER.GetFaultDetectionCounter
        OIE_EventInfo_WDGM_E_IMPROPER_CALLER_GetMonitorStatus: start-on-event=GetMonitorStatus, operation=EventInfo_WDGM_E_IMPROPER_CALLER.GetMonitorStatus
        OIE_EventInfo_WDGM_E_MONITORING_GetDTCOfEvent: start-on-event=GetDTCOfEvent, operation=EventInfo_WDGM_E_MONITORING.GetDTCOfEvent
        OIE_EventInfo_WDGM_E_MONITORING_GetDebouncingOfEvent: start-on-event=GetDebouncingOfEvent, operation=EventInfo_WDGM_E_MONITORING.GetDebouncingOfEvent
        OIE_EventInfo_WDGM_E_MONITORING_GetEventExtendedDataRecordEx: start-on-event=GetEventExtendedDataRecordEx, operation=EventInfo_WDGM_E_MONITORING.GetEventExtendedDataRecordEx
        OIE_EventInfo_WDGM_E_MONITORING_GetEventFreezeFrameDataEx: start-on-event=GetEventFreezeFrameDataEx, operation=EventInfo_WDGM_E_MONITORING.GetEventFreezeFrameDataEx
        OIE_EventInfo_WDGM_E_MONITORING_GetEventUdsStatus: start-on-event=GetEventUdsStatus, operation=EventInfo_WDGM_E_MONITORING.GetEventUdsStatus
        OIE_EventInfo_WDGM_E_MONITORING_GetFaultDetectionCounter: start-on-event=GetFaultDetectionCounter, operation=EventInfo_WDGM_E_MONITORING.GetFaultDetectionCounter
        OIE_EventInfo_WDGM_E_MONITORING_GetMonitorStatus: start-on-event=GetMonitorStatus, operation=EventInfo_WDGM_E_MONITORING.GetMonitorStatus
        OIE_EventInfo_WDGM_E_SET_MODE_GetDTCOfEvent: start-on-event=GetDTCOfEvent, operation=EventInfo_WDGM_E_SET_MODE.GetDTCOfEvent
        OIE_EventInfo_WDGM_E_SET_MODE_GetDebouncingOfEvent: start-on-event=GetDebouncingOfEvent, operation=EventInfo_WDGM_E_SET_MODE.GetDebouncingOfEvent
        OIE_EventInfo_WDGM_E_SET_MODE_GetEventExtendedDataRecordEx: start-on-event=GetEventExtendedDataRecordEx, operation=EventInfo_WDGM_E_SET_MODE.GetEventExtendedDataRecordEx
        OIE_EventInfo_WDGM_E_SET_MODE_GetEventFreezeFrameDataEx: start-on-event=GetEventFreezeFrameDataEx, operation=EventInfo_WDGM_E_SET_MODE.GetEventFreezeFrameDataEx
        OIE_EventInfo_WDGM_E_SET_MODE_GetEventUdsStatus: start-on-event=GetEventUdsStatus, operation=EventInfo_WDGM_E_SET_MODE.GetEventUdsStatus
        OIE_EventInfo_WDGM_E_SET_MODE_GetFaultDetectionCounter: start-on-event=GetFaultDetectionCounter, operation=EventInfo_WDGM_E_SET_MODE.GetFaultDetectionCounter
        OIE_EventInfo_WDGM_E_SET_MODE_GetMonitorStatus: start-on-event=GetMonitorStatus, operation=EventInfo_WDGM_E_SET_MODE.GetMonitorStatus
        OIE_EventInfo_WDG_76_ACW_E_DISABLE_REJECTED_GetDTCOfEvent: start-on-event=GetDTCOfEvent, operation=EventInfo_WDG_76_ACW_E_DISABLE_REJECTED.GetDTCOfEvent
        OIE_EventInfo_WDG_76_ACW_E_DISABLE_REJECTED_GetDebouncingOfEvent: start-on-event=GetDebouncingOfEvent, operation=EventInfo_WDG_76_ACW_E_DISABLE_REJECTED.GetDebouncingOfEvent
        OIE_EventInfo_WDG_76_ACW_E_DISABLE_REJECTED_GetEventExtendedDataRecordEx: start-on-event=GetEventExtendedDataRecordEx, operation=EventInfo_WDG_76_ACW_E_DISABLE_REJECTED.GetEventExtendedDataRecordEx
        OIE_EventInfo_WDG_76_ACW_E_DISABLE_REJECTED_GetEventFreezeFrameDataEx: start-on-event=GetEventFreezeFrameDataEx, operation=EventInfo_WDG_76_ACW_E_DISABLE_REJECTED.GetEventFreezeFrameDataEx
        OIE_EventInfo_WDG_76_ACW_E_DISABLE_REJECTED_GetEventUdsStatus: start-on-event=GetEventUdsStatus, operation=EventInfo_WDG_76_ACW_E_DISABLE_REJECTED.GetEventUdsStatus
        OIE_EventInfo_WDG_76_ACW_E_DISABLE_REJECTED_GetFaultDetectionCounter: start-on-event=GetFaultDetectionCounter, operation=EventInfo_WDG_76_ACW_E_DISABLE_REJECTED.GetFaultDetectionCounter
        OIE_EventInfo_WDG_76_ACW_E_DISABLE_REJECTED_GetMonitorStatus: start-on-event=GetMonitorStatus, operation=EventInfo_WDG_76_ACW_E_DISABLE_REJECTED.GetMonitorStatus
        OIE_EventInfo_WDG_76_ACW_E_MODE_FAILED_GetDTCOfEvent: start-on-event=GetDTCOfEvent, operation=EventInfo_WDG_76_ACW_E_MODE_FAILED.GetDTCOfEvent
        OIE_EventInfo_WDG_76_ACW_E_MODE_FAILED_GetDebouncingOfEvent: start-on-event=GetDebouncingOfEvent, operation=EventInfo_WDG_76_ACW_E_MODE_FAILED.GetDebouncingOfEvent
        OIE_EventInfo_WDG_76_ACW_E_MODE_FAILED_GetEventExtendedDataRecordEx: start-on-event=GetEventExtendedDataRecordEx, operation=EventInfo_WDG_76_ACW_E_MODE_FAILED.GetEventExtendedDataRecordEx
        OIE_EventInfo_WDG_76_ACW_E_MODE_FAILED_GetEventFreezeFrameDataEx: start-on-event=GetEventFreezeFrameDataEx, operation=EventInfo_WDG_76_ACW_E_MODE_FAILED.GetEventFreezeFrameDataEx
        OIE_EventInfo_WDG_76_ACW_E_MODE_FAILED_GetEventUdsStatus: start-on-event=GetEventUdsStatus, operation=EventInfo_WDG_76_ACW_E_MODE_FAILED.GetEventUdsStatus
        OIE_EventInfo_WDG_76_ACW_E_MODE_FAILED_GetFaultDetectionCounter: start-on-event=GetFaultDetectionCounter, operation=EventInfo_WDG_76_ACW_E_MODE_FAILED.GetFaultDetectionCounter
        OIE_EventInfo_WDG_76_ACW_E_MODE_FAILED_GetMonitorStatus: start-on-event=GetMonitorStatus, operation=EventInfo_WDG_76_ACW_E_MODE_FAILED.GetMonitorStatus
        OIE_EventInfo_WDG_E_DISABLE_REJECTED_GetDTCOfEvent: start-on-event=GetDTCOfEvent, operation=EventInfo_WDG_E_DISABLE_REJECTED.GetDTCOfEvent
        OIE_EventInfo_WDG_E_DISABLE_REJECTED_GetDebouncingOfEvent: start-on-event=GetDebouncingOfEvent, operation=EventInfo_WDG_E_DISABLE_REJECTED.GetDebouncingOfEvent
        OIE_EventInfo_WDG_E_DISABLE_REJECTED_GetEventExtendedDataRecordEx: start-on-event=GetEventExtendedDataRecordEx, operation=EventInfo_WDG_E_DISABLE_REJECTED.GetEventExtendedDataRecordEx
        OIE_EventInfo_WDG_E_DISABLE_REJECTED_GetEventFreezeFrameDataEx: start-on-event=GetEventFreezeFrameDataEx, operation=EventInfo_WDG_E_DISABLE_REJECTED.GetEventFreezeFrameDataEx
        OIE_EventInfo_WDG_E_DISABLE_REJECTED_GetEventUdsStatus: start-on-event=GetEventUdsStatus, operation=EventInfo_WDG_E_DISABLE_REJECTED.GetEventUdsStatus
        OIE_EventInfo_WDG_E_DISABLE_REJECTED_GetFaultDetectionCounter: start-on-event=GetFaultDetectionCounter, operation=EventInfo_WDG_E_DISABLE_REJECTED.GetFaultDetectionCounter
        OIE_EventInfo_WDG_E_DISABLE_REJECTED_GetMonitorStatus: start-on-event=GetMonitorStatus, operation=EventInfo_WDG_E_DISABLE_REJECTED.GetMonitorStatus
        OIE_EventInfo_WDG_E_MODE_FAILED_GetDTCOfEvent: start-on-event=GetDTCOfEvent, operation=EventInfo_WDG_E_MODE_FAILED.GetDTCOfEvent
        OIE_EventInfo_WDG_E_MODE_FAILED_GetDebouncingOfEvent: start-on-event=GetDebouncingOfEvent, operation=EventInfo_WDG_E_MODE_FAILED.GetDebouncingOfEvent
        OIE_EventInfo_WDG_E_MODE_FAILED_GetEventExtendedDataRecordEx: start-on-event=GetEventExtendedDataRecordEx, operation=EventInfo_WDG_E_MODE_FAILED.GetEventExtendedDataRecordEx
        OIE_EventInfo_WDG_E_MODE_FAILED_GetEventFreezeFrameDataEx: start-on-event=GetEventFreezeFrameDataEx, operation=EventInfo_WDG_E_MODE_FAILED.GetEventFreezeFrameDataEx
        OIE_EventInfo_WDG_E_MODE_FAILED_GetEventUdsStatus: start-on-event=GetEventUdsStatus, operation=EventInfo_WDG_E_MODE_FAILED.GetEventUdsStatus
        OIE_EventInfo_WDG_E_MODE_FAILED_GetFaultDetectionCounter: start-on-event=GetFaultDetectionCounter, operation=EventInfo_WDG_E_MODE_FAILED.GetFaultDetectionCounter
        OIE_EventInfo_WDG_E_MODE_FAILED_GetMonitorStatus: start-on-event=GetMonitorStatus, operation=EventInfo_WDG_E_MODE_FAILED.GetMonitorStatus
        OIE_EventStatus_CANCM_E_BAT_FAIL_SetWIRStatus: start-on-event=SetWIRStatus, operation=EventStatus_CANCM_E_BAT_FAIL.SetWIRStatus
        OIE_EventStatus_CANSM_E_BUS_OFF_FD_CAN1_SetWIRStatus: start-on-event=SetWIRStatus, operation=EventStatus_CANSM_E_BUS_OFF_FD_CAN1.SetWIRStatus
        OIE_EventStatus_CANSM_E_BUS_OFF_FD_CAN2_SetWIRStatus: start-on-event=SetWIRStatus, operation=EventStatus_CANSM_E_BUS_OFF_FD_CAN2.SetWIRStatus
        OIE_EventStatus_CANSM_E_BUS_OFF_HS_CAN1_SetWIRStatus: start-on-event=SetWIRStatus, operation=EventStatus_CANSM_E_BUS_OFF_HS_CAN1.SetWIRStatus
        OIE_EventStatus_CANSM_E_BUS_OFF_LS_CAN1_SetWIRStatus: start-on-event=SetWIRStatus, operation=EventStatus_CANSM_E_BUS_OFF_LS_CAN1.SetWIRStatus
        OIE_EventStatus_CANSM_E_BUS_OFF_Project_SetWIRStatus: start-on-event=SetWIRStatus, operation=EventStatus_CANSM_E_BUS_OFF_Project.SetWIRStatus
        OIE_EventStatus_CANSM_E_MODE_CHANGE_FD_CAN1_SetWIRStatus: start-on-event=SetWIRStatus, operation=EventStatus_CANSM_E_MODE_CHANGE_FD_CAN1.SetWIRStatus
        OIE_EventStatus_CANSM_E_MODE_CHANGE_FD_CAN2_SetWIRStatus: start-on-event=SetWIRStatus, operation=EventStatus_CANSM_E_MODE_CHANGE_FD_CAN2.SetWIRStatus
        OIE_EventStatus_CANSM_E_MODE_CHANGE_HS_CAN1_SetWIRStatus: start-on-event=SetWIRStatus, operation=EventStatus_CANSM_E_MODE_CHANGE_HS_CAN1.SetWIRStatus
        OIE_EventStatus_CANSM_E_MODE_CHANGE_LS_CAN1_SetWIRStatus: start-on-event=SetWIRStatus, operation=EventStatus_CANSM_E_MODE_CHANGE_LS_CAN1.SetWIRStatus
        OIE_EventStatus_CANSM_E_MODE_CHANGE_Project_SetWIRStatus: start-on-event=SetWIRStatus, operation=EventStatus_CANSM_E_MODE_CHANGE_Project.SetWIRStatus
        OIE_EventStatus_CANSM_E_MODE_REQUEST_TIMEOUT_FD_CAN1_SetWIRStatus: start-on-event=SetWIRStatus, operation=EventStatus_CANSM_E_MODE_REQUEST_TIMEOUT_FD_CAN1.SetWIRStatus
        OIE_EventStatus_CANSM_E_MODE_REQUEST_TIMEOUT_HS_CAN1_SetWIRStatus: start-on-event=SetWIRStatus, operation=EventStatus_CANSM_E_MODE_REQUEST_TIMEOUT_HS_CAN1.SetWIRStatus
        OIE_EventStatus_DEM_E_TEST_EVENT{10..19}_SetWIRStatus: start-on-event=SetWIRStatus, operation=EventStatus_DEM_E_TEST_EVENT{10..19}.SetWIRStatus
        OIE_EventStatus_DEM_E_TEST_EVENT1_SetWIRStatus: start-on-event=SetWIRStatus, operation=EventStatus_DEM_E_TEST_EVENT1.SetWIRStatus
        OIE_EventStatus_DEM_E_TEST_EVENT{20..22}_SetWIRStatus: start-on-event=SetWIRStatus, operation=EventStatus_DEM_E_TEST_EVENT{20..22}.SetWIRStatus
        OIE_EventStatus_DEM_E_TEST_EVENT{2..9}_SetWIRStatus: start-on-event=SetWIRStatus, operation=EventStatus_DEM_E_TEST_EVENT{2..9}.SetWIRStatus
        OIE_EventStatus_DEM_E_TEST_EVENT_E2EXF_MALFORMED_MESSAGE_SetWIRStatus: start-on-event=SetWIRStatus, operation=EventStatus_DEM_E_TEST_EVENT_E2EXF_MALFORMED_MESSAGE.SetWIRStatus
        OIE_EventStatus_DEM_E_TEST_EVENT_SOMEIPXF_MALFORMED_MESSAGE_SetWIRStatus: start-on-event=SetWIRStatus, operation=EventStatus_DEM_E_TEST_EVENT_SOMEIPXF_MALFORMED_MESSAGE.SetWIRStatus
        OIE_EventStatus_ECUM_E_CONFIGURATION_DATA_INCONSISTENT_SetWIRStatus: start-on-event=SetWIRStatus, operation=EventStatus_ECUM_E_CONFIGURATION_DATA_INCONSISTENT.SetWIRStatus
        OIE_EventStatus_ECUM_E_IMPROPER_CALLER_SetWIRStatus: start-on-event=SetWIRStatus, operation=EventStatus_ECUM_E_IMPROPER_CALLER.SetWIRStatus
        OIE_EventStatus_ECUM_E_RAM_CHECK_FAILED_SetWIRStatus: start-on-event=SetWIRStatus, operation=EventStatus_ECUM_E_RAM_CHECK_FAILED.SetWIRStatus
        OIE_EventStatus_EEP_E_COMPARE_FAILED_SetWIRStatus: start-on-event=SetWIRStatus, operation=EventStatus_EEP_E_COMPARE_FAILED.SetWIRStatus
        OIE_EventStatus_EEP_E_ERASE_FAILED_SetWIRStatus: start-on-event=SetWIRStatus, operation=EventStatus_EEP_E_ERASE_FAILED.SetWIRStatus
        OIE_EventStatus_EEP_E_READ_FAILED_SetWIRStatus: start-on-event=SetWIRStatus, operation=EventStatus_EEP_E_READ_FAILED.SetWIRStatus
        OIE_EventStatus_EEP_E_WRITE_FAILED_SetWIRStatus: start-on-event=SetWIRStatus, operation=EventStatus_EEP_E_WRITE_FAILED.SetWIRStatus
        OIE_EventStatus_ETHSM_E_LINK_DOWN_SetWIRStatus: start-on-event=SetWIRStatus, operation=EventStatus_ETHSM_E_LINK_DOWN.SetWIRStatus
        OIE_EventStatus_ETHTRCV_E_ACCESS_SetWIRStatus: start-on-event=SetWIRStatus, operation=EventStatus_ETHTRCV_E_ACCESS.SetWIRStatus
        OIE_EventStatus_ETH_E_ACCESS_SetWIRStatus: start-on-event=SetWIRStatus, operation=EventStatus_ETH_E_ACCESS.SetWIRStatus
        OIE_EventStatus_ETH_E_ALIGNMENT_SetWIRStatus: start-on-event=SetWIRStatus, operation=EventStatus_ETH_E_ALIGNMENT.SetWIRStatus
        OIE_EventStatus_ETH_E_CRC_SetWIRStatus: start-on-event=SetWIRStatus, operation=EventStatus_ETH_E_CRC.SetWIRStatus
        OIE_EventStatus_ETH_E_LATECOLLISON_SetWIRStatus: start-on-event=SetWIRStatus, operation=EventStatus_ETH_E_LATECOLLISON.SetWIRStatus
        OIE_EventStatus_ETH_E_MULTIPLECOLLISION_SetWIRStatus: start-on-event=SetWIRStatus, operation=EventStatus_ETH_E_MULTIPLECOLLISION.SetWIRStatus
        OIE_EventStatus_ETH_E_OVERSIZEFRAME_SetWIRStatus: start-on-event=SetWIRStatus, operation=EventStatus_ETH_E_OVERSIZEFRAME.SetWIRStatus
        OIE_EventStatus_ETH_E_RX_FRAMES_LOST_SetWIRStatus: start-on-event=SetWIRStatus, operation=EventStatus_ETH_E_RX_FRAMES_LOST.SetWIRStatus
        OIE_EventStatus_ETH_E_SINGLECOLLISION_SetWIRStatus: start-on-event=SetWIRStatus, operation=EventStatus_ETH_E_SINGLECOLLISION.SetWIRStatus
        OIE_EventStatus_ETH_E_UNDERSIZRFRAME_SetWIRStatus: start-on-event=SetWIRStatus, operation=EventStatus_ETH_E_UNDERSIZRFRAME.SetWIRStatus
        OIE_EventStatus_FEE_E_GC_ERASE_SetWIRStatus: start-on-event=SetWIRStatus, operation=EventStatus_FEE_E_GC_ERASE.SetWIRStatus
        OIE_EventStatus_FEE_E_GC_INIT_SetWIRStatus: start-on-event=SetWIRStatus, operation=EventStatus_FEE_E_GC_INIT.SetWIRStatus
        OIE_EventStatus_FEE_E_GC_READ_SetWIRStatus: start-on-event=SetWIRStatus, operation=EventStatus_FEE_E_GC_READ.SetWIRStatus
        OIE_EventStatus_FEE_E_GC_TRIG_SetWIRStatus: start-on-event=SetWIRStatus, operation=EventStatus_FEE_E_GC_TRIG.SetWIRStatus
        OIE_EventStatus_FEE_E_GC_WRITE_SetWIRStatus: start-on-event=SetWIRStatus, operation=EventStatus_FEE_E_GC_WRITE.SetWIRStatus
        OIE_EventStatus_FEE_E_INVALIDATE_SetWIRStatus: start-on-event=SetWIRStatus, operation=EventStatus_FEE_E_INVALIDATE.SetWIRStatus
        OIE_EventStatus_FEE_E_READ_SetWIRStatus: start-on-event=SetWIRStatus, operation=EventStatus_FEE_E_READ.SetWIRStatus
        OIE_EventStatus_FEE_E_UNCONFIG_BLK_EXCEEDED_SetWIRStatus: start-on-event=SetWIRStatus, operation=EventStatus_FEE_E_UNCONFIG_BLK_EXCEEDED.SetWIRStatus
        OIE_EventStatus_FEE_E_WRITE_CYCLES_EXHAUSTED_SetWIRStatus: start-on-event=SetWIRStatus, operation=EventStatus_FEE_E_WRITE_CYCLES_EXHAUSTED.SetWIRStatus
        OIE_EventStatus_FEE_E_WRITE_SetWIRStatus: start-on-event=SetWIRStatus, operation=EventStatus_FEE_E_WRITE.SetWIRStatus
        OIE_EventStatus_FLS_E_COMPARE_FAILED_SetWIRStatus: start-on-event=SetWIRStatus, operation=EventStatus_FLS_E_COMPARE_FAILED.SetWIRStatus
        OIE_EventStatus_FLS_E_ERASE_FAILED_SetWIRStatus: start-on-event=SetWIRStatus, operation=EventStatus_FLS_E_ERASE_FAILED.SetWIRStatus
        OIE_EventStatus_FLS_E_READ_FAILED_SetWIRStatus: start-on-event=SetWIRStatus, operation=EventStatus_FLS_E_READ_FAILED.SetWIRStatus
        OIE_EventStatus_FLS_E_UNEXPECTED_FLASH_ID_SetWIRStatus: start-on-event=SetWIRStatus, operation=EventStatus_FLS_E_UNEXPECTED_FLASH_ID.SetWIRStatus
        OIE_EventStatus_FLS_E_WRITE_FAILED_SetWIRStatus: start-on-event=SetWIRStatus, operation=EventStatus_FLS_E_WRITE_FAILED.SetWIRStatus
        OIE_EventStatus_IOHWAB_E_BUSY_SetWIRStatus: start-on-event=SetWIRStatus, operation=EventStatus_IOHWAB_E_BUSY.SetWIRStatus
        OIE_EventStatus_IOHWAB_E_PROC_FAIL_SetWIRStatus: start-on-event=SetWIRStatus, operation=EventStatus_IOHWAB_E_PROC_FAIL.SetWIRStatus
        OIE_EventStatus_IOHWAB_E_SETUP_FAIL_SetWIRStatus: start-on-event=SetWIRStatus, operation=EventStatus_IOHWAB_E_SETUP_FAIL.SetWIRStatus
        OIE_EventStatus_IOHWAB_E_WRONG_PARAM_SetWIRStatus: start-on-event=SetWIRStatus, operation=EventStatus_IOHWAB_E_WRONG_PARAM.SetWIRStatus
        OIE_EventStatus_IOHWAB_E_WRONG_SETTING_SetWIRStatus: start-on-event=SetWIRStatus, operation=EventStatus_IOHWAB_E_WRONG_SETTING.SetWIRStatus
        OIE_EventStatus_IOHWAB_E_WRONG_STATE_SetWIRStatus: start-on-event=SetWIRStatus, operation=EventStatus_IOHWAB_E_WRONG_STATE.SetWIRStatus
        OIE_EventStatus_MCU_E_CCU6_CLC_DISABLE_ERR_SetWIRStatus: start-on-event=SetWIRStatus, operation=EventStatus_MCU_E_CCU6_CLC_DISABLE_ERR.SetWIRStatus
        OIE_EventStatus_MCU_E_CCU6_CLC_ENABLE_ERR_SetWIRStatus: start-on-event=SetWIRStatus, operation=EventStatus_MCU_E_CCU6_CLC_ENABLE_ERR.SetWIRStatus
        OIE_EventStatus_MCU_E_CCUCON_UPDATE_ERR_SetWIRStatus: start-on-event=SetWIRStatus, operation=EventStatus_MCU_E_CCUCON_UPDATE_ERR.SetWIRStatus
        OIE_EventStatus_MCU_E_CLOCK_FAILURE_SetWIRStatus: start-on-event=SetWIRStatus, operation=EventStatus_MCU_E_CLOCK_FAILURE.SetWIRStatus
        OIE_EventStatus_MCU_E_CONVCTRL_CLC_DISABLE_ERR_SetWIRStatus: start-on-event=SetWIRStatus, operation=EventStatus_MCU_E_CONVCTRL_CLC_DISABLE_ERR.SetWIRStatus
        OIE_EventStatus_MCU_E_CONVCTRL_CLC_ENABLE_ERR_SetWIRStatus: start-on-event=SetWIRStatus, operation=EventStatus_MCU_E_CONVCTRL_CLC_ENABLE_ERR.SetWIRStatus
        OIE_EventStatus_MCU_E_GPT12_CLC_DISABLE_ERR_SetWIRStatus: start-on-event=SetWIRStatus, operation=EventStatus_MCU_E_GPT12_CLC_DISABLE_ERR.SetWIRStatus
        OIE_EventStatus_MCU_E_GPT12_CLC_ENABLE_ERR_SetWIRStatus: start-on-event=SetWIRStatus, operation=EventStatus_MCU_E_GPT12_CLC_ENABLE_ERR.SetWIRStatus
        OIE_EventStatus_MCU_E_GTM_CLC_DISABLE_ERR_SetWIRStatus: start-on-event=SetWIRStatus, operation=EventStatus_MCU_E_GTM_CLC_DISABLE_ERR.SetWIRStatus
        OIE_EventStatus_MCU_E_GTM_CLC_ENABLE_ERR_SetWIRStatus: start-on-event=SetWIRStatus, operation=EventStatus_MCU_E_GTM_CLC_ENABLE_ERR.SetWIRStatus
        OIE_EventStatus_MCU_E_OSC_FAILURE_SetWIRStatus: start-on-event=SetWIRStatus, operation=EventStatus_MCU_E_OSC_FAILURE.SetWIRStatus
        OIE_EventStatus_MCU_E_PERIPHERAL_PLL_LOCK_LOSS_SetWIRStatus: start-on-event=SetWIRStatus, operation=EventStatus_MCU_E_PERIPHERAL_PLL_LOCK_LOSS.SetWIRStatus
        OIE_EventStatus_MCU_E_PERIPHERAL_PLL_TIMEOUT_ERR_SetWIRStatus: start-on-event=SetWIRStatus, operation=EventStatus_MCU_E_PERIPHERAL_PLL_TIMEOUT_ERR.SetWIRStatus
        OIE_EventStatus_MCU_E_PMSWCR_UPDATE_ERR_SetWIRStatus: start-on-event=SetWIRStatus, operation=EventStatus_MCU_E_PMSWCR_UPDATE_ERR.SetWIRStatus
        OIE_EventStatus_MCU_E_SYSTEM_PLL_LOCK_LOSS_SetWIRStatus: start-on-event=SetWIRStatus, operation=EventStatus_MCU_E_SYSTEM_PLL_LOCK_LOSS.SetWIRStatus
        OIE_EventStatus_MCU_E_SYSTEM_PLL_TIMEOUT_ERR_SetWIRStatus: start-on-event=SetWIRStatus, operation=EventStatus_MCU_E_SYSTEM_PLL_TIMEOUT_ERR.SetWIRStatus
        OIE_EventStatus_NVM_E_INTEGRITY_FAILED_SetWIRStatus: start-on-event=SetWIRStatus, operation=EventStatus_NVM_E_INTEGRITY_FAILED.SetWIRStatus
        OIE_EventStatus_NVM_E_LOSS_OF_REDUNDANCY_SetWIRStatus: start-on-event=SetWIRStatus, operation=EventStatus_NVM_E_LOSS_OF_REDUNDANCY.SetWIRStatus
        OIE_EventStatus_NVM_E_QUEUE_OVERFLOW_SetWIRStatus: start-on-event=SetWIRStatus, operation=EventStatus_NVM_E_QUEUE_OVERFLOW.SetWIRStatus
        OIE_EventStatus_NVM_E_REQ_FAILED_SetWIRStatus: start-on-event=SetWIRStatus, operation=EventStatus_NVM_E_REQ_FAILED.SetWIRStatus
        OIE_EventStatus_NVM_E_VERIFY_FAILED_SetWIRStatus: start-on-event=SetWIRStatus, operation=EventStatus_NVM_E_VERIFY_FAILED.SetWIRStatus
        OIE_EventStatus_NVM_E_WRITE_PROTECTED_SetWIRStatus: start-on-event=SetWIRStatus, operation=EventStatus_NVM_E_WRITE_PROTECTED.SetWIRStatus
        OIE_EventStatus_NVM_E_WRONG_BLOCK_ID_SetWIRStatus: start-on-event=SetWIRStatus, operation=EventStatus_NVM_E_WRONG_BLOCK_ID.SetWIRStatus
        OIE_EventStatus_SPI_E_HARDWARE_ERROR_SetWIRStatus: start-on-event=SetWIRStatus, operation=EventStatus_SPI_E_HARDWARE_ERROR.SetWIRStatus
        OIE_EventStatus_WDGM_E_IMPROPER_CALLER_SetWIRStatus: start-on-event=SetWIRStatus, operation=EventStatus_WDGM_E_IMPROPER_CALLER.SetWIRStatus
        OIE_EventStatus_WDGM_E_MONITORING_SetWIRStatus: start-on-event=SetWIRStatus, operation=EventStatus_WDGM_E_MONITORING.SetWIRStatus
        OIE_EventStatus_WDGM_E_SET_MODE_SetWIRStatus: start-on-event=SetWIRStatus, operation=EventStatus_WDGM_E_SET_MODE.SetWIRStatus
        OIE_EventStatus_WDG_76_ACW_E_DISABLE_REJECTED_SetWIRStatus: start-on-event=SetWIRStatus, operation=EventStatus_WDG_76_ACW_E_DISABLE_REJECTED.SetWIRStatus
        OIE_EventStatus_WDG_76_ACW_E_MODE_FAILED_SetWIRStatus: start-on-event=SetWIRStatus, operation=EventStatus_WDG_76_ACW_E_MODE_FAILED.SetWIRStatus
